// *************************************************************************** *
// *                                                                           *
// * Description:         CANDB File                                           *
// * Generated at:        2025-01-24 12:56                                     *
// * System:              SDB22436                                             *
// * Variant:             L946_ADCU9_ZCUDM                                     *
// * Network:             BodyExposedCAN                                       *
// *                                                                           *
// *************************************************************************** *
VERSION "BodyExposedCAN"

NS_ :

BS_ :

BU_ :  ETC HCML HCMR ZCUD

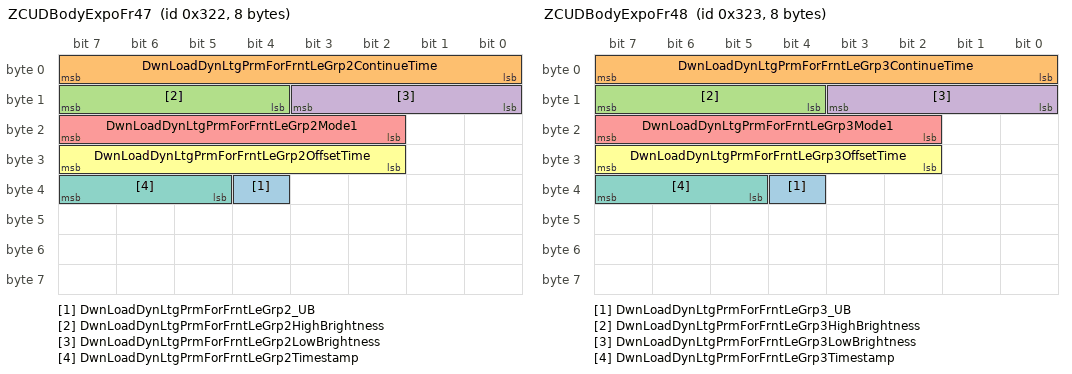
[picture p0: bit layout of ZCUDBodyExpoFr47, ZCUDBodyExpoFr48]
BO_ 802 ZCUDBodyExpoFr47 : 8 ZCUD
 SG_ DwnLoadDynLtgPrmForFrntLeGrp2_UB : 36|1@0+ (1,0) [0|1] "" HCML
 SG_ DwnLoadDynLtgPrmForFrntLeGrp2ContinueTime : 7|8@0+ (1.0,0.0) [0.0|255.0] "Unitless" HCML
 SG_ DwnLoadDynLtgPrmForFrntLeGrp2HighBrightness : 15|4@0+ (1.0,0.0) [0.0|10.0] "Unitless" HCML
 SG_ DwnLoadDynLtgPrmForFrntLeGrp2LowBrightness : 11|4@0+ (1.0,0.0) [0.0|10.0] "Unitless" HCML
 SG_ DwnLoadDynLtgPrmForFrntLeGrp2Mode1 : 23|6@0+ (1,0) [0|63] "" HCML
 SG_ DwnLoadDynLtgPrmForFrntLeGrp2OffsetTime : 31|6@0+ (1.0,0.0) [0.0|63.0] "Unitless" HCML
 SG_ DwnLoadDynLtgPrmForFrntLeGrp2Timestamp : 39|3@0+ (1.0,0.0) [0.0|7.0] "Unitless" HCML

BO_ 803 ZCUDBodyExpoFr48 : 8 ZCUD
 SG_ DwnLoadDynLtgPrmForFrntLeGrp3_UB : 36|1@0+ (1,0) [0|1] "" HCML
 SG_ DwnLoadDynLtgPrmForFrntLeGrp3ContinueTime : 7|8@0+ (1.0,0.0) [0.0|255.0] "Unitless" HCML
 SG_ DwnLoadDynLtgPrmForFrntLeGrp3HighBrightness : 15|4@0+ (1.0,0.0) [0.0|10.0] "Unitless" HCML
 SG_ DwnLoadDynLtgPrmForFrntLeGrp3LowBrightness : 11|4@0+ (1.0,0.0) [0.0|10.0] "Unitless" HCML
 SG_ DwnLoadDynLtgPrmForFrntLeGrp3Mode1 : 23|6@0+ (1,0) [0|63] "" HCML
 SG_ DwnLoadDynLtgPrmForFrntLeGrp3OffsetTime : 31|6@0+ (1.0,0.0) [0.0|63.0] "Unitless" HCML
 SG_ DwnLoadDynLtgPrmForFrntLeGrp3Timestamp : 39|3@0+ (1.0,0.0) [0.0|7.0] "Unitless" HCML

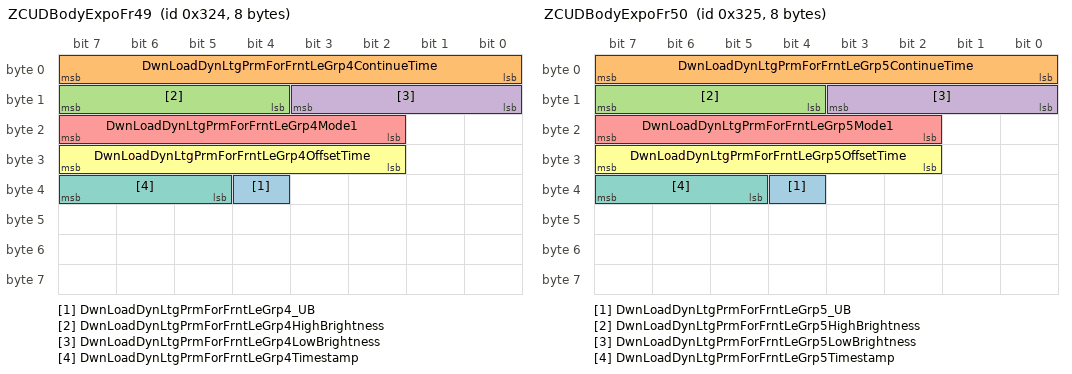
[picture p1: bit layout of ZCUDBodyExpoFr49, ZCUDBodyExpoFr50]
BO_ 804 ZCUDBodyExpoFr49 : 8 ZCUD
 SG_ DwnLoadDynLtgPrmForFrntLeGrp4_UB : 36|1@0+ (1,0) [0|1] "" HCML
 SG_ DwnLoadDynLtgPrmForFrntLeGrp4ContinueTime : 7|8@0+ (1.0,0.0) [0.0|255.0] "Unitless" HCML
 SG_ DwnLoadDynLtgPrmForFrntLeGrp4HighBrightness : 15|4@0+ (1.0,0.0) [0.0|10.0] "Unitless" HCML
 SG_ DwnLoadDynLtgPrmForFrntLeGrp4LowBrightness : 11|4@0+ (1.0,0.0) [0.0|10.0] "Unitless" HCML
 SG_ DwnLoadDynLtgPrmForFrntLeGrp4Mode1 : 23|6@0+ (1,0) [0|63] "" HCML
 SG_ DwnLoadDynLtgPrmForFrntLeGrp4OffsetTime : 31|6@0+ (1.0,0.0) [0.0|63.0] "Unitless" HCML
 SG_ DwnLoadDynLtgPrmForFrntLeGrp4Timestamp : 39|3@0+ (1.0,0.0) [0.0|7.0] "Unitless" HCML

BO_ 805 ZCUDBodyExpoFr50 : 8 ZCUD
 SG_ DwnLoadDynLtgPrmForFrntLeGrp5_UB : 36|1@0+ (1,0) [0|1] "" HCML
 SG_ DwnLoadDynLtgPrmForFrntLeGrp5ContinueTime : 7|8@0+ (1.0,0.0) [0.0|255.0] "Unitless" HCML
 SG_ DwnLoadDynLtgPrmForFrntLeGrp5HighBrightness : 15|4@0+ (1.0,0.0) [0.0|10.0] "Unitless" HCML
 SG_ DwnLoadDynLtgPrmForFrntLeGrp5LowBrightness : 11|4@0+ (1.0,0.0) [0.0|10.0] "Unitless" HCML
 SG_ DwnLoadDynLtgPrmForFrntLeGrp5Mode1 : 23|6@0+ (1,0) [0|63] "" HCML
 SG_ DwnLoadDynLtgPrmForFrntLeGrp5OffsetTime : 31|6@0+ (1.0,0.0) [0.0|63.0] "Unitless" HCML
 SG_ DwnLoadDynLtgPrmForFrntLeGrp5Timestamp : 39|3@0+ (1.0,0.0) [0.0|7.0] "Unitless" HCML

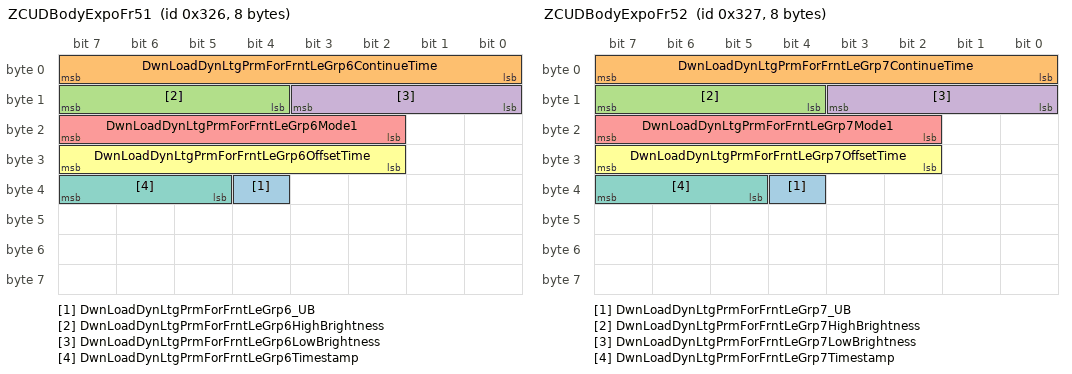
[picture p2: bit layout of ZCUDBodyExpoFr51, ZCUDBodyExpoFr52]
BO_ 806 ZCUDBodyExpoFr51 : 8 ZCUD
 SG_ DwnLoadDynLtgPrmForFrntLeGrp6_UB : 36|1@0+ (1,0) [0|1] "" HCML
 SG_ DwnLoadDynLtgPrmForFrntLeGrp6ContinueTime : 7|8@0+ (1.0,0.0) [0.0|255.0] "Unitless" HCML
 SG_ DwnLoadDynLtgPrmForFrntLeGrp6HighBrightness : 15|4@0+ (1.0,0.0) [0.0|10.0] "Unitless" HCML
 SG_ DwnLoadDynLtgPrmForFrntLeGrp6LowBrightness : 11|4@0+ (1.0,0.0) [0.0|10.0] "Unitless" HCML
 SG_ DwnLoadDynLtgPrmForFrntLeGrp6Mode1 : 23|6@0+ (1,0) [0|63] "" HCML
 SG_ DwnLoadDynLtgPrmForFrntLeGrp6OffsetTime : 31|6@0+ (1.0,0.0) [0.0|63.0] "Unitless" HCML
 SG_ DwnLoadDynLtgPrmForFrntLeGrp6Timestamp : 39|3@0+ (1.0,0.0) [0.0|7.0] "Unitless" HCML

BO_ 807 ZCUDBodyExpoFr52 : 8 ZCUD
 SG_ DwnLoadDynLtgPrmForFrntLeGrp7_UB : 36|1@0+ (1,0) [0|1] "" HCML
 SG_ DwnLoadDynLtgPrmForFrntLeGrp7ContinueTime : 7|8@0+ (1.0,0.0) [0.0|255.0] "Unitless" HCML
 SG_ DwnLoadDynLtgPrmForFrntLeGrp7HighBrightness : 15|4@0+ (1.0,0.0) [0.0|10.0] "Unitless" HCML
 SG_ DwnLoadDynLtgPrmForFrntLeGrp7LowBrightness : 11|4@0+ (1.0,0.0) [0.0|10.0] "Unitless" HCML
 SG_ DwnLoadDynLtgPrmForFrntLeGrp7Mode1 : 23|6@0+ (1,0) [0|63] "" HCML
 SG_ DwnLoadDynLtgPrmForFrntLeGrp7OffsetTime : 31|6@0+ (1.0,0.0) [0.0|63.0] "Unitless" HCML
 SG_ DwnLoadDynLtgPrmForFrntLeGrp7Timestamp : 39|3@0+ (1.0,0.0) [0.0|7.0] "Unitless" HCML

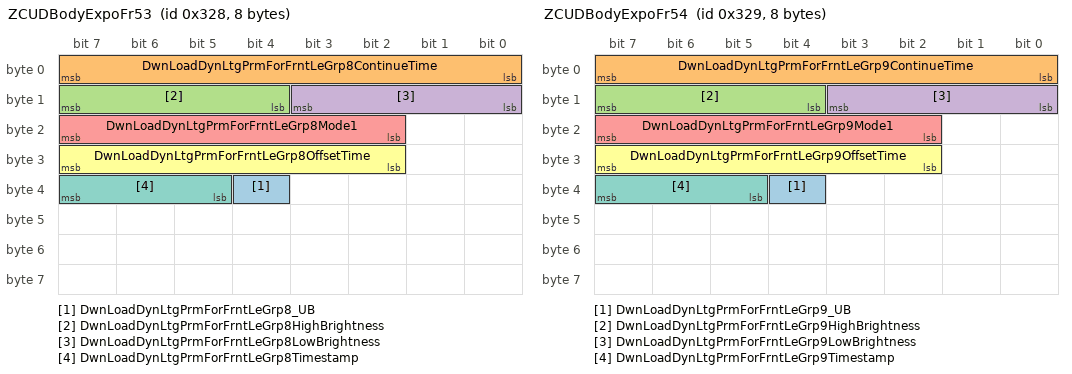
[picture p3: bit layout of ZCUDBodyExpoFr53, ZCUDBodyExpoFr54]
BO_ 808 ZCUDBodyExpoFr53 : 8 ZCUD
 SG_ DwnLoadDynLtgPrmForFrntLeGrp8_UB : 36|1@0+ (1,0) [0|1] "" HCML
 SG_ DwnLoadDynLtgPrmForFrntLeGrp8ContinueTime : 7|8@0+ (1.0,0.0) [0.0|255.0] "Unitless" HCML
 SG_ DwnLoadDynLtgPrmForFrntLeGrp8HighBrightness : 15|4@0+ (1.0,0.0) [0.0|10.0] "Unitless" HCML
 SG_ DwnLoadDynLtgPrmForFrntLeGrp8LowBrightness : 11|4@0+ (1.0,0.0) [0.0|10.0] "Unitless" HCML
 SG_ DwnLoadDynLtgPrmForFrntLeGrp8Mode1 : 23|6@0+ (1,0) [0|63] "" HCML
 SG_ DwnLoadDynLtgPrmForFrntLeGrp8OffsetTime : 31|6@0+ (1.0,0.0) [0.0|63.0] "Unitless" HCML
 SG_ DwnLoadDynLtgPrmForFrntLeGrp8Timestamp : 39|3@0+ (1.0,0.0) [0.0|7.0] "Unitless" HCML

BO_ 809 ZCUDBodyExpoFr54 : 8 ZCUD
 SG_ DwnLoadDynLtgPrmForFrntLeGrp9_UB : 36|1@0+ (1,0) [0|1] "" HCML
 SG_ DwnLoadDynLtgPrmForFrntLeGrp9ContinueTime : 7|8@0+ (1.0,0.0) [0.0|255.0] "Unitless" HCML
 SG_ DwnLoadDynLtgPrmForFrntLeGrp9HighBrightness : 15|4@0+ (1.0,0.0) [0.0|10.0] "Unitless" HCML
 SG_ DwnLoadDynLtgPrmForFrntLeGrp9LowBrightness : 11|4@0+ (1.0,0.0) [0.0|10.0] "Unitless" HCML
 SG_ DwnLoadDynLtgPrmForFrntLeGrp9Mode1 : 23|6@0+ (1,0) [0|63] "" HCML
 SG_ DwnLoadDynLtgPrmForFrntLeGrp9OffsetTime : 31|6@0+ (1.0,0.0) [0.0|63.0] "Unitless" HCML
 SG_ DwnLoadDynLtgPrmForFrntLeGrp9Timestamp : 39|3@0+ (1.0,0.0) [0.0|7.0] "Unitless" HCML

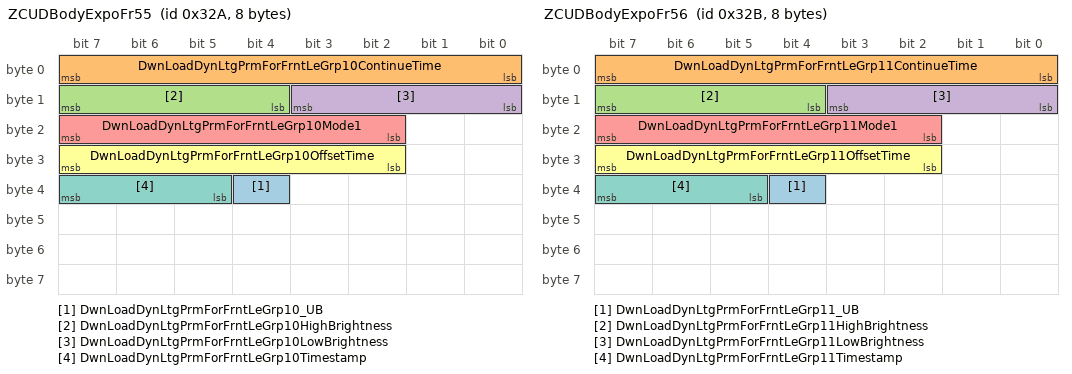
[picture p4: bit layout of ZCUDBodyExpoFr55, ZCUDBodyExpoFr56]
BO_ 810 ZCUDBodyExpoFr55 : 8 ZCUD
 SG_ DwnLoadDynLtgPrmForFrntLeGrp10_UB : 36|1@0+ (1,0) [0|1] "" HCML
 SG_ DwnLoadDynLtgPrmForFrntLeGrp10ContinueTime : 7|8@0+ (1.0,0.0) [0.0|255.0] "Unitless" HCML
 SG_ DwnLoadDynLtgPrmForFrntLeGrp10HighBrightness : 15|4@0+ (1.0,0.0) [0.0|10.0] "Unitless" HCML
 SG_ DwnLoadDynLtgPrmForFrntLeGrp10LowBrightness : 11|4@0+ (1.0,0.0) [0.0|10.0] "Unitless" HCML
 SG_ DwnLoadDynLtgPrmForFrntLeGrp10Mode1 : 23|6@0+ (1,0) [0|63] "" HCML
 SG_ DwnLoadDynLtgPrmForFrntLeGrp10OffsetTime : 31|6@0+ (1.0,0.0) [0.0|63.0] "Unitless" HCML
 SG_ DwnLoadDynLtgPrmForFrntLeGrp10Timestamp : 39|3@0+ (1.0,0.0) [0.0|7.0] "Unitless" HCML

BO_ 811 ZCUDBodyExpoFr56 : 8 ZCUD
 SG_ DwnLoadDynLtgPrmForFrntLeGrp11_UB : 36|1@0+ (1,0) [0|1] "" HCML
 SG_ DwnLoadDynLtgPrmForFrntLeGrp11ContinueTime : 7|8@0+ (1.0,0.0) [0.0|255.0] "Unitless" HCML
 SG_ DwnLoadDynLtgPrmForFrntLeGrp11HighBrightness : 15|4@0+ (1.0,0.0) [0.0|10.0] "Unitless" HCML
 SG_ DwnLoadDynLtgPrmForFrntLeGrp11LowBrightness : 11|4@0+ (1.0,0.0) [0.0|10.0] "Unitless" HCML
 SG_ DwnLoadDynLtgPrmForFrntLeGrp11Mode1 : 23|6@0+ (1,0) [0|63] "" HCML
 SG_ DwnLoadDynLtgPrmForFrntLeGrp11OffsetTime : 31|6@0+ (1.0,0.0) [0.0|63.0] "Unitless" HCML
 SG_ DwnLoadDynLtgPrmForFrntLeGrp11Timestamp : 39|3@0+ (1.0,0.0) [0.0|7.0] "Unitless" HCML

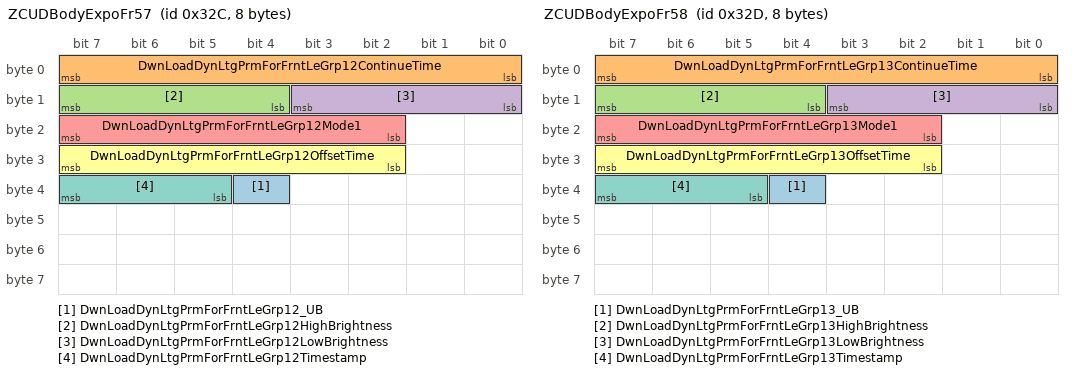
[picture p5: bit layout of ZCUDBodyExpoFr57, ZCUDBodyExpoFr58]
BO_ 812 ZCUDBodyExpoFr57 : 8 ZCUD
 SG_ DwnLoadDynLtgPrmForFrntLeGrp12_UB : 36|1@0+ (1,0) [0|1] "" HCML
 SG_ DwnLoadDynLtgPrmForFrntLeGrp12ContinueTime : 7|8@0+ (1.0,0.0) [0.0|255.0] "Unitless" HCML
 SG_ DwnLoadDynLtgPrmForFrntLeGrp12HighBrightness : 15|4@0+ (1.0,0.0) [0.0|10.0] "Unitless" HCML
 SG_ DwnLoadDynLtgPrmForFrntLeGrp12LowBrightness : 11|4@0+ (1.0,0.0) [0.0|10.0] "Unitless" HCML
 SG_ DwnLoadDynLtgPrmForFrntLeGrp12Mode1 : 23|6@0+ (1,0) [0|63] "" HCML
 SG_ DwnLoadDynLtgPrmForFrntLeGrp12OffsetTime : 31|6@0+ (1.0,0.0) [0.0|63.0] "Unitless" HCML
 SG_ DwnLoadDynLtgPrmForFrntLeGrp12Timestamp : 39|3@0+ (1.0,0.0) [0.0|7.0] "Unitless" HCML

BO_ 813 ZCUDBodyExpoFr58 : 8 ZCUD
 SG_ DwnLoadDynLtgPrmForFrntLeGrp13_UB : 36|1@0+ (1,0) [0|1] "" HCML
 SG_ DwnLoadDynLtgPrmForFrntLeGrp13ContinueTime : 7|8@0+ (1.0,0.0) [0.0|255.0] "Unitless" HCML
 SG_ DwnLoadDynLtgPrmForFrntLeGrp13HighBrightness : 15|4@0+ (1.0,0.0) [0.0|10.0] "Unitless" HCML
 SG_ DwnLoadDynLtgPrmForFrntLeGrp13LowBrightness : 11|4@0+ (1.0,0.0) [0.0|10.0] "Unitless" HCML
 SG_ DwnLoadDynLtgPrmForFrntLeGrp13Mode1 : 23|6@0+ (1,0) [0|63] "" HCML
 SG_ DwnLoadDynLtgPrmForFrntLeGrp13OffsetTime : 31|6@0+ (1.0,0.0) [0.0|63.0] "Unitless" HCML
 SG_ DwnLoadDynLtgPrmForFrntLeGrp13Timestamp : 39|3@0+ (1.0,0.0) [0.0|7.0] "Unitless" HCML

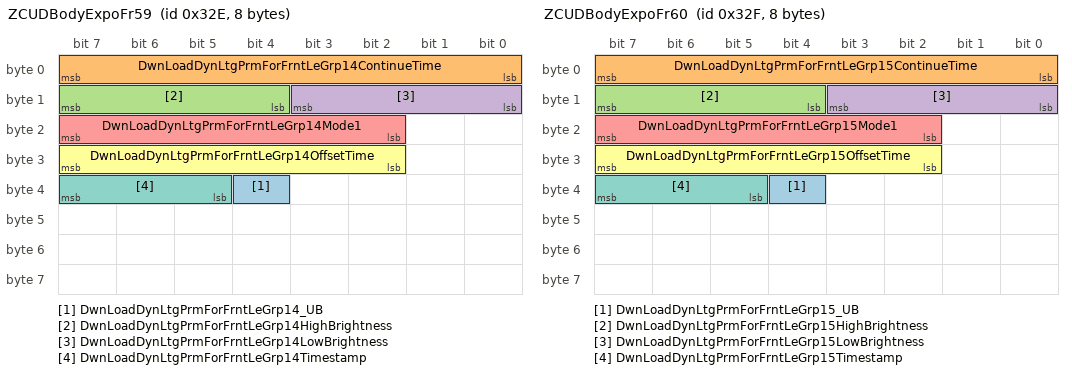
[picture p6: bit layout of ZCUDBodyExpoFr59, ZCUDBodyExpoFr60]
BO_ 814 ZCUDBodyExpoFr59 : 8 ZCUD
 SG_ DwnLoadDynLtgPrmForFrntLeGrp14_UB : 36|1@0+ (1,0) [0|1] "" HCML
 SG_ DwnLoadDynLtgPrmForFrntLeGrp14ContinueTime : 7|8@0+ (1.0,0.0) [0.0|255.0] "Unitless" HCML
 SG_ DwnLoadDynLtgPrmForFrntLeGrp14HighBrightness : 15|4@0+ (1.0,0.0) [0.0|10.0] "Unitless" HCML
 SG_ DwnLoadDynLtgPrmForFrntLeGrp14LowBrightness : 11|4@0+ (1.0,0.0) [0.0|10.0] "Unitless" HCML
 SG_ DwnLoadDynLtgPrmForFrntLeGrp14Mode1 : 23|6@0+ (1,0) [0|63] "" HCML
 SG_ DwnLoadDynLtgPrmForFrntLeGrp14OffsetTime : 31|6@0+ (1.0,0.0) [0.0|63.0] "Unitless" HCML
 SG_ DwnLoadDynLtgPrmForFrntLeGrp14Timestamp : 39|3@0+ (1.0,0.0) [0.0|7.0] "Unitless" HCML

BO_ 815 ZCUDBodyExpoFr60 : 8 ZCUD
 SG_ DwnLoadDynLtgPrmForFrntLeGrp15_UB : 36|1@0+ (1,0) [0|1] "" HCML
 SG_ DwnLoadDynLtgPrmForFrntLeGrp15ContinueTime : 7|8@0+ (1.0,0.0) [0.0|255.0] "Unitless" HCML
 SG_ DwnLoadDynLtgPrmForFrntLeGrp15HighBrightness : 15|4@0+ (1.0,0.0) [0.0|10.0] "Unitless" HCML
 SG_ DwnLoadDynLtgPrmForFrntLeGrp15LowBrightness : 11|4@0+ (1.0,0.0) [0.0|10.0] "Unitless" HCML
 SG_ DwnLoadDynLtgPrmForFrntLeGrp15Mode1 : 23|6@0+ (1,0) [0|63] "" HCML
 SG_ DwnLoadDynLtgPrmForFrntLeGrp15OffsetTime : 31|6@0+ (1.0,0.0) [0.0|63.0] "Unitless" HCML
 SG_ DwnLoadDynLtgPrmForFrntLeGrp15Timestamp : 39|3@0+ (1.0,0.0) [0.0|7.0] "Unitless" HCML

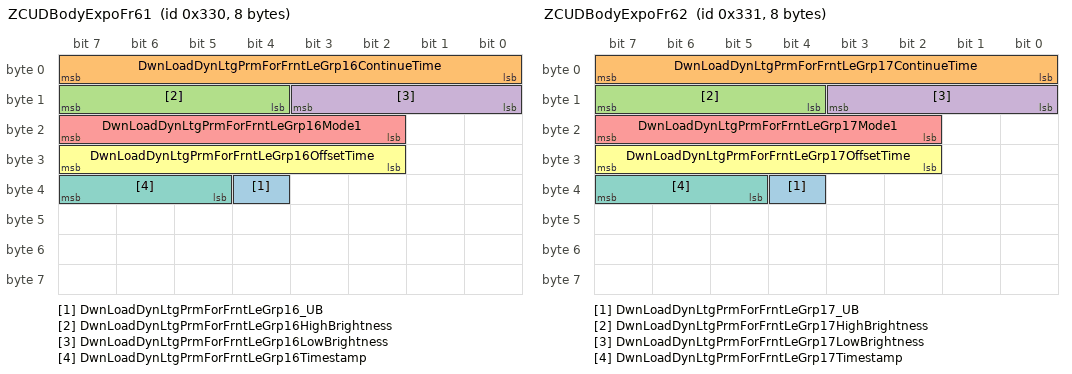
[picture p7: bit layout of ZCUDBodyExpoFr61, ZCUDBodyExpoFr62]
BO_ 816 ZCUDBodyExpoFr61 : 8 ZCUD
 SG_ DwnLoadDynLtgPrmForFrntLeGrp16_UB : 36|1@0+ (1,0) [0|1] "" HCML
 SG_ DwnLoadDynLtgPrmForFrntLeGrp16ContinueTime : 7|8@0+ (1.0,0.0) [0.0|255.0] "Unitless" HCML
 SG_ DwnLoadDynLtgPrmForFrntLeGrp16HighBrightness : 15|4@0+ (1.0,0.0) [0.0|10.0] "Unitless" HCML
 SG_ DwnLoadDynLtgPrmForFrntLeGrp16LowBrightness : 11|4@0+ (1.0,0.0) [0.0|10.0] "Unitless" HCML
 SG_ DwnLoadDynLtgPrmForFrntLeGrp16Mode1 : 23|6@0+ (1,0) [0|63] "" HCML
 SG_ DwnLoadDynLtgPrmForFrntLeGrp16OffsetTime : 31|6@0+ (1.0,0.0) [0.0|63.0] "Unitless" HCML
 SG_ DwnLoadDynLtgPrmForFrntLeGrp16Timestamp : 39|3@0+ (1.0,0.0) [0.0|7.0] "Unitless" HCML

BO_ 817 ZCUDBodyExpoFr62 : 8 ZCUD
 SG_ DwnLoadDynLtgPrmForFrntLeGrp17_UB : 36|1@0+ (1,0) [0|1] "" HCML
 SG_ DwnLoadDynLtgPrmForFrntLeGrp17ContinueTime : 7|8@0+ (1.0,0.0) [0.0|255.0] "Unitless" HCML
 SG_ DwnLoadDynLtgPrmForFrntLeGrp17HighBrightness : 15|4@0+ (1.0,0.0) [0.0|10.0] "Unitless" HCML
 SG_ DwnLoadDynLtgPrmForFrntLeGrp17LowBrightness : 11|4@0+ (1.0,0.0) [0.0|10.0] "Unitless" HCML
 SG_ DwnLoadDynLtgPrmForFrntLeGrp17Mode1 : 23|6@0+ (1,0) [0|63] "" HCML
 SG_ DwnLoadDynLtgPrmForFrntLeGrp17OffsetTime : 31|6@0+ (1.0,0.0) [0.0|63.0] "Unitless" HCML
 SG_ DwnLoadDynLtgPrmForFrntLeGrp17Timestamp : 39|3@0+ (1.0,0.0) [0.0|7.0] "Unitless" HCML

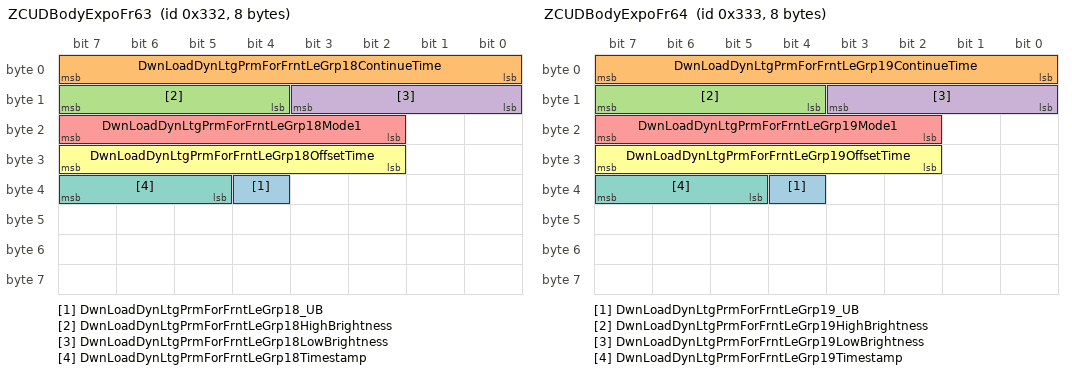
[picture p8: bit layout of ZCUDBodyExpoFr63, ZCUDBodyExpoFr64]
BO_ 818 ZCUDBodyExpoFr63 : 8 ZCUD
 SG_ DwnLoadDynLtgPrmForFrntLeGrp18_UB : 36|1@0+ (1,0) [0|1] "" HCML
 SG_ DwnLoadDynLtgPrmForFrntLeGrp18ContinueTime : 7|8@0+ (1.0,0.0) [0.0|255.0] "Unitless" HCML
 SG_ DwnLoadDynLtgPrmForFrntLeGrp18HighBrightness : 15|4@0+ (1.0,0.0) [0.0|10.0] "Unitless" HCML
 SG_ DwnLoadDynLtgPrmForFrntLeGrp18LowBrightness : 11|4@0+ (1.0,0.0) [0.0|10.0] "Unitless" HCML
 SG_ DwnLoadDynLtgPrmForFrntLeGrp18Mode1 : 23|6@0+ (1,0) [0|63] "" HCML
 SG_ DwnLoadDynLtgPrmForFrntLeGrp18OffsetTime : 31|6@0+ (1.0,0.0) [0.0|63.0] "Unitless" HCML
 SG_ DwnLoadDynLtgPrmForFrntLeGrp18Timestamp : 39|3@0+ (1.0,0.0) [0.0|7.0] "Unitless" HCML

BO_ 819 ZCUDBodyExpoFr64 : 8 ZCUD
 SG_ DwnLoadDynLtgPrmForFrntLeGrp19_UB : 36|1@0+ (1,0) [0|1] "" HCML
 SG_ DwnLoadDynLtgPrmForFrntLeGrp19ContinueTime : 7|8@0+ (1.0,0.0) [0.0|255.0] "Unitless" HCML
 SG_ DwnLoadDynLtgPrmForFrntLeGrp19HighBrightness : 15|4@0+ (1.0,0.0) [0.0|10.0] "Unitless" HCML
 SG_ DwnLoadDynLtgPrmForFrntLeGrp19LowBrightness : 11|4@0+ (1.0,0.0) [0.0|10.0] "Unitless" HCML
 SG_ DwnLoadDynLtgPrmForFrntLeGrp19Mode1 : 23|6@0+ (1,0) [0|63] "" HCML
 SG_ DwnLoadDynLtgPrmForFrntLeGrp19OffsetTime : 31|6@0+ (1.0,0.0) [0.0|63.0] "Unitless" HCML
 SG_ DwnLoadDynLtgPrmForFrntLeGrp19Timestamp : 39|3@0+ (1.0,0.0) [0.0|7.0] "Unitless" HCML

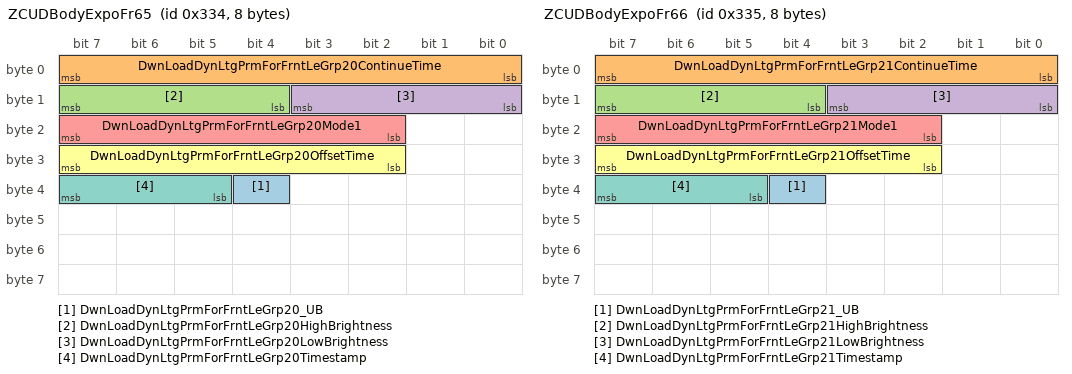
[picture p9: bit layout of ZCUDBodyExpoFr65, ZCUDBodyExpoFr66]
BO_ 820 ZCUDBodyExpoFr65 : 8 ZCUD
 SG_ DwnLoadDynLtgPrmForFrntLeGrp20_UB : 36|1@0+ (1,0) [0|1] "" HCML
 SG_ DwnLoadDynLtgPrmForFrntLeGrp20ContinueTime : 7|8@0+ (1.0,0.0) [0.0|255.0] "Unitless" HCML
 SG_ DwnLoadDynLtgPrmForFrntLeGrp20HighBrightness : 15|4@0+ (1.0,0.0) [0.0|10.0] "Unitless" HCML
 SG_ DwnLoadDynLtgPrmForFrntLeGrp20LowBrightness : 11|4@0+ (1.0,0.0) [0.0|10.0] "Unitless" HCML
 SG_ DwnLoadDynLtgPrmForFrntLeGrp20Mode1 : 23|6@0+ (1,0) [0|63] "" HCML
 SG_ DwnLoadDynLtgPrmForFrntLeGrp20OffsetTime : 31|6@0+ (1.0,0.0) [0.0|63.0] "Unitless" HCML
 SG_ DwnLoadDynLtgPrmForFrntLeGrp20Timestamp : 39|3@0+ (1.0,0.0) [0.0|7.0] "Unitless" HCML

BO_ 821 ZCUDBodyExpoFr66 : 8 ZCUD
 SG_ DwnLoadDynLtgPrmForFrntLeGrp21_UB : 36|1@0+ (1,0) [0|1] "" HCML
 SG_ DwnLoadDynLtgPrmForFrntLeGrp21ContinueTime : 7|8@0+ (1.0,0.0) [0.0|255.0] "Unitless" HCML
 SG_ DwnLoadDynLtgPrmForFrntLeGrp21HighBrightness : 15|4@0+ (1.0,0.0) [0.0|10.0] "Unitless" HCML
 SG_ DwnLoadDynLtgPrmForFrntLeGrp21LowBrightness : 11|4@0+ (1.0,0.0) [0.0|10.0] "Unitless" HCML
 SG_ DwnLoadDynLtgPrmForFrntLeGrp21Mode1 : 23|6@0+ (1,0) [0|63] "" HCML
 SG_ DwnLoadDynLtgPrmForFrntLeGrp21OffsetTime : 31|6@0+ (1.0,0.0) [0.0|63.0] "Unitless" HCML
 SG_ DwnLoadDynLtgPrmForFrntLeGrp21Timestamp : 39|3@0+ (1.0,0.0) [0.0|7.0] "Unitless" HCML

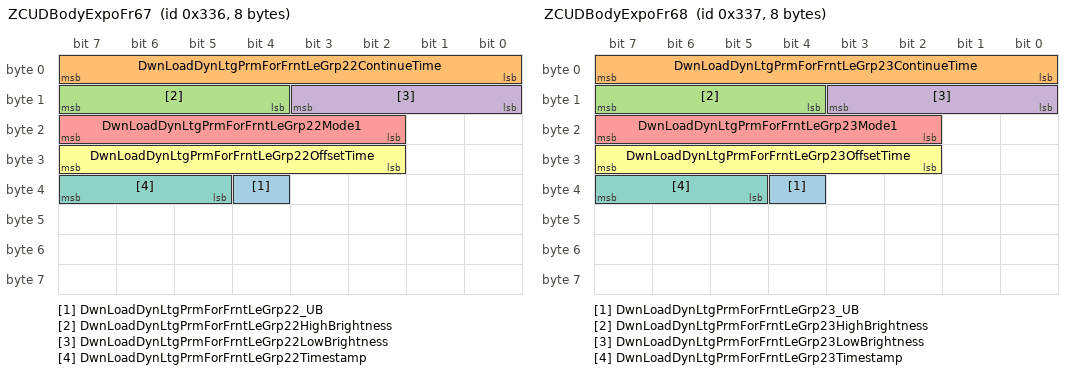
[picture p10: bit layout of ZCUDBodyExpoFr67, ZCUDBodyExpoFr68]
BO_ 822 ZCUDBodyExpoFr67 : 8 ZCUD
 SG_ DwnLoadDynLtgPrmForFrntLeGrp22_UB : 36|1@0+ (1,0) [0|1] "" HCML
 SG_ DwnLoadDynLtgPrmForFrntLeGrp22ContinueTime : 7|8@0+ (1.0,0.0) [0.0|255.0] "Unitless" HCML
 SG_ DwnLoadDynLtgPrmForFrntLeGrp22HighBrightness : 15|4@0+ (1.0,0.0) [0.0|10.0] "Unitless" HCML
 SG_ DwnLoadDynLtgPrmForFrntLeGrp22LowBrightness : 11|4@0+ (1.0,0.0) [0.0|10.0] "Unitless" HCML
 SG_ DwnLoadDynLtgPrmForFrntLeGrp22Mode1 : 23|6@0+ (1,0) [0|63] "" HCML
 SG_ DwnLoadDynLtgPrmForFrntLeGrp22OffsetTime : 31|6@0+ (1.0,0.0) [0.0|63.0] "Unitless" HCML
 SG_ DwnLoadDynLtgPrmForFrntLeGrp22Timestamp : 39|3@0+ (1.0,0.0) [0.0|7.0] "Unitless" HCML

BO_ 823 ZCUDBodyExpoFr68 : 8 ZCUD
 SG_ DwnLoadDynLtgPrmForFrntLeGrp23_UB : 36|1@0+ (1,0) [0|1] "" HCML
 SG_ DwnLoadDynLtgPrmForFrntLeGrp23ContinueTime : 7|8@0+ (1.0,0.0) [0.0|255.0] "Unitless" HCML
 SG_ DwnLoadDynLtgPrmForFrntLeGrp23HighBrightness : 15|4@0+ (1.0,0.0) [0.0|10.0] "Unitless" HCML
 SG_ DwnLoadDynLtgPrmForFrntLeGrp23LowBrightness : 11|4@0+ (1.0,0.0) [0.0|10.0] "Unitless" HCML
 SG_ DwnLoadDynLtgPrmForFrntLeGrp23Mode1 : 23|6@0+ (1,0) [0|63] "" HCML
 SG_ DwnLoadDynLtgPrmForFrntLeGrp23OffsetTime : 31|6@0+ (1.0,0.0) [0.0|63.0] "Unitless" HCML
 SG_ DwnLoadDynLtgPrmForFrntLeGrp23Timestamp : 39|3@0+ (1.0,0.0) [0.0|7.0] "Unitless" HCML

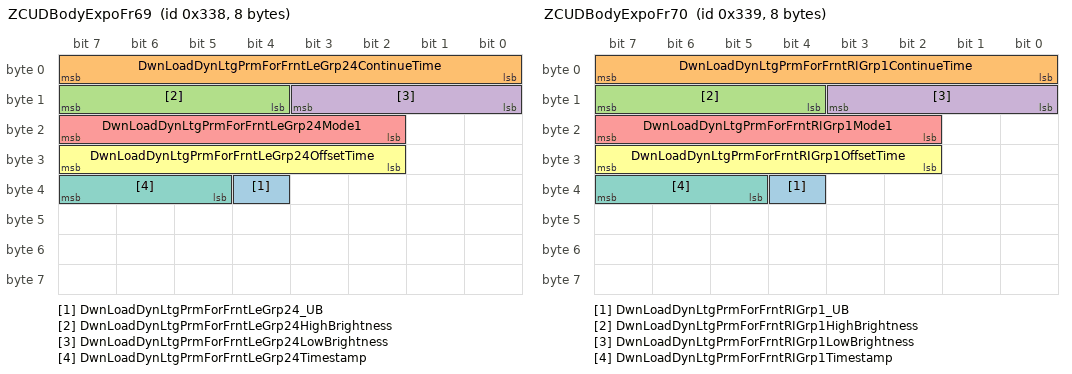
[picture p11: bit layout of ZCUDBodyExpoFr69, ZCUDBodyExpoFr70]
BO_ 824 ZCUDBodyExpoFr69 : 8 ZCUD
 SG_ DwnLoadDynLtgPrmForFrntLeGrp24_UB : 36|1@0+ (1,0) [0|1] "" HCML
 SG_ DwnLoadDynLtgPrmForFrntLeGrp24ContinueTime : 7|8@0+ (1.0,0.0) [0.0|255.0] "Unitless" HCML
 SG_ DwnLoadDynLtgPrmForFrntLeGrp24HighBrightness : 15|4@0+ (1.0,0.0) [0.0|10.0] "Unitless" HCML
 SG_ DwnLoadDynLtgPrmForFrntLeGrp24LowBrightness : 11|4@0+ (1.0,0.0) [0.0|10.0] "Unitless" HCML
 SG_ DwnLoadDynLtgPrmForFrntLeGrp24Mode1 : 23|6@0+ (1,0) [0|63] "" HCML
 SG_ DwnLoadDynLtgPrmForFrntLeGrp24OffsetTime : 31|6@0+ (1.0,0.0) [0.0|63.0] "Unitless" HCML
 SG_ DwnLoadDynLtgPrmForFrntLeGrp24Timestamp : 39|3@0+ (1.0,0.0) [0.0|7.0] "Unitless" HCML

BO_ 825 ZCUDBodyExpoFr70 : 8 ZCUD
 SG_ DwnLoadDynLtgPrmForFrntRIGrp1_UB : 36|1@0+ (1,0) [0|1] "" HCMR
 SG_ DwnLoadDynLtgPrmForFrntRIGrp1ContinueTime : 7|8@0+ (1.0,0.0) [0.0|255.0] "Unitless" HCMR
 SG_ DwnLoadDynLtgPrmForFrntRIGrp1HighBrightness : 15|4@0+ (1.0,0.0) [0.0|10.0] "Unitless" HCMR
 SG_ DwnLoadDynLtgPrmForFrntRIGrp1LowBrightness : 11|4@0+ (1.0,0.0) [0.0|10.0] "Unitless" HCMR
 SG_ DwnLoadDynLtgPrmForFrntRIGrp1Mode1 : 23|6@0+ (1,0) [0|63] "" HCMR
 SG_ DwnLoadDynLtgPrmForFrntRIGrp1OffsetTime : 31|6@0+ (1.0,0.0) [0.0|63.0] "Unitless" HCMR
 SG_ DwnLoadDynLtgPrmForFrntRIGrp1Timestamp : 39|3@0+ (1.0,0.0) [0.0|7.0] "Unitless" HCMR

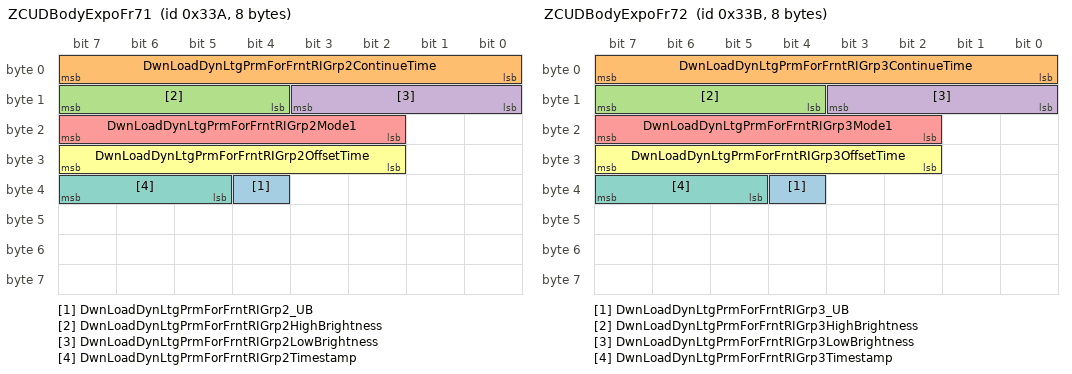
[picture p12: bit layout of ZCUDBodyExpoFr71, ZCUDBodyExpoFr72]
BO_ 826 ZCUDBodyExpoFr71 : 8 ZCUD
 SG_ DwnLoadDynLtgPrmForFrntRIGrp2_UB : 36|1@0+ (1,0) [0|1] "" HCMR
 SG_ DwnLoadDynLtgPrmForFrntRIGrp2ContinueTime : 7|8@0+ (1.0,0.0) [0.0|255.0] "Unitless" HCMR
 SG_ DwnLoadDynLtgPrmForFrntRIGrp2HighBrightness : 15|4@0+ (1.0,0.0) [0.0|10.0] "Unitless" HCMR
 SG_ DwnLoadDynLtgPrmForFrntRIGrp2LowBrightness : 11|4@0+ (1.0,0.0) [0.0|10.0] "Unitless" HCMR
 SG_ DwnLoadDynLtgPrmForFrntRIGrp2Mode1 : 23|6@0+ (1,0) [0|63] "" HCMR
 SG_ DwnLoadDynLtgPrmForFrntRIGrp2OffsetTime : 31|6@0+ (1.0,0.0) [0.0|63.0] "Unitless" HCMR
 SG_ DwnLoadDynLtgPrmForFrntRIGrp2Timestamp : 39|3@0+ (1.0,0.0) [0.0|7.0] "Unitless" HCMR

BO_ 827 ZCUDBodyExpoFr72 : 8 ZCUD
 SG_ DwnLoadDynLtgPrmForFrntRIGrp3_UB : 36|1@0+ (1,0) [0|1] "" HCMR
 SG_ DwnLoadDynLtgPrmForFrntRIGrp3ContinueTime : 7|8@0+ (1.0,0.0) [0.0|255.0] "Unitless" HCMR
 SG_ DwnLoadDynLtgPrmForFrntRIGrp3HighBrightness : 15|4@0+ (1.0,0.0) [0.0|10.0] "Unitless" HCMR
 SG_ DwnLoadDynLtgPrmForFrntRIGrp3LowBrightness : 11|4@0+ (1.0,0.0) [0.0|10.0] "Unitless" HCMR
 SG_ DwnLoadDynLtgPrmForFrntRIGrp3Mode1 : 23|6@0+ (1,0) [0|63] "" HCMR
 SG_ DwnLoadDynLtgPrmForFrntRIGrp3OffsetTime : 31|6@0+ (1.0,0.0) [0.0|63.0] "Unitless" HCMR
 SG_ DwnLoadDynLtgPrmForFrntRIGrp3Timestamp : 39|3@0+ (1.0,0.0) [0.0|7.0] "Unitless" HCMR

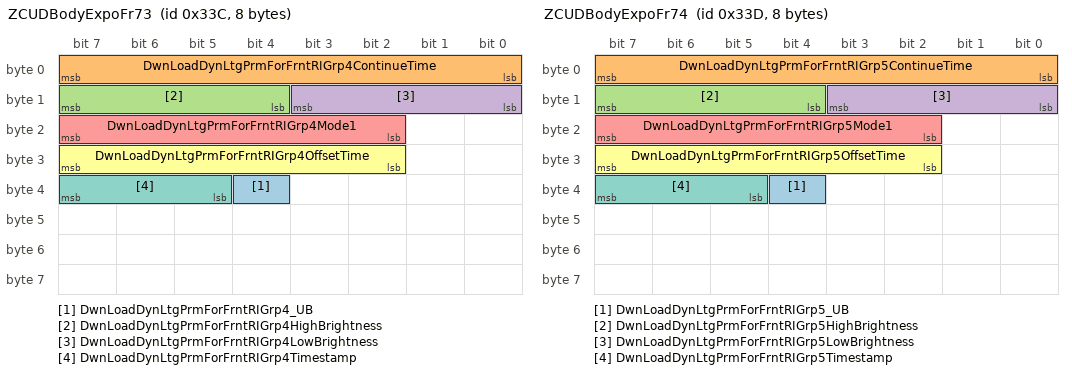
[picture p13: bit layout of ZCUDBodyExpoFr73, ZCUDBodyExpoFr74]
BO_ 828 ZCUDBodyExpoFr73 : 8 ZCUD
 SG_ DwnLoadDynLtgPrmForFrntRIGrp4_UB : 36|1@0+ (1,0) [0|1] "" HCMR
 SG_ DwnLoadDynLtgPrmForFrntRIGrp4ContinueTime : 7|8@0+ (1.0,0.0) [0.0|255.0] "Unitless" HCMR
 SG_ DwnLoadDynLtgPrmForFrntRIGrp4HighBrightness : 15|4@0+ (1.0,0.0) [0.0|10.0] "Unitless" HCMR
 SG_ DwnLoadDynLtgPrmForFrntRIGrp4LowBrightness : 11|4@0+ (1.0,0.0) [0.0|10.0] "Unitless" HCMR
 SG_ DwnLoadDynLtgPrmForFrntRIGrp4Mode1 : 23|6@0+ (1,0) [0|63] "" HCMR
 SG_ DwnLoadDynLtgPrmForFrntRIGrp4OffsetTime : 31|6@0+ (1.0,0.0) [0.0|63.0] "Unitless" HCMR
 SG_ DwnLoadDynLtgPrmForFrntRIGrp4Timestamp : 39|3@0+ (1.0,0.0) [0.0|7.0] "Unitless" HCMR

BO_ 829 ZCUDBodyExpoFr74 : 8 ZCUD
 SG_ DwnLoadDynLtgPrmForFrntRIGrp5_UB : 36|1@0+ (1,0) [0|1] "" HCMR
 SG_ DwnLoadDynLtgPrmForFrntRIGrp5ContinueTime : 7|8@0+ (1.0,0.0) [0.0|255.0] "Unitless" HCMR
 SG_ DwnLoadDynLtgPrmForFrntRIGrp5HighBrightness : 15|4@0+ (1.0,0.0) [0.0|10.0] "Unitless" HCMR
 SG_ DwnLoadDynLtgPrmForFrntRIGrp5LowBrightness : 11|4@0+ (1.0,0.0) [0.0|10.0] "Unitless" HCMR
 SG_ DwnLoadDynLtgPrmForFrntRIGrp5Mode1 : 23|6@0+ (1,0) [0|63] "" HCMR
 SG_ DwnLoadDynLtgPrmForFrntRIGrp5OffsetTime : 31|6@0+ (1.0,0.0) [0.0|63.0] "Unitless" HCMR
 SG_ DwnLoadDynLtgPrmForFrntRIGrp5Timestamp : 39|3@0+ (1.0,0.0) [0.0|7.0] "Unitless" HCMR

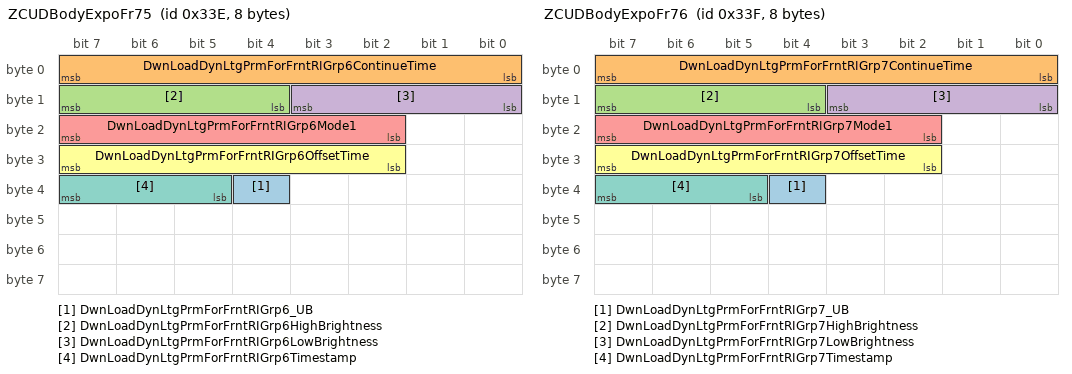
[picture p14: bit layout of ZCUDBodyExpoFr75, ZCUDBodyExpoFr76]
BO_ 830 ZCUDBodyExpoFr75 : 8 ZCUD
 SG_ DwnLoadDynLtgPrmForFrntRIGrp6_UB : 36|1@0+ (1,0) [0|1] "" HCMR
 SG_ DwnLoadDynLtgPrmForFrntRIGrp6ContinueTime : 7|8@0+ (1.0,0.0) [0.0|255.0] "Unitless" HCMR
 SG_ DwnLoadDynLtgPrmForFrntRIGrp6HighBrightness : 15|4@0+ (1.0,0.0) [0.0|10.0] "Unitless" HCMR
 SG_ DwnLoadDynLtgPrmForFrntRIGrp6LowBrightness : 11|4@0+ (1.0,0.0) [0.0|10.0] "Unitless" HCMR
 SG_ DwnLoadDynLtgPrmForFrntRIGrp6Mode1 : 23|6@0+ (1,0) [0|63] "" HCMR
 SG_ DwnLoadDynLtgPrmForFrntRIGrp6OffsetTime : 31|6@0+ (1.0,0.0) [0.0|63.0] "Unitless" HCMR
 SG_ DwnLoadDynLtgPrmForFrntRIGrp6Timestamp : 39|3@0+ (1.0,0.0) [0.0|7.0] "Unitless" HCMR

BO_ 831 ZCUDBodyExpoFr76 : 8 ZCUD
 SG_ DwnLoadDynLtgPrmForFrntRIGrp7_UB : 36|1@0+ (1,0) [0|1] "" HCMR
 SG_ DwnLoadDynLtgPrmForFrntRIGrp7ContinueTime : 7|8@0+ (1.0,0.0) [0.0|255.0] "Unitless" HCMR
 SG_ DwnLoadDynLtgPrmForFrntRIGrp7HighBrightness : 15|4@0+ (1.0,0.0) [0.0|10.0] "Unitless" HCMR
 SG_ DwnLoadDynLtgPrmForFrntRIGrp7LowBrightness : 11|4@0+ (1.0,0.0) [0.0|10.0] "Unitless" HCMR
 SG_ DwnLoadDynLtgPrmForFrntRIGrp7Mode1 : 23|6@0+ (1,0) [0|63] "" HCMR
 SG_ DwnLoadDynLtgPrmForFrntRIGrp7OffsetTime : 31|6@0+ (1.0,0.0) [0.0|63.0] "Unitless" HCMR
 SG_ DwnLoadDynLtgPrmForFrntRIGrp7Timestamp : 39|3@0+ (1.0,0.0) [0.0|7.0] "Unitless" HCMR

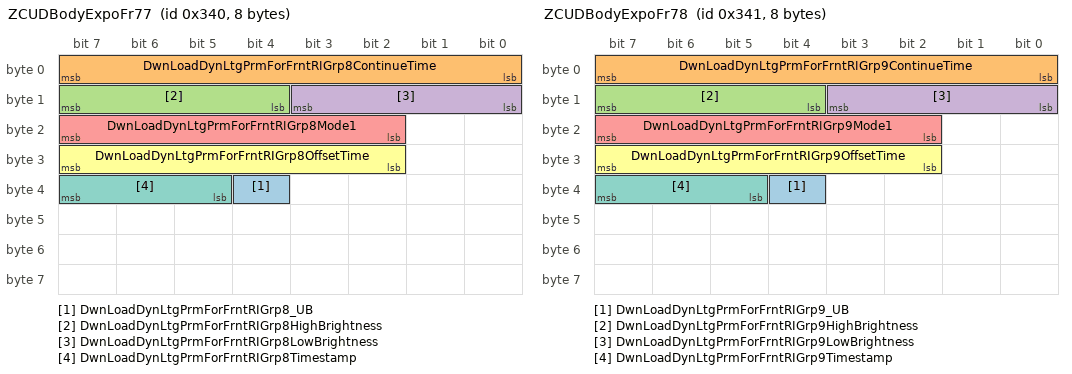
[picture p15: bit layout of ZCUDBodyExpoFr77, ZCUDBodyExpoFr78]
BO_ 832 ZCUDBodyExpoFr77 : 8 ZCUD
 SG_ DwnLoadDynLtgPrmForFrntRIGrp8_UB : 36|1@0+ (1,0) [0|1] "" HCMR
 SG_ DwnLoadDynLtgPrmForFrntRIGrp8ContinueTime : 7|8@0+ (1.0,0.0) [0.0|255.0] "Unitless" HCMR
 SG_ DwnLoadDynLtgPrmForFrntRIGrp8HighBrightness : 15|4@0+ (1.0,0.0) [0.0|10.0] "Unitless" HCMR
 SG_ DwnLoadDynLtgPrmForFrntRIGrp8LowBrightness : 11|4@0+ (1.0,0.0) [0.0|10.0] "Unitless" HCMR
 SG_ DwnLoadDynLtgPrmForFrntRIGrp8Mode1 : 23|6@0+ (1,0) [0|63] "" HCMR
 SG_ DwnLoadDynLtgPrmForFrntRIGrp8OffsetTime : 31|6@0+ (1.0,0.0) [0.0|63.0] "Unitless" HCMR
 SG_ DwnLoadDynLtgPrmForFrntRIGrp8Timestamp : 39|3@0+ (1.0,0.0) [0.0|7.0] "Unitless" HCMR

BO_ 833 ZCUDBodyExpoFr78 : 8 ZCUD
 SG_ DwnLoadDynLtgPrmForFrntRIGrp9_UB : 36|1@0+ (1,0) [0|1] "" HCMR
 SG_ DwnLoadDynLtgPrmForFrntRIGrp9ContinueTime : 7|8@0+ (1.0,0.0) [0.0|255.0] "Unitless" HCMR
 SG_ DwnLoadDynLtgPrmForFrntRIGrp9HighBrightness : 15|4@0+ (1.0,0.0) [0.0|10.0] "Unitless" HCMR
 SG_ DwnLoadDynLtgPrmForFrntRIGrp9LowBrightness : 11|4@0+ (1.0,0.0) [0.0|10.0] "Unitless" HCMR
 SG_ DwnLoadDynLtgPrmForFrntRIGrp9Mode1 : 23|6@0+ (1,0) [0|63] "" HCMR
 SG_ DwnLoadDynLtgPrmForFrntRIGrp9OffsetTime : 31|6@0+ (1.0,0.0) [0.0|63.0] "Unitless" HCMR
 SG_ DwnLoadDynLtgPrmForFrntRIGrp9Timestamp : 39|3@0+ (1.0,0.0) [0.0|7.0] "Unitless" HCMR

BO_ 272 ZCUDBodyExpoFr79 : 8 ZCUD
 SG_ SphDvExtnLg : 50|3@0+ (1,0) [0|7] "" HCML,HCMR
 SG_ SphDvExtnLg_UB : 51|1@0+ (1,0) [0|1] "" HCML,HCMR

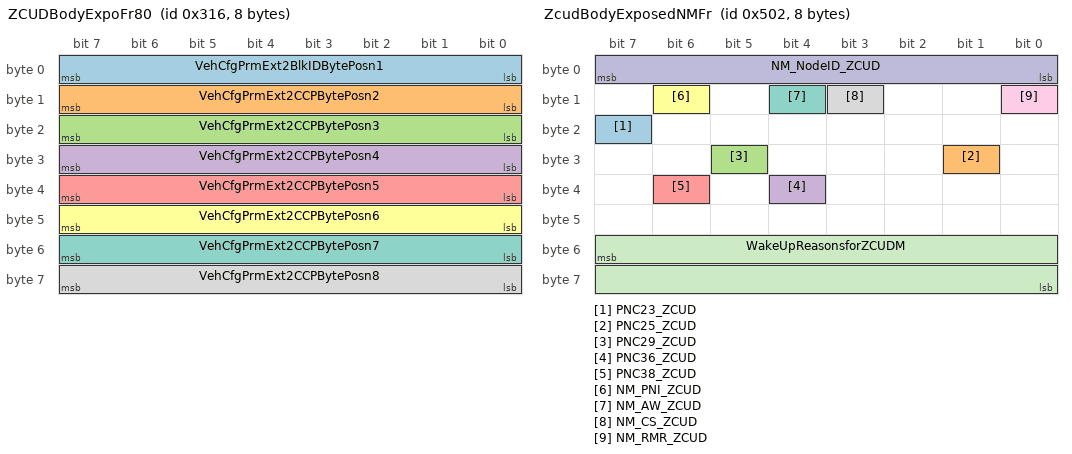
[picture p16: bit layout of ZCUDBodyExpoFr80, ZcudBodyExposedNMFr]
BO_ 790 ZCUDBodyExpoFr80 : 8 ZCUD
 SG_ VehCfgPrmExt2BlkIDBytePosn1 : 7|8@0+ (1.0,0.0) [0.0|255.0] "Unitless" HCML,HCMR
 SG_ VehCfgPrmExt2CCPBytePosn2 : 15|8@0+ (1.0,0.0) [0.0|255.0] "Unitless" HCML,HCMR
 SG_ VehCfgPrmExt2CCPBytePosn3 : 23|8@0+ (1.0,0.0) [0.0|255.0] "Unitless" HCML,HCMR
 SG_ VehCfgPrmExt2CCPBytePosn4 : 31|8@0+ (1.0,0.0) [0.0|255.0] "Unitless" HCML,HCMR
 SG_ VehCfgPrmExt2CCPBytePosn5 : 39|8@0+ (1.0,0.0) [0.0|255.0] "Unitless" HCML,HCMR
 SG_ VehCfgPrmExt2CCPBytePosn6 : 47|8@0+ (1.0,0.0) [0.0|255.0] "Unitless" HCML,HCMR
 SG_ VehCfgPrmExt2CCPBytePosn7 : 55|8@0+ (1.0,0.0) [0.0|255.0] "Unitless" HCML,HCMR
 SG_ VehCfgPrmExt2CCPBytePosn8 : 63|8@0+ (1.0,0.0) [0.0|255.0] "Unitless" HCML,HCMR

BO_ 1282 ZcudBodyExposedNMFr : 8 ZCUD
 SG_ PNC23_ZCUD : 23|1@0+ (1,0) [0|0] "" Vector__XXX
 SG_ PNC25_ZCUD : 25|1@0+ (1,0) [0|0] "" Vector__XXX
 SG_ PNC29_ZCUD : 29|1@0+ (1,0) [0|0] "" Vector__XXX
 SG_ PNC36_ZCUD : 36|1@0+ (1,0) [0|0] "" Vector__XXX
 SG_ PNC38_ZCUD : 38|1@0+ (1,0) [0|0] "" Vector__XXX
 SG_ NM_PNI_ZCUD : 14|1@0+ (1,0) [0|0] "" Vector__XXX
 SG_ NM_AW_ZCUD : 12|1@0+ (1,0) [0|0] "" Vector__XXX
 SG_ NM_CS_ZCUD : 11|1@0+ (1,0) [0|0] "" Vector__XXX
 SG_ NM_RMR_ZCUD : 8|1@0+ (1,0) [0|0] "" Vector__XXX
 SG_ NM_NodeID_ZCUD : 7|8@0+ (1,0) [0|0] "" Vector__XXX

 SG_ WakeUpReasonsforZCUDM : 55|16@0+ (1,0) [0|65535] "" Vector__XXX

BO_ 2047 ZcudToAllFuncBodyCanExposedDiagReqFrame : 8 ZCUD

BO_ 1971 ZcudToHcmlBodyCanExposedDiagReqFrame : 8 ZCUD

BO_ 1972 ZcudToHcmrBodyCanExposedDiagReqFrame : 8 ZCUD

BO_ 1970 ZcudToRcmBodyCanExposedDiagReqFrame : 8 ZCUD

CM_ SG_ 802 DwnLoadDynLtgPrmForFrntLeGrp2ContinueTime "Light Show Continue Time Parameter 2";
CM_ SG_ 802 DwnLoadDynLtgPrmForFrntLeGrp2HighBrightness "Light Show Upper Brightness Parameter 2";
CM_ SG_ 802 DwnLoadDynLtgPrmForFrntLeGrp2LowBrightness "Light Show Lower Brightness Parameter 2";
CM_ SG_ 802 DwnLoadDynLtgPrmForFrntLeGrp2Mode1 "Light Show Mode Parameter 2";
CM_ SG_ 802 DwnLoadDynLtgPrmForFrntLeGrp2OffsetTime "Light Show Offset Time Parameter 2";
CM_ SG_ 802 DwnLoadDynLtgPrmForFrntLeGrp2Timestamp "Light Show time stamp 2";
CM_ SG_ 803 DwnLoadDynLtgPrmForFrntLeGrp3ContinueTime "Light Show Continue Time Parameter 2";
CM_ SG_ 803 DwnLoadDynLtgPrmForFrntLeGrp3HighBrightness "Light Show Upper Brightness Parameter 2";
CM_ SG_ 803 DwnLoadDynLtgPrmForFrntLeGrp3LowBrightness "Light Show Lower Brightness Parameter 2";
CM_ SG_ 803 DwnLoadDynLtgPrmForFrntLeGrp3Mode1 "Light Show Mode Parameter 2";
CM_ SG_ 803 DwnLoadDynLtgPrmForFrntLeGrp3OffsetTime "Light Show Offset Time Parameter 2";
CM_ SG_ 803 DwnLoadDynLtgPrmForFrntLeGrp3Timestamp "Light Show time stamp 2";
CM_ SG_ 804 DwnLoadDynLtgPrmForFrntLeGrp4ContinueTime "Light Show Continue Time Parameter 2";
CM_ SG_ 804 DwnLoadDynLtgPrmForFrntLeGrp4HighBrightness "Light Show Upper Brightness Parameter 2";
CM_ SG_ 804 DwnLoadDynLtgPrmForFrntLeGrp4LowBrightness "Light Show Lower Brightness Parameter 2";
CM_ SG_ 804 DwnLoadDynLtgPrmForFrntLeGrp4Mode1 "Light Show Mode Parameter 2";
CM_ SG_ 804 DwnLoadDynLtgPrmForFrntLeGrp4OffsetTime "Light Show Offset Time Parameter 2";
CM_ SG_ 804 DwnLoadDynLtgPrmForFrntLeGrp4Timestamp "Light Show time stamp 2";
CM_ SG_ 805 DwnLoadDynLtgPrmForFrntLeGrp5ContinueTime "Light Show Continue Time Parameter 2";
CM_ SG_ 805 DwnLoadDynLtgPrmForFrntLeGrp5HighBrightness "Light Show Upper Brightness Parameter 2";
CM_ SG_ 805 DwnLoadDynLtgPrmForFrntLeGrp5LowBrightness "Light Show Lower Brightness Parameter 2";
CM_ SG_ 805 DwnLoadDynLtgPrmForFrntLeGrp5Mode1 "Light Show Mode Parameter 2";
CM_ SG_ 805 DwnLoadDynLtgPrmForFrntLeGrp5OffsetTime "Light Show Offset Time Parameter 2";
CM_ SG_ 805 DwnLoadDynLtgPrmForFrntLeGrp5Timestamp "Light Show time stamp 2";
CM_ SG_ 806 DwnLoadDynLtgPrmForFrntLeGrp6ContinueTime "Light Show Continue Time Parameter 2";
CM_ SG_ 806 DwnLoadDynLtgPrmForFrntLeGrp6HighBrightness "Light Show Upper Brightness Parameter 2";
CM_ SG_ 806 DwnLoadDynLtgPrmForFrntLeGrp6LowBrightness "Light Show Lower Brightness Parameter 2";
CM_ SG_ 806 DwnLoadDynLtgPrmForFrntLeGrp6Mode1 "Light Show Mode Parameter 2";
CM_ SG_ 806 DwnLoadDynLtgPrmForFrntLeGrp6OffsetTime "Light Show Offset Time Parameter 2";
CM_ SG_ 806 DwnLoadDynLtgPrmForFrntLeGrp6Timestamp "Light Show time stamp 2";
CM_ SG_ 807 DwnLoadDynLtgPrmForFrntLeGrp7ContinueTime "Light Show Continue Time Parameter 2";
CM_ SG_ 807 DwnLoadDynLtgPrmForFrntLeGrp7HighBrightness "Light Show Upper Brightness Parameter 2";
CM_ SG_ 807 DwnLoadDynLtgPrmForFrntLeGrp7LowBrightness "Light Show Lower Brightness Parameter 2";
CM_ SG_ 807 DwnLoadDynLtgPrmForFrntLeGrp7Mode1 "Light Show Mode Parameter 2";
CM_ SG_ 807 DwnLoadDynLtgPrmForFrntLeGrp7OffsetTime "Light Show Offset Time Parameter 2";
CM_ SG_ 807 DwnLoadDynLtgPrmForFrntLeGrp7Timestamp "Light Show time stamp 2";
CM_ SG_ 808 DwnLoadDynLtgPrmForFrntLeGrp8ContinueTime "Light Show Continue Time Parameter 2";
CM_ SG_ 808 DwnLoadDynLtgPrmForFrntLeGrp8HighBrightness "Light Show Upper Brightness Parameter 2";
CM_ SG_ 808 DwnLoadDynLtgPrmForFrntLeGrp8LowBrightness "Light Show Lower Brightness Parameter 2";
CM_ SG_ 808 DwnLoadDynLtgPrmForFrntLeGrp8Mode1 "Light Show Mode Parameter 2";
CM_ SG_ 808 DwnLoadDynLtgPrmForFrntLeGrp8OffsetTime "Light Show Offset Time Parameter 2";
CM_ SG_ 808 DwnLoadDynLtgPrmForFrntLeGrp8Timestamp "Light Show time stamp 2";
CM_ SG_ 809 DwnLoadDynLtgPrmForFrntLeGrp9ContinueTime "Light Show Continue Time Parameter 2";
CM_ SG_ 809 DwnLoadDynLtgPrmForFrntLeGrp9HighBrightness "Light Show Upper Brightness Parameter 2";
CM_ SG_ 809 DwnLoadDynLtgPrmForFrntLeGrp9LowBrightness "Light Show Lower Brightness Parameter 2";
CM_ SG_ 809 DwnLoadDynLtgPrmForFrntLeGrp9Mode1 "Light Show Mode Parameter 2";
CM_ SG_ 809 DwnLoadDynLtgPrmForFrntLeGrp9OffsetTime "Light Show Offset Time Parameter 2";
CM_ SG_ 809 DwnLoadDynLtgPrmForFrntLeGrp9Timestamp "Light Show time stamp 2";
CM_ SG_ 810 DwnLoadDynLtgPrmForFrntLeGrp10ContinueTime "Light Show Continue Time Parameter 2";
CM_ SG_ 810 DwnLoadDynLtgPrmForFrntLeGrp10HighBrightness "Light Show Upper Brightness Parameter 2";
CM_ SG_ 810 DwnLoadDynLtgPrmForFrntLeGrp10LowBrightness "Light Show Lower Brightness Parameter 2";
CM_ SG_ 810 DwnLoadDynLtgPrmForFrntLeGrp10Mode1 "Light Show Mode Parameter 2";
CM_ SG_ 810 DwnLoadDynLtgPrmForFrntLeGrp10OffsetTime "Light Show Offset Time Parameter 2";
CM_ SG_ 810 DwnLoadDynLtgPrmForFrntLeGrp10Timestamp "Light Show time stamp 2";
CM_ SG_ 811 DwnLoadDynLtgPrmForFrntLeGrp11ContinueTime "Light Show Continue Time Parameter 2";
CM_ SG_ 811 DwnLoadDynLtgPrmForFrntLeGrp11HighBrightness "Light Show Upper Brightness Parameter 2";
CM_ SG_ 811 DwnLoadDynLtgPrmForFrntLeGrp11LowBrightness "Light Show Lower Brightness Parameter 2";
CM_ SG_ 811 DwnLoadDynLtgPrmForFrntLeGrp11Mode1 "Light Show Mode Parameter 2";
CM_ SG_ 811 DwnLoadDynLtgPrmForFrntLeGrp11OffsetTime "Light Show Offset Time Parameter 2";
CM_ SG_ 811 DwnLoadDynLtgPrmForFrntLeGrp11Timestamp "Light Show time stamp 2";
CM_ SG_ 812 DwnLoadDynLtgPrmForFrntLeGrp12ContinueTime "Light Show Continue Time Parameter 2";
CM_ SG_ 812 DwnLoadDynLtgPrmForFrntLeGrp12HighBrightness "Light Show Upper Brightness Parameter 2";
CM_ SG_ 812 DwnLoadDynLtgPrmForFrntLeGrp12LowBrightness "Light Show Lower Brightness Parameter 2";
CM_ SG_ 812 DwnLoadDynLtgPrmForFrntLeGrp12Mode1 "Light Show Mode Parameter 2";
CM_ SG_ 812 DwnLoadDynLtgPrmForFrntLeGrp12OffsetTime "Light Show Offset Time Parameter 2";
CM_ SG_ 812 DwnLoadDynLtgPrmForFrntLeGrp12Timestamp "Light Show time stamp 2";
CM_ SG_ 813 DwnLoadDynLtgPrmForFrntLeGrp13ContinueTime "Light Show Continue Time Parameter 2";
CM_ SG_ 813 DwnLoadDynLtgPrmForFrntLeGrp13HighBrightness "Light Show Upper Brightness Parameter 2";
CM_ SG_ 813 DwnLoadDynLtgPrmForFrntLeGrp13LowBrightness "Light Show Lower Brightness Parameter 2";
CM_ SG_ 813 DwnLoadDynLtgPrmForFrntLeGrp13Mode1 "Light Show Mode Parameter 2";
CM_ SG_ 813 DwnLoadDynLtgPrmForFrntLeGrp13OffsetTime "Light Show Offset Time Parameter 2";
CM_ SG_ 813 DwnLoadDynLtgPrmForFrntLeGrp13Timestamp "Light Show time stamp 2";
CM_ SG_ 814 DwnLoadDynLtgPrmForFrntLeGrp14ContinueTime "Light Show Continue Time Parameter 2";
CM_ SG_ 814 DwnLoadDynLtgPrmForFrntLeGrp14HighBrightness "Light Show Upper Brightness Parameter 2";
CM_ SG_ 814 DwnLoadDynLtgPrmForFrntLeGrp14LowBrightness "Light Show Lower Brightness Parameter 2";
CM_ SG_ 814 DwnLoadDynLtgPrmForFrntLeGrp14Mode1 "Light Show Mode Parameter 2";
CM_ SG_ 814 DwnLoadDynLtgPrmForFrntLeGrp14OffsetTime "Light Show Offset Time Parameter 2";
CM_ SG_ 814 DwnLoadDynLtgPrmForFrntLeGrp14Timestamp "Light Show time stamp 2";
CM_ SG_ 815 DwnLoadDynLtgPrmForFrntLeGrp15ContinueTime "Light Show Continue Time Parameter 2";
CM_ SG_ 815 DwnLoadDynLtgPrmForFrntLeGrp15HighBrightness "Light Show Upper Brightness Parameter 2";
CM_ SG_ 815 DwnLoadDynLtgPrmForFrntLeGrp15LowBrightness "Light Show Lower Brightness Parameter 2";
CM_ SG_ 815 DwnLoadDynLtgPrmForFrntLeGrp15Mode1 "Light Show Mode Parameter 2";
CM_ SG_ 815 DwnLoadDynLtgPrmForFrntLeGrp15OffsetTime "Light Show Offset Time Parameter 2";
CM_ SG_ 815 DwnLoadDynLtgPrmForFrntLeGrp15Timestamp "Light Show time stamp 2";
CM_ SG_ 816 DwnLoadDynLtgPrmForFrntLeGrp16ContinueTime "Light Show Continue Time Parameter 2";
CM_ SG_ 816 DwnLoadDynLtgPrmForFrntLeGrp16HighBrightness "Light Show Upper Brightness Parameter 2";
CM_ SG_ 816 DwnLoadDynLtgPrmForFrntLeGrp16LowBrightness "Light Show Lower Brightness Parameter 2";
CM_ SG_ 816 DwnLoadDynLtgPrmForFrntLeGrp16Mode1 "Light Show Mode Parameter 2";
CM_ SG_ 816 DwnLoadDynLtgPrmForFrntLeGrp16OffsetTime "Light Show Offset Time Parameter 2";
CM_ SG_ 816 DwnLoadDynLtgPrmForFrntLeGrp16Timestamp "Light Show time stamp 2";
CM_ SG_ 817 DwnLoadDynLtgPrmForFrntLeGrp17ContinueTime "Light Show Continue Time Parameter 2";
CM_ SG_ 817 DwnLoadDynLtgPrmForFrntLeGrp17HighBrightness "Light Show Upper Brightness Parameter 2";
CM_ SG_ 817 DwnLoadDynLtgPrmForFrntLeGrp17LowBrightness "Light Show Lower Brightness Parameter 2";
CM_ SG_ 817 DwnLoadDynLtgPrmForFrntLeGrp17Mode1 "Light Show Mode Parameter 2";
CM_ SG_ 817 DwnLoadDynLtgPrmForFrntLeGrp17OffsetTime "Light Show Offset Time Parameter 2";
CM_ SG_ 817 DwnLoadDynLtgPrmForFrntLeGrp17Timestamp "Light Show time stamp 2";
CM_ SG_ 818 DwnLoadDynLtgPrmForFrntLeGrp18ContinueTime "Light Show Continue Time Parameter 2";
CM_ SG_ 818 DwnLoadDynLtgPrmForFrntLeGrp18HighBrightness "Light Show Upper Brightness Parameter 2";
CM_ SG_ 818 DwnLoadDynLtgPrmForFrntLeGrp18LowBrightness "Light Show Lower Brightness Parameter 2";
CM_ SG_ 818 DwnLoadDynLtgPrmForFrntLeGrp18Mode1 "Light Show Mode Parameter 2";
CM_ SG_ 818 DwnLoadDynLtgPrmForFrntLeGrp18OffsetTime "Light Show Offset Time Parameter 2";
CM_ SG_ 818 DwnLoadDynLtgPrmForFrntLeGrp18Timestamp "Light Show time stamp 2";
CM_ SG_ 819 DwnLoadDynLtgPrmForFrntLeGrp19ContinueTime "Light Show Continue Time Parameter 2";
CM_ SG_ 819 DwnLoadDynLtgPrmForFrntLeGrp19HighBrightness "Light Show Upper Brightness Parameter 2";
CM_ SG_ 819 DwnLoadDynLtgPrmForFrntLeGrp19LowBrightness "Light Show Lower Brightness Parameter 2";
CM_ SG_ 819 DwnLoadDynLtgPrmForFrntLeGrp19Mode1 "Light Show Mode Parameter 2";
CM_ SG_ 819 DwnLoadDynLtgPrmForFrntLeGrp19OffsetTime "Light Show Offset Time Parameter 2";
CM_ SG_ 819 DwnLoadDynLtgPrmForFrntLeGrp19Timestamp "Light Show time stamp 2";
CM_ SG_ 820 DwnLoadDynLtgPrmForFrntLeGrp20ContinueTime "Light Show Continue Time Parameter 2";
CM_ SG_ 820 DwnLoadDynLtgPrmForFrntLeGrp20HighBrightness "Light Show Upper Brightness Parameter 2";
CM_ SG_ 820 DwnLoadDynLtgPrmForFrntLeGrp20LowBrightness "Light Show Lower Brightness Parameter 2";
CM_ SG_ 820 DwnLoadDynLtgPrmForFrntLeGrp20Mode1 "Light Show Mode Parameter 2";
CM_ SG_ 820 DwnLoadDynLtgPrmForFrntLeGrp20OffsetTime "Light Show Offset Time Parameter 2";
CM_ SG_ 820 DwnLoadDynLtgPrmForFrntLeGrp20Timestamp "Light Show time stamp 2";
CM_ SG_ 821 DwnLoadDynLtgPrmForFrntLeGrp21ContinueTime "Light Show Continue Time Parameter 2";
CM_ SG_ 821 DwnLoadDynLtgPrmForFrntLeGrp21HighBrightness "Light Show Upper Brightness Parameter 2";
CM_ SG_ 821 DwnLoadDynLtgPrmForFrntLeGrp21LowBrightness "Light Show Lower Brightness Parameter 2";
CM_ SG_ 821 DwnLoadDynLtgPrmForFrntLeGrp21Mode1 "Light Show Mode Parameter 2";
CM_ SG_ 821 DwnLoadDynLtgPrmForFrntLeGrp21OffsetTime "Light Show Offset Time Parameter 2";
CM_ SG_ 821 DwnLoadDynLtgPrmForFrntLeGrp21Timestamp "Light Show time stamp 2";
CM_ SG_ 822 DwnLoadDynLtgPrmForFrntLeGrp22ContinueTime "Light Show Continue Time Parameter 2";
CM_ SG_ 822 DwnLoadDynLtgPrmForFrntLeGrp22HighBrightness "Light Show Upper Brightness Parameter 2";
CM_ SG_ 822 DwnLoadDynLtgPrmForFrntLeGrp22LowBrightness "Light Show Lower Brightness Parameter 2";
CM_ SG_ 822 DwnLoadDynLtgPrmForFrntLeGrp22Mode1 "Light Show Mode Parameter 2";
CM_ SG_ 822 DwnLoadDynLtgPrmForFrntLeGrp22OffsetTime "Light Show Offset Time Parameter 2";
CM_ SG_ 822 DwnLoadDynLtgPrmForFrntLeGrp22Timestamp "Light Show time stamp 2";
CM_ SG_ 823 DwnLoadDynLtgPrmForFrntLeGrp23ContinueTime "Light Show Continue Time Parameter 2";
CM_ SG_ 823 DwnLoadDynLtgPrmForFrntLeGrp23HighBrightness "Light Show Upper Brightness Parameter 2";
CM_ SG_ 823 DwnLoadDynLtgPrmForFrntLeGrp23LowBrightness "Light Show Lower Brightness Parameter 2";
CM_ SG_ 823 DwnLoadDynLtgPrmForFrntLeGrp23Mode1 "Light Show Mode Parameter 2";
CM_ SG_ 823 DwnLoadDynLtgPrmForFrntLeGrp23OffsetTime "Light Show Offset Time Parameter 2";
CM_ SG_ 823 DwnLoadDynLtgPrmForFrntLeGrp23Timestamp "Light Show time stamp 2";
CM_ SG_ 824 DwnLoadDynLtgPrmForFrntLeGrp24ContinueTime "Light Show Continue Time Parameter 2";
CM_ SG_ 824 DwnLoadDynLtgPrmForFrntLeGrp24HighBrightness "Light Show Upper Brightness Parameter 2";
CM_ SG_ 824 DwnLoadDynLtgPrmForFrntLeGrp24LowBrightness "Light Show Lower Brightness Parameter 2";
CM_ SG_ 824 DwnLoadDynLtgPrmForFrntLeGrp24Mode1 "Light Show Mode Parameter 2";
CM_ SG_ 824 DwnLoadDynLtgPrmForFrntLeGrp24OffsetTime "Light Show Offset Time Parameter 2";
CM_ SG_ 824 DwnLoadDynLtgPrmForFrntLeGrp24Timestamp "Light Show time stamp 2";
CM_ SG_ 825 DwnLoadDynLtgPrmForFrntRIGrp1ContinueTime "Light Show Continue Time Parameter 2";
CM_ SG_ 825 DwnLoadDynLtgPrmForFrntRIGrp1HighBrightness "Light Show Upper Brightness Parameter 2";
CM_ SG_ 825 DwnLoadDynLtgPrmForFrntRIGrp1LowBrightness "Light Show Lower Brightness Parameter 2";
CM_ SG_ 825 DwnLoadDynLtgPrmForFrntRIGrp1Mode1 "Light Show Mode Parameter 2";
CM_ SG_ 825 DwnLoadDynLtgPrmForFrntRIGrp1OffsetTime "Light Show Offset Time Parameter 2";
CM_ SG_ 825 DwnLoadDynLtgPrmForFrntRIGrp1Timestamp "Light Show time stamp 2";
CM_ SG_ 826 DwnLoadDynLtgPrmForFrntRIGrp2ContinueTime "Light Show Continue Time Parameter 2";
CM_ SG_ 826 DwnLoadDynLtgPrmForFrntRIGrp2HighBrightness "Light Show Upper Brightness Parameter 2";
CM_ SG_ 826 DwnLoadDynLtgPrmForFrntRIGrp2LowBrightness "Light Show Lower Brightness Parameter 2";
CM_ SG_ 826 DwnLoadDynLtgPrmForFrntRIGrp2Mode1 "Light Show Mode Parameter 2";
CM_ SG_ 826 DwnLoadDynLtgPrmForFrntRIGrp2OffsetTime "Light Show Offset Time Parameter 2";
CM_ SG_ 826 DwnLoadDynLtgPrmForFrntRIGrp2Timestamp "Light Show time stamp 2";
CM_ SG_ 827 DwnLoadDynLtgPrmForFrntRIGrp3ContinueTime "Light Show Continue Time Parameter 2";
CM_ SG_ 827 DwnLoadDynLtgPrmForFrntRIGrp3HighBrightness "Light Show Upper Brightness Parameter 2";
CM_ SG_ 827 DwnLoadDynLtgPrmForFrntRIGrp3LowBrightness "Light Show Lower Brightness Parameter 2";
CM_ SG_ 827 DwnLoadDynLtgPrmForFrntRIGrp3Mode1 "Light Show Mode Parameter 2";
CM_ SG_ 827 DwnLoadDynLtgPrmForFrntRIGrp3OffsetTime "Light Show Offset Time Parameter 2";
CM_ SG_ 827 DwnLoadDynLtgPrmForFrntRIGrp3Timestamp "Light Show time stamp 2";
CM_ SG_ 828 DwnLoadDynLtgPrmForFrntRIGrp4ContinueTime "Light Show Continue Time Parameter 2";
CM_ SG_ 828 DwnLoadDynLtgPrmForFrntRIGrp4HighBrightness "Light Show Upper Brightness Parameter 2";
CM_ SG_ 828 DwnLoadDynLtgPrmForFrntRIGrp4LowBrightness "Light Show Lower Brightness Parameter 2";
CM_ SG_ 828 DwnLoadDynLtgPrmForFrntRIGrp4Mode1 "Light Show Mode Parameter 2";
CM_ SG_ 828 DwnLoadDynLtgPrmForFrntRIGrp4OffsetTime "Light Show Offset Time Parameter 2";
CM_ SG_ 828 DwnLoadDynLtgPrmForFrntRIGrp4Timestamp "Light Show time stamp 2";
CM_ SG_ 829 DwnLoadDynLtgPrmForFrntRIGrp5ContinueTime "Light Show Continue Time Parameter 2";
CM_ SG_ 829 DwnLoadDynLtgPrmForFrntRIGrp5HighBrightness "Light Show Upper Brightness Parameter 2";
CM_ SG_ 829 DwnLoadDynLtgPrmForFrntRIGrp5LowBrightness "Light Show Lower Brightness Parameter 2";
CM_ SG_ 829 DwnLoadDynLtgPrmForFrntRIGrp5Mode1 "Light Show Mode Parameter 2";
CM_ SG_ 829 DwnLoadDynLtgPrmForFrntRIGrp5OffsetTime "Light Show Offset Time Parameter 2";
CM_ SG_ 829 DwnLoadDynLtgPrmForFrntRIGrp5Timestamp "Light Show time stamp 2";
CM_ SG_ 830 DwnLoadDynLtgPrmForFrntRIGrp6ContinueTime "Light Show Continue Time Parameter 2";
CM_ SG_ 830 DwnLoadDynLtgPrmForFrntRIGrp6HighBrightness "Light Show Upper Brightness Parameter 2";
CM_ SG_ 830 DwnLoadDynLtgPrmForFrntRIGrp6LowBrightness "Light Show Lower Brightness Parameter 2";
CM_ SG_ 830 DwnLoadDynLtgPrmForFrntRIGrp6Mode1 "Light Show Mode Parameter 2";
CM_ SG_ 830 DwnLoadDynLtgPrmForFrntRIGrp6OffsetTime "Light Show Offset Time Parameter 2";
CM_ SG_ 830 DwnLoadDynLtgPrmForFrntRIGrp6Timestamp "Light Show time stamp 2";
CM_ SG_ 831 DwnLoadDynLtgPrmForFrntRIGrp7ContinueTime "Light Show Continue Time Parameter 2";
CM_ SG_ 831 DwnLoadDynLtgPrmForFrntRIGrp7HighBrightness "Light Show Upper Brightness Parameter 2";
CM_ SG_ 831 DwnLoadDynLtgPrmForFrntRIGrp7LowBrightness "Light Show Lower Brightness Parameter 2";
CM_ SG_ 831 DwnLoadDynLtgPrmForFrntRIGrp7Mode1 "Light Show Mode Parameter 2";
CM_ SG_ 831 DwnLoadDynLtgPrmForFrntRIGrp7OffsetTime "Light Show Offset Time Parameter 2";
CM_ SG_ 831 DwnLoadDynLtgPrmForFrntRIGrp7Timestamp "Light Show time stamp 2";
CM_ SG_ 832 DwnLoadDynLtgPrmForFrntRIGrp8ContinueTime "Light Show Continue Time Parameter 2";
CM_ SG_ 832 DwnLoadDynLtgPrmForFrntRIGrp8HighBrightness "Light Show Upper Brightness Parameter 2";
CM_ SG_ 832 DwnLoadDynLtgPrmForFrntRIGrp8LowBrightness "Light Show Lower Brightness Parameter 2";
CM_ SG_ 832 DwnLoadDynLtgPrmForFrntRIGrp8Mode1 "Light Show Mode Parameter 2";
CM_ SG_ 832 DwnLoadDynLtgPrmForFrntRIGrp8OffsetTime "Light Show Offset Time Parameter 2";
CM_ SG_ 832 DwnLoadDynLtgPrmForFrntRIGrp8Timestamp "Light Show time stamp 2";
CM_ SG_ 833 DwnLoadDynLtgPrmForFrntRIGrp9ContinueTime "Light Show Continue Time Parameter 2";
CM_ SG_ 833 DwnLoadDynLtgPrmForFrntRIGrp9HighBrightness "Light Show Upper Brightness Parameter 2";
CM_ SG_ 833 DwnLoadDynLtgPrmForFrntRIGrp9LowBrightness "Light Show Lower Brightness Parameter 2";
CM_ SG_ 833 DwnLoadDynLtgPrmForFrntRIGrp9Mode1 "Light Show Mode Parameter 2";
CM_ SG_ 833 DwnLoadDynLtgPrmForFrntRIGrp9OffsetTime "Light Show Offset Time Parameter 2";
CM_ SG_ 833 DwnLoadDynLtgPrmForFrntRIGrp9Timestamp "Light Show time stamp 2";
CM_ SG_ 272 SphDvExtnLg "Voice status linked to exterior lights";
CM_ SG_ 790 VehCfgPrmExt2BlkIDBytePosn1 "CarConfigExtended2 BlockID";
CM_ SG_ 790 VehCfgPrmExt2CCPBytePosn2 "CarConfigExtended2 BytePos2";
CM_ SG_ 790 VehCfgPrmExt2CCPBytePosn3 "CarConfigExtended2 BytePos3";
CM_ SG_ 790 VehCfgPrmExt2CCPBytePosn4 "CarConfigExtended2 BytePos4";
CM_ SG_ 790 VehCfgPrmExt2CCPBytePosn5 "CarConfigExtended2 BytePos5";
CM_ SG_ 790 VehCfgPrmExt2CCPBytePosn6 "CarConfigExtended2 BytePos6";
CM_ SG_ 790 VehCfgPrmExt2CCPBytePosn7 "CarConfigExtended2 BytePos7";
CM_ SG_ 790 VehCfgPrmExt2CCPBytePosn8 "CarConfigExtended2 BytePos8";
CM_ SG_ 1282 WakeUpReasonsforZCUDM "WakeUpReasons";
BA_DEF_ BO_ "GenMsgCycleTime" INT 0 65536; // [ms]
BA_DEF_ BO_ "GenMsgDelayTime" INT 0 65536; // [ms]
BA_DEF_ BO_ "GenMsgSendType" ENUM "cyclic", "spontaneous", "not-used", "not-used", "not-used", "cyclicAndSpontaneous", "not-used", "cyclicIfActive", "NoMsgSendType"; // [us]
BA_DEF_ BO_ "GenMsgStartDelayTime" INT 0 65536; // [ms]
BA_DEF_ SG_ "GenSigSendType" ENUM "Cyclic","OnWrite","OnWriteWithRepetition","OnChange","OnChangeWithRepetition","IfActive","IfActiveWithRepetition","NoSigSendType";
BA_DEF_ SG_ "GenSigStartValue" HEX 0 80000000;
BA_DEF_ BO_ "GenMsgILSupport" ENUM "No","Yes";
BA_DEF_ BO_ "NmAsrMessage" ENUM "No","Yes";
BA_DEF_ SG_ "GenSigFuncType" ENUM "NoFunction","n/a","n/a","n/a","n/a","n/a","n/a","n/a","n/a","n/a","n/a","n/a","n/a","n/a","n/a","CHK","CNTR","n/a","n/a","n/a","CNTR_AR_01","CRC_AR_01_BOTH","CRC_AR_01_ALT","CRC_AR_01_LOW","CRC_AR_01_NIBBLE","CNTR_AR_04","CRC_AR_04A","CNTR_AR_05","CRC_AR_05";
BA_DEF_ SG_ "GenSigDataID" STRING;
BA_DEF_DEF_ "GenSigStartValue" 0;
BA_DEF_DEF_ "GenSigSendType" "NoSigSendType";
BA_DEF_DEF_ "GenMsgCycleTime" 0;
BA_DEF_DEF_ "GenMsgDelayTime" 0;
BA_DEF_DEF_ "GenMsgStartDelayTime" 0;
BA_DEF_DEF_ "GenMsgSendType" "NoMsgSendType";
BA_DEF_DEF_ "GenMsgILSupport" "Yes";
BA_DEF_DEF_ "NmAsrMessage" "No";
BA_DEF_DEF_ "GenSigFuncType" "NoFunction";
BA_DEF_DEF_ "GenSigDataID" "";
// Frame: ZCUDBodyExpoFr47
BA_ "GenMsgDelayTime" BO_ 802 35.000;
BA_ "GenMsgSendType" BO_ 802 1;
// Frame: ZCUDBodyExpoFr48
BA_ "GenMsgDelayTime" BO_ 803 35.000;
BA_ "GenMsgSendType" BO_ 803 1;
// Frame: ZCUDBodyExpoFr49
BA_ "GenMsgDelayTime" BO_ 804 35.000;
BA_ "GenMsgSendType" BO_ 804 1;
// Frame: ZCUDBodyExpoFr50
BA_ "GenMsgDelayTime" BO_ 805 35.000;
BA_ "GenMsgSendType" BO_ 805 1;
// Frame: ZCUDBodyExpoFr51
BA_ "GenMsgDelayTime" BO_ 806 35.000;
BA_ "GenMsgSendType" BO_ 806 1;
// Frame: ZCUDBodyExpoFr52
BA_ "GenMsgDelayTime" BO_ 807 35.000;
BA_ "GenMsgSendType" BO_ 807 1;
// Frame: ZCUDBodyExpoFr53
BA_ "GenMsgDelayTime" BO_ 808 35.000;
BA_ "GenMsgSendType" BO_ 808 1;
// Frame: ZCUDBodyExpoFr54
BA_ "GenMsgDelayTime" BO_ 809 35.000;
BA_ "GenMsgSendType" BO_ 809 1;
// Frame: ZCUDBodyExpoFr55
BA_ "GenMsgDelayTime" BO_ 810 35.000;
BA_ "GenMsgSendType" BO_ 810 1;
// Frame: ZCUDBodyExpoFr56
BA_ "GenMsgDelayTime" BO_ 811 35.000;
BA_ "GenMsgSendType" BO_ 811 1;
// Frame: ZCUDBodyExpoFr57
BA_ "GenMsgDelayTime" BO_ 812 35.000;
BA_ "GenMsgSendType" BO_ 812 1;
// Frame: ZCUDBodyExpoFr58
BA_ "GenMsgDelayTime" BO_ 813 35.000;
BA_ "GenMsgSendType" BO_ 813 1;
// Frame: ZCUDBodyExpoFr59
BA_ "GenMsgDelayTime" BO_ 814 35.000;
BA_ "GenMsgSendType" BO_ 814 1;
// Frame: ZCUDBodyExpoFr60
BA_ "GenMsgDelayTime" BO_ 815 35.000;
BA_ "GenMsgSendType" BO_ 815 1;
// Frame: ZCUDBodyExpoFr61
BA_ "GenMsgDelayTime" BO_ 816 35.000;
BA_ "GenMsgSendType" BO_ 816 1;
// Frame: ZCUDBodyExpoFr62
BA_ "GenMsgDelayTime" BO_ 817 35.000;
BA_ "GenMsgSendType" BO_ 817 1;
// Frame: ZCUDBodyExpoFr63
BA_ "GenMsgDelayTime" BO_ 818 35.000;
BA_ "GenMsgSendType" BO_ 818 1;
// Frame: ZCUDBodyExpoFr64
BA_ "GenMsgDelayTime" BO_ 819 35.000;
BA_ "GenMsgSendType" BO_ 819 1;
// Frame: ZCUDBodyExpoFr65
BA_ "GenMsgDelayTime" BO_ 820 35.000;
BA_ "GenMsgSendType" BO_ 820 1;
// Frame: ZCUDBodyExpoFr66
BA_ "GenMsgDelayTime" BO_ 821 35.000;
BA_ "GenMsgSendType" BO_ 821 1;
// Frame: ZCUDBodyExpoFr67
BA_ "GenMsgDelayTime" BO_ 822 35.000;
BA_ "GenMsgSendType" BO_ 822 1;
// Frame: ZCUDBodyExpoFr68
BA_ "GenMsgDelayTime" BO_ 823 35.000;
BA_ "GenMsgSendType" BO_ 823 1;
// Frame: ZCUDBodyExpoFr69
BA_ "GenMsgDelayTime" BO_ 824 35.000;
BA_ "GenMsgSendType" BO_ 824 1;
// Frame: ZCUDBodyExpoFr70
BA_ "GenMsgDelayTime" BO_ 825 35.000;
BA_ "GenMsgSendType" BO_ 825 1;
// Frame: ZCUDBodyExpoFr71
BA_ "GenMsgDelayTime" BO_ 826 35.000;
BA_ "GenMsgSendType" BO_ 826 1;
// Frame: ZCUDBodyExpoFr72
BA_ "GenMsgDelayTime" BO_ 827 35.000;
BA_ "GenMsgSendType" BO_ 827 1;
// Frame: ZCUDBodyExpoFr73
BA_ "GenMsgDelayTime" BO_ 828 35.000;
BA_ "GenMsgSendType" BO_ 828 1;
// Frame: ZCUDBodyExpoFr74
BA_ "GenMsgDelayTime" BO_ 829 35.000;
BA_ "GenMsgSendType" BO_ 829 1;
// Frame: ZCUDBodyExpoFr75
BA_ "GenMsgDelayTime" BO_ 830 35.000;
BA_ "GenMsgSendType" BO_ 830 1;
// Frame: ZCUDBodyExpoFr76
BA_ "GenMsgDelayTime" BO_ 831 35.000;
BA_ "GenMsgSendType" BO_ 831 1;
// Frame: ZCUDBodyExpoFr77
BA_ "GenMsgDelayTime" BO_ 832 35.000;
BA_ "GenMsgSendType" BO_ 832 1;
// Frame: ZCUDBodyExpoFr78
BA_ "GenMsgDelayTime" BO_ 833 35.000;
BA_ "GenMsgSendType" BO_ 833 1;
// Frame: ZCUDBodyExpoFr79
BA_ "GenMsgCycleTime" BO_ 272 20.000;
BA_ "GenMsgSendType" BO_ 272 0;
// Frame: ZCUDBodyExpoFr80
BA_ "GenMsgDelayTime" BO_ 790 200.000;
BA_ "GenMsgSendType" BO_ 790 1;
// Frame: ZcudBodyExposedNMFr
BA_ "GenMsgDelayTime" BO_ 1282 20.000;
BA_ "GenMsgSendType" BO_ 1282 1;
// Frame: ZcudToAllFuncBodyCanExposedDiagReqFrame
BA_ "GenMsgDelayTime" BO_ 2047 5.000;
BA_ "GenMsgSendType" BO_ 2047 1;
// Frame: ZcudToHcmlBodyCanExposedDiagReqFrame
BA_ "GenMsgDelayTime" BO_ 1971 5.000;
BA_ "GenMsgSendType" BO_ 1971 1;
// Frame: ZcudToHcmrBodyCanExposedDiagReqFrame
BA_ "GenMsgDelayTime" BO_ 1972 5.000;
BA_ "GenMsgSendType" BO_ 1972 1;
// Frame: ZcudToRcmBodyCanExposedDiagReqFrame
BA_ "GenMsgDelayTime" BO_ 1970 5.000;
BA_ "GenMsgSendType" BO_ 1970 1;
BA_ "GenMsgILSupport" BO_ 1282 0;
BA_ "NmAsrMessage" BO_ 1282 1;
BA_ "GenSigSendType" SG_ 810 DwnLoadDynLtgPrmForFrntLeGrp10ContinueTime 1;
BA_ "GenSigSendType" SG_ 810 DwnLoadDynLtgPrmForFrntLeGrp10HighBrightness 1;
BA_ "GenSigSendType" SG_ 810 DwnLoadDynLtgPrmForFrntLeGrp10LowBrightness 1;
BA_ "GenSigSendType" SG_ 810 DwnLoadDynLtgPrmForFrntLeGrp10Mode1 1;
BA_ "GenSigSendType" SG_ 810 DwnLoadDynLtgPrmForFrntLeGrp10OffsetTime 1;
BA_ "GenSigSendType" SG_ 810 DwnLoadDynLtgPrmForFrntLeGrp10Timestamp 1;
BA_ "GenSigSendType" SG_ 811 DwnLoadDynLtgPrmForFrntLeGrp11ContinueTime 1;
BA_ "GenSigSendType" SG_ 811 DwnLoadDynLtgPrmForFrntLeGrp11HighBrightness 1;
BA_ "GenSigSendType" SG_ 811 DwnLoadDynLtgPrmForFrntLeGrp11LowBrightness 1;
BA_ "GenSigSendType" SG_ 811 DwnLoadDynLtgPrmForFrntLeGrp11Mode1 1;
BA_ "GenSigSendType" SG_ 811 DwnLoadDynLtgPrmForFrntLeGrp11OffsetTime 1;
BA_ "GenSigSendType" SG_ 811 DwnLoadDynLtgPrmForFrntLeGrp11Timestamp 1;
BA_ "GenSigSendType" SG_ 812 DwnLoadDynLtgPrmForFrntLeGrp12ContinueTime 1;
BA_ "GenSigSendType" SG_ 812 DwnLoadDynLtgPrmForFrntLeGrp12HighBrightness 1;
BA_ "GenSigSendType" SG_ 812 DwnLoadDynLtgPrmForFrntLeGrp12LowBrightness 1;
BA_ "GenSigSendType" SG_ 812 DwnLoadDynLtgPrmForFrntLeGrp12Mode1 1;
BA_ "GenSigSendType" SG_ 812 DwnLoadDynLtgPrmForFrntLeGrp12OffsetTime 1;
BA_ "GenSigSendType" SG_ 812 DwnLoadDynLtgPrmForFrntLeGrp12Timestamp 1;
BA_ "GenSigSendType" SG_ 813 DwnLoadDynLtgPrmForFrntLeGrp13ContinueTime 1;
BA_ "GenSigSendType" SG_ 813 DwnLoadDynLtgPrmForFrntLeGrp13HighBrightness 1;
BA_ "GenSigSendType" SG_ 813 DwnLoadDynLtgPrmForFrntLeGrp13LowBrightness 1;
BA_ "GenSigSendType" SG_ 813 DwnLoadDynLtgPrmForFrntLeGrp13Mode1 1;
BA_ "GenSigSendType" SG_ 813 DwnLoadDynLtgPrmForFrntLeGrp13OffsetTime 1;
BA_ "GenSigSendType" SG_ 813 DwnLoadDynLtgPrmForFrntLeGrp13Timestamp 1;
BA_ "GenSigSendType" SG_ 814 DwnLoadDynLtgPrmForFrntLeGrp14ContinueTime 1;
BA_ "GenSigSendType" SG_ 814 DwnLoadDynLtgPrmForFrntLeGrp14HighBrightness 1;
BA_ "GenSigSendType" SG_ 814 DwnLoadDynLtgPrmForFrntLeGrp14LowBrightness 1;
BA_ "GenSigSendType" SG_ 814 DwnLoadDynLtgPrmForFrntLeGrp14Mode1 1;
BA_ "GenSigSendType" SG_ 814 DwnLoadDynLtgPrmForFrntLeGrp14OffsetTime 1;
BA_ "GenSigSendType" SG_ 814 DwnLoadDynLtgPrmForFrntLeGrp14Timestamp 1;
BA_ "GenSigSendType" SG_ 815 DwnLoadDynLtgPrmForFrntLeGrp15ContinueTime 1;
BA_ "GenSigSendType" SG_ 815 DwnLoadDynLtgPrmForFrntLeGrp15HighBrightness 1;
BA_ "GenSigSendType" SG_ 815 DwnLoadDynLtgPrmForFrntLeGrp15LowBrightness 1;
BA_ "GenSigSendType" SG_ 815 DwnLoadDynLtgPrmForFrntLeGrp15Mode1 1;
BA_ "GenSigSendType" SG_ 815 DwnLoadDynLtgPrmForFrntLeGrp15OffsetTime 1;
BA_ "GenSigSendType" SG_ 815 DwnLoadDynLtgPrmForFrntLeGrp15Timestamp 1;
BA_ "GenSigSendType" SG_ 816 DwnLoadDynLtgPrmForFrntLeGrp16ContinueTime 1;
BA_ "GenSigSendType" SG_ 816 DwnLoadDynLtgPrmForFrntLeGrp16HighBrightness 1;
BA_ "GenSigSendType" SG_ 816 DwnLoadDynLtgPrmForFrntLeGrp16LowBrightness 1;
BA_ "GenSigSendType" SG_ 816 DwnLoadDynLtgPrmForFrntLeGrp16Mode1 1;
BA_ "GenSigSendType" SG_ 816 DwnLoadDynLtgPrmForFrntLeGrp16OffsetTime 1;
BA_ "GenSigSendType" SG_ 816 DwnLoadDynLtgPrmForFrntLeGrp16Timestamp 1;
BA_ "GenSigSendType" SG_ 817 DwnLoadDynLtgPrmForFrntLeGrp17ContinueTime 1;
BA_ "GenSigSendType" SG_ 817 DwnLoadDynLtgPrmForFrntLeGrp17HighBrightness 1;
BA_ "GenSigSendType" SG_ 817 DwnLoadDynLtgPrmForFrntLeGrp17LowBrightness 1;
BA_ "GenSigSendType" SG_ 817 DwnLoadDynLtgPrmForFrntLeGrp17Mode1 1;
BA_ "GenSigSendType" SG_ 817 DwnLoadDynLtgPrmForFrntLeGrp17OffsetTime 1;
BA_ "GenSigSendType" SG_ 817 DwnLoadDynLtgPrmForFrntLeGrp17Timestamp 1;
BA_ "GenSigSendType" SG_ 818 DwnLoadDynLtgPrmForFrntLeGrp18ContinueTime 1;
BA_ "GenSigSendType" SG_ 818 DwnLoadDynLtgPrmForFrntLeGrp18HighBrightness 1;
BA_ "GenSigSendType" SG_ 818 DwnLoadDynLtgPrmForFrntLeGrp18LowBrightness 1;
BA_ "GenSigSendType" SG_ 818 DwnLoadDynLtgPrmForFrntLeGrp18Mode1 1;
BA_ "GenSigSendType" SG_ 818 DwnLoadDynLtgPrmForFrntLeGrp18OffsetTime 1;
BA_ "GenSigSendType" SG_ 818 DwnLoadDynLtgPrmForFrntLeGrp18Timestamp 1;
BA_ "GenSigSendType" SG_ 819 DwnLoadDynLtgPrmForFrntLeGrp19ContinueTime 1;
BA_ "GenSigSendType" SG_ 819 DwnLoadDynLtgPrmForFrntLeGrp19HighBrightness 1;
BA_ "GenSigSendType" SG_ 819 DwnLoadDynLtgPrmForFrntLeGrp19LowBrightness 1;
BA_ "GenSigSendType" SG_ 819 DwnLoadDynLtgPrmForFrntLeGrp19Mode1 1;
BA_ "GenSigSendType" SG_ 819 DwnLoadDynLtgPrmForFrntLeGrp19OffsetTime 1;
BA_ "GenSigSendType" SG_ 819 DwnLoadDynLtgPrmForFrntLeGrp19Timestamp 1;
BA_ "GenSigSendType" SG_ 820 DwnLoadDynLtgPrmForFrntLeGrp20ContinueTime 1;
BA_ "GenSigSendType" SG_ 820 DwnLoadDynLtgPrmForFrntLeGrp20HighBrightness 1;
BA_ "GenSigSendType" SG_ 820 DwnLoadDynLtgPrmForFrntLeGrp20LowBrightness 1;
BA_ "GenSigSendType" SG_ 820 DwnLoadDynLtgPrmForFrntLeGrp20Mode1 1;
BA_ "GenSigSendType" SG_ 820 DwnLoadDynLtgPrmForFrntLeGrp20OffsetTime 1;
BA_ "GenSigSendType" SG_ 820 DwnLoadDynLtgPrmForFrntLeGrp20Timestamp 1;
BA_ "GenSigSendType" SG_ 821 DwnLoadDynLtgPrmForFrntLeGrp21ContinueTime 1;
BA_ "GenSigSendType" SG_ 821 DwnLoadDynLtgPrmForFrntLeGrp21HighBrightness 1;
BA_ "GenSigSendType" SG_ 821 DwnLoadDynLtgPrmForFrntLeGrp21LowBrightness 1;
BA_ "GenSigSendType" SG_ 821 DwnLoadDynLtgPrmForFrntLeGrp21Mode1 1;
BA_ "GenSigSendType" SG_ 821 DwnLoadDynLtgPrmForFrntLeGrp21OffsetTime 1;
BA_ "GenSigSendType" SG_ 821 DwnLoadDynLtgPrmForFrntLeGrp21Timestamp 1;
BA_ "GenSigSendType" SG_ 822 DwnLoadDynLtgPrmForFrntLeGrp22ContinueTime 1;
BA_ "GenSigSendType" SG_ 822 DwnLoadDynLtgPrmForFrntLeGrp22HighBrightness 1;
BA_ "GenSigSendType" SG_ 822 DwnLoadDynLtgPrmForFrntLeGrp22LowBrightness 1;
BA_ "GenSigSendType" SG_ 822 DwnLoadDynLtgPrmForFrntLeGrp22Mode1 1;
BA_ "GenSigSendType" SG_ 822 DwnLoadDynLtgPrmForFrntLeGrp22OffsetTime 1;
BA_ "GenSigSendType" SG_ 822 DwnLoadDynLtgPrmForFrntLeGrp22Timestamp 1;
BA_ "GenSigSendType" SG_ 823 DwnLoadDynLtgPrmForFrntLeGrp23ContinueTime 1;
BA_ "GenSigSendType" SG_ 823 DwnLoadDynLtgPrmForFrntLeGrp23HighBrightness 1;
BA_ "GenSigSendType" SG_ 823 DwnLoadDynLtgPrmForFrntLeGrp23LowBrightness 1;
BA_ "GenSigSendType" SG_ 823 DwnLoadDynLtgPrmForFrntLeGrp23Mode1 1;
BA_ "GenSigSendType" SG_ 823 DwnLoadDynLtgPrmForFrntLeGrp23OffsetTime 1;
BA_ "GenSigSendType" SG_ 823 DwnLoadDynLtgPrmForFrntLeGrp23Timestamp 1;
BA_ "GenSigSendType" SG_ 824 DwnLoadDynLtgPrmForFrntLeGrp24ContinueTime 1;
BA_ "GenSigSendType" SG_ 824 DwnLoadDynLtgPrmForFrntLeGrp24HighBrightness 1;
BA_ "GenSigSendType" SG_ 824 DwnLoadDynLtgPrmForFrntLeGrp24LowBrightness 1;
BA_ "GenSigSendType" SG_ 824 DwnLoadDynLtgPrmForFrntLeGrp24Mode1 1;
BA_ "GenSigSendType" SG_ 824 DwnLoadDynLtgPrmForFrntLeGrp24OffsetTime 1;
BA_ "GenSigSendType" SG_ 824 DwnLoadDynLtgPrmForFrntLeGrp24Timestamp 1;
BA_ "GenSigSendType" SG_ 802 DwnLoadDynLtgPrmForFrntLeGrp2ContinueTime 1;
BA_ "GenSigSendType" SG_ 802 DwnLoadDynLtgPrmForFrntLeGrp2HighBrightness 1;
BA_ "GenSigSendType" SG_ 802 DwnLoadDynLtgPrmForFrntLeGrp2LowBrightness 1;
BA_ "GenSigSendType" SG_ 802 DwnLoadDynLtgPrmForFrntLeGrp2Mode1 1;
BA_ "GenSigSendType" SG_ 802 DwnLoadDynLtgPrmForFrntLeGrp2OffsetTime 1;
BA_ "GenSigSendType" SG_ 802 DwnLoadDynLtgPrmForFrntLeGrp2Timestamp 1;
BA_ "GenSigSendType" SG_ 803 DwnLoadDynLtgPrmForFrntLeGrp3ContinueTime 1;
BA_ "GenSigSendType" SG_ 803 DwnLoadDynLtgPrmForFrntLeGrp3HighBrightness 1;
BA_ "GenSigSendType" SG_ 803 DwnLoadDynLtgPrmForFrntLeGrp3LowBrightness 1;
BA_ "GenSigSendType" SG_ 803 DwnLoadDynLtgPrmForFrntLeGrp3Mode1 1;
BA_ "GenSigSendType" SG_ 803 DwnLoadDynLtgPrmForFrntLeGrp3OffsetTime 1;
BA_ "GenSigSendType" SG_ 803 DwnLoadDynLtgPrmForFrntLeGrp3Timestamp 1;
BA_ "GenSigSendType" SG_ 804 DwnLoadDynLtgPrmForFrntLeGrp4ContinueTime 1;
BA_ "GenSigSendType" SG_ 804 DwnLoadDynLtgPrmForFrntLeGrp4HighBrightness 1;
BA_ "GenSigSendType" SG_ 804 DwnLoadDynLtgPrmForFrntLeGrp4LowBrightness 1;
BA_ "GenSigSendType" SG_ 804 DwnLoadDynLtgPrmForFrntLeGrp4Mode1 1;
BA_ "GenSigSendType" SG_ 804 DwnLoadDynLtgPrmForFrntLeGrp4OffsetTime 1;
BA_ "GenSigSendType" SG_ 804 DwnLoadDynLtgPrmForFrntLeGrp4Timestamp 1;
BA_ "GenSigSendType" SG_ 805 DwnLoadDynLtgPrmForFrntLeGrp5ContinueTime 1;
BA_ "GenSigSendType" SG_ 805 DwnLoadDynLtgPrmForFrntLeGrp5HighBrightness 1;
BA_ "GenSigSendType" SG_ 805 DwnLoadDynLtgPrmForFrntLeGrp5LowBrightness 1;
BA_ "GenSigSendType" SG_ 805 DwnLoadDynLtgPrmForFrntLeGrp5Mode1 1;
BA_ "GenSigSendType" SG_ 805 DwnLoadDynLtgPrmForFrntLeGrp5OffsetTime 1;
BA_ "GenSigSendType" SG_ 805 DwnLoadDynLtgPrmForFrntLeGrp5Timestamp 1;
BA_ "GenSigSendType" SG_ 806 DwnLoadDynLtgPrmForFrntLeGrp6ContinueTime 1;
BA_ "GenSigSendType" SG_ 806 DwnLoadDynLtgPrmForFrntLeGrp6HighBrightness 1;
BA_ "GenSigSendType" SG_ 806 DwnLoadDynLtgPrmForFrntLeGrp6LowBrightness 1;
BA_ "GenSigSendType" SG_ 806 DwnLoadDynLtgPrmForFrntLeGrp6Mode1 1;
BA_ "GenSigSendType" SG_ 806 DwnLoadDynLtgPrmForFrntLeGrp6OffsetTime 1;
BA_ "GenSigSendType" SG_ 806 DwnLoadDynLtgPrmForFrntLeGrp6Timestamp 1;
BA_ "GenSigSendType" SG_ 807 DwnLoadDynLtgPrmForFrntLeGrp7ContinueTime 1;
BA_ "GenSigSendType" SG_ 807 DwnLoadDynLtgPrmForFrntLeGrp7HighBrightness 1;
BA_ "GenSigSendType" SG_ 807 DwnLoadDynLtgPrmForFrntLeGrp7LowBrightness 1;
BA_ "GenSigSendType" SG_ 807 DwnLoadDynLtgPrmForFrntLeGrp7Mode1 1;
BA_ "GenSigSendType" SG_ 807 DwnLoadDynLtgPrmForFrntLeGrp7OffsetTime 1;
BA_ "GenSigSendType" SG_ 807 DwnLoadDynLtgPrmForFrntLeGrp7Timestamp 1;
BA_ "GenSigSendType" SG_ 808 DwnLoadDynLtgPrmForFrntLeGrp8ContinueTime 1;
BA_ "GenSigSendType" SG_ 808 DwnLoadDynLtgPrmForFrntLeGrp8HighBrightness 1;
BA_ "GenSigSendType" SG_ 808 DwnLoadDynLtgPrmForFrntLeGrp8LowBrightness 1;
BA_ "GenSigSendType" SG_ 808 DwnLoadDynLtgPrmForFrntLeGrp8Mode1 1;
BA_ "GenSigSendType" SG_ 808 DwnLoadDynLtgPrmForFrntLeGrp8OffsetTime 1;
BA_ "GenSigSendType" SG_ 808 DwnLoadDynLtgPrmForFrntLeGrp8Timestamp 1;
BA_ "GenSigSendType" SG_ 809 DwnLoadDynLtgPrmForFrntLeGrp9ContinueTime 1;
BA_ "GenSigSendType" SG_ 809 DwnLoadDynLtgPrmForFrntLeGrp9HighBrightness 1;
BA_ "GenSigSendType" SG_ 809 DwnLoadDynLtgPrmForFrntLeGrp9LowBrightness 1;
BA_ "GenSigSendType" SG_ 809 DwnLoadDynLtgPrmForFrntLeGrp9Mode1 1;
BA_ "GenSigSendType" SG_ 809 DwnLoadDynLtgPrmForFrntLeGrp9OffsetTime 1;
BA_ "GenSigSendType" SG_ 809 DwnLoadDynLtgPrmForFrntLeGrp9Timestamp 1;
BA_ "GenSigSendType" SG_ 825 DwnLoadDynLtgPrmForFrntRIGrp1ContinueTime 1;
BA_ "GenSigSendType" SG_ 825 DwnLoadDynLtgPrmForFrntRIGrp1HighBrightness 1;
BA_ "GenSigSendType" SG_ 825 DwnLoadDynLtgPrmForFrntRIGrp1LowBrightness 1;
BA_ "GenSigSendType" SG_ 825 DwnLoadDynLtgPrmForFrntRIGrp1Mode1 1;
BA_ "GenSigSendType" SG_ 825 DwnLoadDynLtgPrmForFrntRIGrp1OffsetTime 1;
BA_ "GenSigSendType" SG_ 825 DwnLoadDynLtgPrmForFrntRIGrp1Timestamp 1;
BA_ "GenSigSendType" SG_ 826 DwnLoadDynLtgPrmForFrntRIGrp2ContinueTime 1;
BA_ "GenSigSendType" SG_ 826 DwnLoadDynLtgPrmForFrntRIGrp2HighBrightness 1;
BA_ "GenSigSendType" SG_ 826 DwnLoadDynLtgPrmForFrntRIGrp2LowBrightness 1;
BA_ "GenSigSendType" SG_ 826 DwnLoadDynLtgPrmForFrntRIGrp2Mode1 1;
BA_ "GenSigSendType" SG_ 826 DwnLoadDynLtgPrmForFrntRIGrp2OffsetTime 1;
BA_ "GenSigSendType" SG_ 826 DwnLoadDynLtgPrmForFrntRIGrp2Timestamp 1;
BA_ "GenSigSendType" SG_ 827 DwnLoadDynLtgPrmForFrntRIGrp3ContinueTime 1;
BA_ "GenSigSendType" SG_ 827 DwnLoadDynLtgPrmForFrntRIGrp3HighBrightness 1;
BA_ "GenSigSendType" SG_ 827 DwnLoadDynLtgPrmForFrntRIGrp3LowBrightness 1;
BA_ "GenSigSendType" SG_ 827 DwnLoadDynLtgPrmForFrntRIGrp3Mode1 1;
BA_ "GenSigSendType" SG_ 827 DwnLoadDynLtgPrmForFrntRIGrp3OffsetTime 1;
BA_ "GenSigSendType" SG_ 827 DwnLoadDynLtgPrmForFrntRIGrp3Timestamp 1;
BA_ "GenSigSendType" SG_ 828 DwnLoadDynLtgPrmForFrntRIGrp4ContinueTime 1;
BA_ "GenSigSendType" SG_ 828 DwnLoadDynLtgPrmForFrntRIGrp4HighBrightness 1;
BA_ "GenSigSendType" SG_ 828 DwnLoadDynLtgPrmForFrntRIGrp4LowBrightness 1;
BA_ "GenSigSendType" SG_ 828 DwnLoadDynLtgPrmForFrntRIGrp4Mode1 1;
BA_ "GenSigSendType" SG_ 828 DwnLoadDynLtgPrmForFrntRIGrp4OffsetTime 1;
BA_ "GenSigSendType" SG_ 828 DwnLoadDynLtgPrmForFrntRIGrp4Timestamp 1;
BA_ "GenSigSendType" SG_ 829 DwnLoadDynLtgPrmForFrntRIGrp5ContinueTime 1;
BA_ "GenSigSendType" SG_ 829 DwnLoadDynLtgPrmForFrntRIGrp5HighBrightness 1;
BA_ "GenSigSendType" SG_ 829 DwnLoadDynLtgPrmForFrntRIGrp5LowBrightness 1;
BA_ "GenSigSendType" SG_ 829 DwnLoadDynLtgPrmForFrntRIGrp5Mode1 1;
BA_ "GenSigSendType" SG_ 829 DwnLoadDynLtgPrmForFrntRIGrp5OffsetTime 1;
BA_ "GenSigSendType" SG_ 829 DwnLoadDynLtgPrmForFrntRIGrp5Timestamp 1;
BA_ "GenSigSendType" SG_ 830 DwnLoadDynLtgPrmForFrntRIGrp6ContinueTime 1;
BA_ "GenSigSendType" SG_ 830 DwnLoadDynLtgPrmForFrntRIGrp6HighBrightness 1;
BA_ "GenSigSendType" SG_ 830 DwnLoadDynLtgPrmForFrntRIGrp6LowBrightness 1;
BA_ "GenSigSendType" SG_ 830 DwnLoadDynLtgPrmForFrntRIGrp6Mode1 1;
BA_ "GenSigSendType" SG_ 830 DwnLoadDynLtgPrmForFrntRIGrp6OffsetTime 1;
BA_ "GenSigSendType" SG_ 830 DwnLoadDynLtgPrmForFrntRIGrp6Timestamp 1;
BA_ "GenSigSendType" SG_ 831 DwnLoadDynLtgPrmForFrntRIGrp7ContinueTime 1;
BA_ "GenSigSendType" SG_ 831 DwnLoadDynLtgPrmForFrntRIGrp7HighBrightness 1;
BA_ "GenSigSendType" SG_ 831 DwnLoadDynLtgPrmForFrntRIGrp7LowBrightness 1;
BA_ "GenSigSendType" SG_ 831 DwnLoadDynLtgPrmForFrntRIGrp7Mode1 1;
BA_ "GenSigSendType" SG_ 831 DwnLoadDynLtgPrmForFrntRIGrp7OffsetTime 1;
BA_ "GenSigSendType" SG_ 831 DwnLoadDynLtgPrmForFrntRIGrp7Timestamp 1;
BA_ "GenSigSendType" SG_ 832 DwnLoadDynLtgPrmForFrntRIGrp8ContinueTime 1;
BA_ "GenSigSendType" SG_ 832 DwnLoadDynLtgPrmForFrntRIGrp8HighBrightness 1;
BA_ "GenSigSendType" SG_ 832 DwnLoadDynLtgPrmForFrntRIGrp8LowBrightness 1;
BA_ "GenSigSendType" SG_ 832 DwnLoadDynLtgPrmForFrntRIGrp8Mode1 1;
BA_ "GenSigSendType" SG_ 832 DwnLoadDynLtgPrmForFrntRIGrp8OffsetTime 1;
BA_ "GenSigSendType" SG_ 832 DwnLoadDynLtgPrmForFrntRIGrp8Timestamp 1;
BA_ "GenSigSendType" SG_ 833 DwnLoadDynLtgPrmForFrntRIGrp9ContinueTime 1;
BA_ "GenSigSendType" SG_ 833 DwnLoadDynLtgPrmForFrntRIGrp9HighBrightness 1;
BA_ "GenSigSendType" SG_ 833 DwnLoadDynLtgPrmForFrntRIGrp9LowBrightness 1;
BA_ "GenSigSendType" SG_ 833 DwnLoadDynLtgPrmForFrntRIGrp9Mode1 1;
BA_ "GenSigSendType" SG_ 833 DwnLoadDynLtgPrmForFrntRIGrp9OffsetTime 1;
BA_ "GenSigSendType" SG_ 833 DwnLoadDynLtgPrmForFrntRIGrp9Timestamp 1;
BA_ "GenSigSendType" SG_ 272 SphDvExtnLg 0;
BA_ "GenSigSendType" SG_ 790 VehCfgPrmExt2BlkIDBytePosn1 1;
BA_ "GenSigSendType" SG_ 790 VehCfgPrmExt2CCPBytePosn2 1;
BA_ "GenSigSendType" SG_ 790 VehCfgPrmExt2CCPBytePosn3 1;
BA_ "GenSigSendType" SG_ 790 VehCfgPrmExt2CCPBytePosn4 1;
BA_ "GenSigSendType" SG_ 790 VehCfgPrmExt2CCPBytePosn5 1;
BA_ "GenSigSendType" SG_ 790 VehCfgPrmExt2CCPBytePosn6 1;
BA_ "GenSigSendType" SG_ 790 VehCfgPrmExt2CCPBytePosn7 1;
BA_ "GenSigSendType" SG_ 790 VehCfgPrmExt2CCPBytePosn8 1;
BA_ "GenSigSendType" SG_ 1282 WakeUpReasonsforZCUDM 0;
VAL_ 802 DwnLoadDynLtgPrmForFrntLeGrp2Mode1 0 "Mode4_Off" 1 "Mode4_On" 2 "Mode4_GradualOn" 3 "Mode4_GradualOff" 4 "Mode4_ForwardWipingOn" 5 "Mode4_BackwardWipingOn" 6 "Mode4_OutwardWipingOn" 7 "Mode4_InwardWipingOn" 8 "Mode4_ForwardWipingOff" 9 "Mode4_BackwardWipingOff" 10 "Mode4_OutwardWipingOff" 11 "Mode4_InwardWipingOff" 12 "Mode4_ForwardScanning" 13 "Mode4_BackwardScanning" 14 "Mode4_BreathOn" 15 "Mode4_BreathOff" 16 "Mode4_1stHalfONand2ndHalfOFF" 17 "Mode4_HalfOFFHalfON" 18 "Mode4_HalfDimmingONHalfOFF" 19 "Mode4_HalfDimmingONHalfON" 20 "Mode4_HalfOFFHalfDimmingON" 21 "Mode4_HalfONHalfDimmingON" 22 "Mode4_HalfDimmingOFFHalfOFF" 23 "Mode4_HalfDimmingOFFHalfON" 24 "Mode4_HalfOFFHalfDimmingOFF" 25 "Mode4_HalfONHalfDimmingOFF" 26 "Mode4_SingleOn1" 27 "Mode4_SingleOn2" 28 "Mode4_SingleOn3" 29 "Mode4_SingleOn4" 30 "Mode4_SingleOn5" 31 "Mode4_SingleOn6" 32 "Mode4_SingleOn7" 33 "Mode4_SingleOn8" 34 "Mode4_SingleOn9" 35 "Mode4_SingleOn10" 36 "Mode4_SingleOn11" 37 "Mode4_SingleOn12" 38 "Mode4_SingleOff1" 39 "Mode4_SingleOff2" 40 "Mode4_SingleOff3" 41 "Mode4_SingleOff4" 42 "Mode4_SingleOff5" 43 "Mode4_SingleOff6" 44 "Mode4_SingleOff7" 45 "Mode4_SingleOff8" 46 "Mode4_SingleOff9" 47 "Mode4_SingleOff10" 48 "Mode4_SingleOff11" 49 "Mode4_SingleOff12";
VAL_ 803 DwnLoadDynLtgPrmForFrntLeGrp3Mode1 0 "Mode4_Off" 1 "Mode4_On" 2 "Mode4_GradualOn" 3 "Mode4_GradualOff" 4 "Mode4_ForwardWipingOn" 5 "Mode4_BackwardWipingOn" 6 "Mode4_OutwardWipingOn" 7 "Mode4_InwardWipingOn" 8 "Mode4_ForwardWipingOff" 9 "Mode4_BackwardWipingOff" 10 "Mode4_OutwardWipingOff" 11 "Mode4_InwardWipingOff" 12 "Mode4_ForwardScanning" 13 "Mode4_BackwardScanning" 14 "Mode4_BreathOn" 15 "Mode4_BreathOff" 16 "Mode4_1stHalfONand2ndHalfOFF" 17 "Mode4_HalfOFFHalfON" 18 "Mode4_HalfDimmingONHalfOFF" 19 "Mode4_HalfDimmingONHalfON" 20 "Mode4_HalfOFFHalfDimmingON" 21 "Mode4_HalfONHalfDimmingON" 22 "Mode4_HalfDimmingOFFHalfOFF" 23 "Mode4_HalfDimmingOFFHalfON" 24 "Mode4_HalfOFFHalfDimmingOFF" 25 "Mode4_HalfONHalfDimmingOFF" 26 "Mode4_SingleOn1" 27 "Mode4_SingleOn2" 28 "Mode4_SingleOn3" 29 "Mode4_SingleOn4" 30 "Mode4_SingleOn5" 31 "Mode4_SingleOn6" 32 "Mode4_SingleOn7" 33 "Mode4_SingleOn8" 34 "Mode4_SingleOn9" 35 "Mode4_SingleOn10" 36 "Mode4_SingleOn11" 37 "Mode4_SingleOn12" 38 "Mode4_SingleOff1" 39 "Mode4_SingleOff2" 40 "Mode4_SingleOff3" 41 "Mode4_SingleOff4" 42 "Mode4_SingleOff5" 43 "Mode4_SingleOff6" 44 "Mode4_SingleOff7" 45 "Mode4_SingleOff8" 46 "Mode4_SingleOff9" 47 "Mode4_SingleOff10" 48 "Mode4_SingleOff11" 49 "Mode4_SingleOff12";
VAL_ 804 DwnLoadDynLtgPrmForFrntLeGrp4Mode1 0 "Mode4_Off" 1 "Mode4_On" 2 "Mode4_GradualOn" 3 "Mode4_GradualOff" 4 "Mode4_ForwardWipingOn" 5 "Mode4_BackwardWipingOn" 6 "Mode4_OutwardWipingOn" 7 "Mode4_InwardWipingOn" 8 "Mode4_ForwardWipingOff" 9 "Mode4_BackwardWipingOff" 10 "Mode4_OutwardWipingOff" 11 "Mode4_InwardWipingOff" 12 "Mode4_ForwardScanning" 13 "Mode4_BackwardScanning" 14 "Mode4_BreathOn" 15 "Mode4_BreathOff" 16 "Mode4_1stHalfONand2ndHalfOFF" 17 "Mode4_HalfOFFHalfON" 18 "Mode4_HalfDimmingONHalfOFF" 19 "Mode4_HalfDimmingONHalfON" 20 "Mode4_HalfOFFHalfDimmingON" 21 "Mode4_HalfONHalfDimmingON" 22 "Mode4_HalfDimmingOFFHalfOFF" 23 "Mode4_HalfDimmingOFFHalfON" 24 "Mode4_HalfOFFHalfDimmingOFF" 25 "Mode4_HalfONHalfDimmingOFF" 26 "Mode4_SingleOn1" 27 "Mode4_SingleOn2" 28 "Mode4_SingleOn3" 29 "Mode4_SingleOn4" 30 "Mode4_SingleOn5" 31 "Mode4_SingleOn6" 32 "Mode4_SingleOn7" 33 "Mode4_SingleOn8" 34 "Mode4_SingleOn9" 35 "Mode4_SingleOn10" 36 "Mode4_SingleOn11" 37 "Mode4_SingleOn12" 38 "Mode4_SingleOff1" 39 "Mode4_SingleOff2" 40 "Mode4_SingleOff3" 41 "Mode4_SingleOff4" 42 "Mode4_SingleOff5" 43 "Mode4_SingleOff6" 44 "Mode4_SingleOff7" 45 "Mode4_SingleOff8" 46 "Mode4_SingleOff9" 47 "Mode4_SingleOff10" 48 "Mode4_SingleOff11" 49 "Mode4_SingleOff12";
VAL_ 805 DwnLoadDynLtgPrmForFrntLeGrp5Mode1 0 "Mode4_Off" 1 "Mode4_On" 2 "Mode4_GradualOn" 3 "Mode4_GradualOff" 4 "Mode4_ForwardWipingOn" 5 "Mode4_BackwardWipingOn" 6 "Mode4_OutwardWipingOn" 7 "Mode4_InwardWipingOn" 8 "Mode4_ForwardWipingOff" 9 "Mode4_BackwardWipingOff" 10 "Mode4_OutwardWipingOff" 11 "Mode4_InwardWipingOff" 12 "Mode4_ForwardScanning" 13 "Mode4_BackwardScanning" 14 "Mode4_BreathOn" 15 "Mode4_BreathOff" 16 "Mode4_1stHalfONand2ndHalfOFF" 17 "Mode4_HalfOFFHalfON" 18 "Mode4_HalfDimmingONHalfOFF" 19 "Mode4_HalfDimmingONHalfON" 20 "Mode4_HalfOFFHalfDimmingON" 21 "Mode4_HalfONHalfDimmingON" 22 "Mode4_HalfDimmingOFFHalfOFF" 23 "Mode4_HalfDimmingOFFHalfON" 24 "Mode4_HalfOFFHalfDimmingOFF" 25 "Mode4_HalfONHalfDimmingOFF" 26 "Mode4_SingleOn1" 27 "Mode4_SingleOn2" 28 "Mode4_SingleOn3" 29 "Mode4_SingleOn4" 30 "Mode4_SingleOn5" 31 "Mode4_SingleOn6" 32 "Mode4_SingleOn7" 33 "Mode4_SingleOn8" 34 "Mode4_SingleOn9" 35 "Mode4_SingleOn10" 36 "Mode4_SingleOn11" 37 "Mode4_SingleOn12" 38 "Mode4_SingleOff1" 39 "Mode4_SingleOff2" 40 "Mode4_SingleOff3" 41 "Mode4_SingleOff4" 42 "Mode4_SingleOff5" 43 "Mode4_SingleOff6" 44 "Mode4_SingleOff7" 45 "Mode4_SingleOff8" 46 "Mode4_SingleOff9" 47 "Mode4_SingleOff10" 48 "Mode4_SingleOff11" 49 "Mode4_SingleOff12";
VAL_ 806 DwnLoadDynLtgPrmForFrntLeGrp6Mode1 0 "Mode4_Off" 1 "Mode4_On" 2 "Mode4_GradualOn" 3 "Mode4_GradualOff" 4 "Mode4_ForwardWipingOn" 5 "Mode4_BackwardWipingOn" 6 "Mode4_OutwardWipingOn" 7 "Mode4_InwardWipingOn" 8 "Mode4_ForwardWipingOff" 9 "Mode4_BackwardWipingOff" 10 "Mode4_OutwardWipingOff" 11 "Mode4_InwardWipingOff" 12 "Mode4_ForwardScanning" 13 "Mode4_BackwardScanning" 14 "Mode4_BreathOn" 15 "Mode4_BreathOff" 16 "Mode4_1stHalfONand2ndHalfOFF" 17 "Mode4_HalfOFFHalfON" 18 "Mode4_HalfDimmingONHalfOFF" 19 "Mode4_HalfDimmingONHalfON" 20 "Mode4_HalfOFFHalfDimmingON" 21 "Mode4_HalfONHalfDimmingON" 22 "Mode4_HalfDimmingOFFHalfOFF" 23 "Mode4_HalfDimmingOFFHalfON" 24 "Mode4_HalfOFFHalfDimmingOFF" 25 "Mode4_HalfONHalfDimmingOFF" 26 "Mode4_SingleOn1" 27 "Mode4_SingleOn2" 28 "Mode4_SingleOn3" 29 "Mode4_SingleOn4" 30 "Mode4_SingleOn5" 31 "Mode4_SingleOn6" 32 "Mode4_SingleOn7" 33 "Mode4_SingleOn8" 34 "Mode4_SingleOn9" 35 "Mode4_SingleOn10" 36 "Mode4_SingleOn11" 37 "Mode4_SingleOn12" 38 "Mode4_SingleOff1" 39 "Mode4_SingleOff2" 40 "Mode4_SingleOff3" 41 "Mode4_SingleOff4" 42 "Mode4_SingleOff5" 43 "Mode4_SingleOff6" 44 "Mode4_SingleOff7" 45 "Mode4_SingleOff8" 46 "Mode4_SingleOff9" 47 "Mode4_SingleOff10" 48 "Mode4_SingleOff11" 49 "Mode4_SingleOff12";
VAL_ 807 DwnLoadDynLtgPrmForFrntLeGrp7Mode1 0 "Mode4_Off" 1 "Mode4_On" 2 "Mode4_GradualOn" 3 "Mode4_GradualOff" 4 "Mode4_ForwardWipingOn" 5 "Mode4_BackwardWipingOn" 6 "Mode4_OutwardWipingOn" 7 "Mode4_InwardWipingOn" 8 "Mode4_ForwardWipingOff" 9 "Mode4_BackwardWipingOff" 10 "Mode4_OutwardWipingOff" 11 "Mode4_InwardWipingOff" 12 "Mode4_ForwardScanning" 13 "Mode4_BackwardScanning" 14 "Mode4_BreathOn" 15 "Mode4_BreathOff" 16 "Mode4_1stHalfONand2ndHalfOFF" 17 "Mode4_HalfOFFHalfON" 18 "Mode4_HalfDimmingONHalfOFF" 19 "Mode4_HalfDimmingONHalfON" 20 "Mode4_HalfOFFHalfDimmingON" 21 "Mode4_HalfONHalfDimmingON" 22 "Mode4_HalfDimmingOFFHalfOFF" 23 "Mode4_HalfDimmingOFFHalfON" 24 "Mode4_HalfOFFHalfDimmingOFF" 25 "Mode4_HalfONHalfDimmingOFF" 26 "Mode4_SingleOn1" 27 "Mode4_SingleOn2" 28 "Mode4_SingleOn3" 29 "Mode4_SingleOn4" 30 "Mode4_SingleOn5" 31 "Mode4_SingleOn6" 32 "Mode4_SingleOn7" 33 "Mode4_SingleOn8" 34 "Mode4_SingleOn9" 35 "Mode4_SingleOn10" 36 "Mode4_SingleOn11" 37 "Mode4_SingleOn12" 38 "Mode4_SingleOff1" 39 "Mode4_SingleOff2" 40 "Mode4_SingleOff3" 41 "Mode4_SingleOff4" 42 "Mode4_SingleOff5" 43 "Mode4_SingleOff6" 44 "Mode4_SingleOff7" 45 "Mode4_SingleOff8" 46 "Mode4_SingleOff9" 47 "Mode4_SingleOff10" 48 "Mode4_SingleOff11" 49 "Mode4_SingleOff12";
VAL_ 808 DwnLoadDynLtgPrmForFrntLeGrp8Mode1 0 "Mode4_Off" 1 "Mode4_On" 2 "Mode4_GradualOn" 3 "Mode4_GradualOff" 4 "Mode4_ForwardWipingOn" 5 "Mode4_BackwardWipingOn" 6 "Mode4_OutwardWipingOn" 7 "Mode4_InwardWipingOn" 8 "Mode4_ForwardWipingOff" 9 "Mode4_BackwardWipingOff" 10 "Mode4_OutwardWipingOff" 11 "Mode4_InwardWipingOff" 12 "Mode4_ForwardScanning" 13 "Mode4_BackwardScanning" 14 "Mode4_BreathOn" 15 "Mode4_BreathOff" 16 "Mode4_1stHalfONand2ndHalfOFF" 17 "Mode4_HalfOFFHalfON" 18 "Mode4_HalfDimmingONHalfOFF" 19 "Mode4_HalfDimmingONHalfON" 20 "Mode4_HalfOFFHalfDimmingON" 21 "Mode4_HalfONHalfDimmingON" 22 "Mode4_HalfDimmingOFFHalfOFF" 23 "Mode4_HalfDimmingOFFHalfON" 24 "Mode4_HalfOFFHalfDimmingOFF" 25 "Mode4_HalfONHalfDimmingOFF" 26 "Mode4_SingleOn1" 27 "Mode4_SingleOn2" 28 "Mode4_SingleOn3" 29 "Mode4_SingleOn4" 30 "Mode4_SingleOn5" 31 "Mode4_SingleOn6" 32 "Mode4_SingleOn7" 33 "Mode4_SingleOn8" 34 "Mode4_SingleOn9" 35 "Mode4_SingleOn10" 36 "Mode4_SingleOn11" 37 "Mode4_SingleOn12" 38 "Mode4_SingleOff1" 39 "Mode4_SingleOff2" 40 "Mode4_SingleOff3" 41 "Mode4_SingleOff4" 42 "Mode4_SingleOff5" 43 "Mode4_SingleOff6" 44 "Mode4_SingleOff7" 45 "Mode4_SingleOff8" 46 "Mode4_SingleOff9" 47 "Mode4_SingleOff10" 48 "Mode4_SingleOff11" 49 "Mode4_SingleOff12";
VAL_ 809 DwnLoadDynLtgPrmForFrntLeGrp9Mode1 0 "Mode4_Off" 1 "Mode4_On" 2 "Mode4_GradualOn" 3 "Mode4_GradualOff" 4 "Mode4_ForwardWipingOn" 5 "Mode4_BackwardWipingOn" 6 "Mode4_OutwardWipingOn" 7 "Mode4_InwardWipingOn" 8 "Mode4_ForwardWipingOff" 9 "Mode4_BackwardWipingOff" 10 "Mode4_OutwardWipingOff" 11 "Mode4_InwardWipingOff" 12 "Mode4_ForwardScanning" 13 "Mode4_BackwardScanning" 14 "Mode4_BreathOn" 15 "Mode4_BreathOff" 16 "Mode4_1stHalfONand2ndHalfOFF" 17 "Mode4_HalfOFFHalfON" 18 "Mode4_HalfDimmingONHalfOFF" 19 "Mode4_HalfDimmingONHalfON" 20 "Mode4_HalfOFFHalfDimmingON" 21 "Mode4_HalfONHalfDimmingON" 22 "Mode4_HalfDimmingOFFHalfOFF" 23 "Mode4_HalfDimmingOFFHalfON" 24 "Mode4_HalfOFFHalfDimmingOFF" 25 "Mode4_HalfONHalfDimmingOFF" 26 "Mode4_SingleOn1" 27 "Mode4_SingleOn2" 28 "Mode4_SingleOn3" 29 "Mode4_SingleOn4" 30 "Mode4_SingleOn5" 31 "Mode4_SingleOn6" 32 "Mode4_SingleOn7" 33 "Mode4_SingleOn8" 34 "Mode4_SingleOn9" 35 "Mode4_SingleOn10" 36 "Mode4_SingleOn11" 37 "Mode4_SingleOn12" 38 "Mode4_SingleOff1" 39 "Mode4_SingleOff2" 40 "Mode4_SingleOff3" 41 "Mode4_SingleOff4" 42 "Mode4_SingleOff5" 43 "Mode4_SingleOff6" 44 "Mode4_SingleOff7" 45 "Mode4_SingleOff8" 46 "Mode4_SingleOff9" 47 "Mode4_SingleOff10" 48 "Mode4_SingleOff11" 49 "Mode4_SingleOff12";
VAL_ 810 DwnLoadDynLtgPrmForFrntLeGrp10Mode1 0 "Mode4_Off" 1 "Mode4_On" 2 "Mode4_GradualOn" 3 "Mode4_GradualOff" 4 "Mode4_ForwardWipingOn" 5 "Mode4_BackwardWipingOn" 6 "Mode4_OutwardWipingOn" 7 "Mode4_InwardWipingOn" 8 "Mode4_ForwardWipingOff" 9 "Mode4_BackwardWipingOff" 10 "Mode4_OutwardWipingOff" 11 "Mode4_InwardWipingOff" 12 "Mode4_ForwardScanning" 13 "Mode4_BackwardScanning" 14 "Mode4_BreathOn" 15 "Mode4_BreathOff" 16 "Mode4_1stHalfONand2ndHalfOFF" 17 "Mode4_HalfOFFHalfON" 18 "Mode4_HalfDimmingONHalfOFF" 19 "Mode4_HalfDimmingONHalfON" 20 "Mode4_HalfOFFHalfDimmingON" 21 "Mode4_HalfONHalfDimmingON" 22 "Mode4_HalfDimmingOFFHalfOFF" 23 "Mode4_HalfDimmingOFFHalfON" 24 "Mode4_HalfOFFHalfDimmingOFF" 25 "Mode4_HalfONHalfDimmingOFF" 26 "Mode4_SingleOn1" 27 "Mode4_SingleOn2" 28 "Mode4_SingleOn3" 29 "Mode4_SingleOn4" 30 "Mode4_SingleOn5" 31 "Mode4_SingleOn6" 32 "Mode4_SingleOn7" 33 "Mode4_SingleOn8" 34 "Mode4_SingleOn9" 35 "Mode4_SingleOn10" 36 "Mode4_SingleOn11" 37 "Mode4_SingleOn12" 38 "Mode4_SingleOff1" 39 "Mode4_SingleOff2" 40 "Mode4_SingleOff3" 41 "Mode4_SingleOff4" 42 "Mode4_SingleOff5" 43 "Mode4_SingleOff6" 44 "Mode4_SingleOff7" 45 "Mode4_SingleOff8" 46 "Mode4_SingleOff9" 47 "Mode4_SingleOff10" 48 "Mode4_SingleOff11" 49 "Mode4_SingleOff12";
VAL_ 811 DwnLoadDynLtgPrmForFrntLeGrp11Mode1 0 "Mode4_Off" 1 "Mode4_On" 2 "Mode4_GradualOn" 3 "Mode4_GradualOff" 4 "Mode4_ForwardWipingOn" 5 "Mode4_BackwardWipingOn" 6 "Mode4_OutwardWipingOn" 7 "Mode4_InwardWipingOn" 8 "Mode4_ForwardWipingOff" 9 "Mode4_BackwardWipingOff" 10 "Mode4_OutwardWipingOff" 11 "Mode4_InwardWipingOff" 12 "Mode4_ForwardScanning" 13 "Mode4_BackwardScanning" 14 "Mode4_BreathOn" 15 "Mode4_BreathOff" 16 "Mode4_1stHalfONand2ndHalfOFF" 17 "Mode4_HalfOFFHalfON" 18 "Mode4_HalfDimmingONHalfOFF" 19 "Mode4_HalfDimmingONHalfON" 20 "Mode4_HalfOFFHalfDimmingON" 21 "Mode4_HalfONHalfDimmingON" 22 "Mode4_HalfDimmingOFFHalfOFF" 23 "Mode4_HalfDimmingOFFHalfON" 24 "Mode4_HalfOFFHalfDimmingOFF" 25 "Mode4_HalfONHalfDimmingOFF" 26 "Mode4_SingleOn1" 27 "Mode4_SingleOn2" 28 "Mode4_SingleOn3" 29 "Mode4_SingleOn4" 30 "Mode4_SingleOn5" 31 "Mode4_SingleOn6" 32 "Mode4_SingleOn7" 33 "Mode4_SingleOn8" 34 "Mode4_SingleOn9" 35 "Mode4_SingleOn10" 36 "Mode4_SingleOn11" 37 "Mode4_SingleOn12" 38 "Mode4_SingleOff1" 39 "Mode4_SingleOff2" 40 "Mode4_SingleOff3" 41 "Mode4_SingleOff4" 42 "Mode4_SingleOff5" 43 "Mode4_SingleOff6" 44 "Mode4_SingleOff7" 45 "Mode4_SingleOff8" 46 "Mode4_SingleOff9" 47 "Mode4_SingleOff10" 48 "Mode4_SingleOff11" 49 "Mode4_SingleOff12";
VAL_ 812 DwnLoadDynLtgPrmForFrntLeGrp12Mode1 0 "Mode4_Off" 1 "Mode4_On" 2 "Mode4_GradualOn" 3 "Mode4_GradualOff" 4 "Mode4_ForwardWipingOn" 5 "Mode4_BackwardWipingOn" 6 "Mode4_OutwardWipingOn" 7 "Mode4_InwardWipingOn" 8 "Mode4_ForwardWipingOff" 9 "Mode4_BackwardWipingOff" 10 "Mode4_OutwardWipingOff" 11 "Mode4_InwardWipingOff" 12 "Mode4_ForwardScanning" 13 "Mode4_BackwardScanning" 14 "Mode4_BreathOn" 15 "Mode4_BreathOff" 16 "Mode4_1stHalfONand2ndHalfOFF" 17 "Mode4_HalfOFFHalfON" 18 "Mode4_HalfDimmingONHalfOFF" 19 "Mode4_HalfDimmingONHalfON" 20 "Mode4_HalfOFFHalfDimmingON" 21 "Mode4_HalfONHalfDimmingON" 22 "Mode4_HalfDimmingOFFHalfOFF" 23 "Mode4_HalfDimmingOFFHalfON" 24 "Mode4_HalfOFFHalfDimmingOFF" 25 "Mode4_HalfONHalfDimmingOFF" 26 "Mode4_SingleOn1" 27 "Mode4_SingleOn2" 28 "Mode4_SingleOn3" 29 "Mode4_SingleOn4" 30 "Mode4_SingleOn5" 31 "Mode4_SingleOn6" 32 "Mode4_SingleOn7" 33 "Mode4_SingleOn8" 34 "Mode4_SingleOn9" 35 "Mode4_SingleOn10" 36 "Mode4_SingleOn11" 37 "Mode4_SingleOn12" 38 "Mode4_SingleOff1" 39 "Mode4_SingleOff2" 40 "Mode4_SingleOff3" 41 "Mode4_SingleOff4" 42 "Mode4_SingleOff5" 43 "Mode4_SingleOff6" 44 "Mode4_SingleOff7" 45 "Mode4_SingleOff8" 46 "Mode4_SingleOff9" 47 "Mode4_SingleOff10" 48 "Mode4_SingleOff11" 49 "Mode4_SingleOff12";
VAL_ 813 DwnLoadDynLtgPrmForFrntLeGrp13Mode1 0 "Mode4_Off" 1 "Mode4_On" 2 "Mode4_GradualOn" 3 "Mode4_GradualOff" 4 "Mode4_ForwardWipingOn" 5 "Mode4_BackwardWipingOn" 6 "Mode4_OutwardWipingOn" 7 "Mode4_InwardWipingOn" 8 "Mode4_ForwardWipingOff" 9 "Mode4_BackwardWipingOff" 10 "Mode4_OutwardWipingOff" 11 "Mode4_InwardWipingOff" 12 "Mode4_ForwardScanning" 13 "Mode4_BackwardScanning" 14 "Mode4_BreathOn" 15 "Mode4_BreathOff" 16 "Mode4_1stHalfONand2ndHalfOFF" 17 "Mode4_HalfOFFHalfON" 18 "Mode4_HalfDimmingONHalfOFF" 19 "Mode4_HalfDimmingONHalfON" 20 "Mode4_HalfOFFHalfDimmingON" 21 "Mode4_HalfONHalfDimmingON" 22 "Mode4_HalfDimmingOFFHalfOFF" 23 "Mode4_HalfDimmingOFFHalfON" 24 "Mode4_HalfOFFHalfDimmingOFF" 25 "Mode4_HalfONHalfDimmingOFF" 26 "Mode4_SingleOn1" 27 "Mode4_SingleOn2" 28 "Mode4_SingleOn3" 29 "Mode4_SingleOn4" 30 "Mode4_SingleOn5" 31 "Mode4_SingleOn6" 32 "Mode4_SingleOn7" 33 "Mode4_SingleOn8" 34 "Mode4_SingleOn9" 35 "Mode4_SingleOn10" 36 "Mode4_SingleOn11" 37 "Mode4_SingleOn12" 38 "Mode4_SingleOff1" 39 "Mode4_SingleOff2" 40 "Mode4_SingleOff3" 41 "Mode4_SingleOff4" 42 "Mode4_SingleOff5" 43 "Mode4_SingleOff6" 44 "Mode4_SingleOff7" 45 "Mode4_SingleOff8" 46 "Mode4_SingleOff9" 47 "Mode4_SingleOff10" 48 "Mode4_SingleOff11" 49 "Mode4_SingleOff12";
VAL_ 814 DwnLoadDynLtgPrmForFrntLeGrp14Mode1 0 "Mode4_Off" 1 "Mode4_On" 2 "Mode4_GradualOn" 3 "Mode4_GradualOff" 4 "Mode4_ForwardWipingOn" 5 "Mode4_BackwardWipingOn" 6 "Mode4_OutwardWipingOn" 7 "Mode4_InwardWipingOn" 8 "Mode4_ForwardWipingOff" 9 "Mode4_BackwardWipingOff" 10 "Mode4_OutwardWipingOff" 11 "Mode4_InwardWipingOff" 12 "Mode4_ForwardScanning" 13 "Mode4_BackwardScanning" 14 "Mode4_BreathOn" 15 "Mode4_BreathOff" 16 "Mode4_1stHalfONand2ndHalfOFF" 17 "Mode4_HalfOFFHalfON" 18 "Mode4_HalfDimmingONHalfOFF" 19 "Mode4_HalfDimmingONHalfON" 20 "Mode4_HalfOFFHalfDimmingON" 21 "Mode4_HalfONHalfDimmingON" 22 "Mode4_HalfDimmingOFFHalfOFF" 23 "Mode4_HalfDimmingOFFHalfON" 24 "Mode4_HalfOFFHalfDimmingOFF" 25 "Mode4_HalfONHalfDimmingOFF" 26 "Mode4_SingleOn1" 27 "Mode4_SingleOn2" 28 "Mode4_SingleOn3" 29 "Mode4_SingleOn4" 30 "Mode4_SingleOn5" 31 "Mode4_SingleOn6" 32 "Mode4_SingleOn7" 33 "Mode4_SingleOn8" 34 "Mode4_SingleOn9" 35 "Mode4_SingleOn10" 36 "Mode4_SingleOn11" 37 "Mode4_SingleOn12" 38 "Mode4_SingleOff1" 39 "Mode4_SingleOff2" 40 "Mode4_SingleOff3" 41 "Mode4_SingleOff4" 42 "Mode4_SingleOff5" 43 "Mode4_SingleOff6" 44 "Mode4_SingleOff7" 45 "Mode4_SingleOff8" 46 "Mode4_SingleOff9" 47 "Mode4_SingleOff10" 48 "Mode4_SingleOff11" 49 "Mode4_SingleOff12";
VAL_ 815 DwnLoadDynLtgPrmForFrntLeGrp15Mode1 0 "Mode4_Off" 1 "Mode4_On" 2 "Mode4_GradualOn" 3 "Mode4_GradualOff" 4 "Mode4_ForwardWipingOn" 5 "Mode4_BackwardWipingOn" 6 "Mode4_OutwardWipingOn" 7 "Mode4_InwardWipingOn" 8 "Mode4_ForwardWipingOff" 9 "Mode4_BackwardWipingOff" 10 "Mode4_OutwardWipingOff" 11 "Mode4_InwardWipingOff" 12 "Mode4_ForwardScanning" 13 "Mode4_BackwardScanning" 14 "Mode4_BreathOn" 15 "Mode4_BreathOff" 16 "Mode4_1stHalfONand2ndHalfOFF" 17 "Mode4_HalfOFFHalfON" 18 "Mode4_HalfDimmingONHalfOFF" 19 "Mode4_HalfDimmingONHalfON" 20 "Mode4_HalfOFFHalfDimmingON" 21 "Mode4_HalfONHalfDimmingON" 22 "Mode4_HalfDimmingOFFHalfOFF" 23 "Mode4_HalfDimmingOFFHalfON" 24 "Mode4_HalfOFFHalfDimmingOFF" 25 "Mode4_HalfONHalfDimmingOFF" 26 "Mode4_SingleOn1" 27 "Mode4_SingleOn2" 28 "Mode4_SingleOn3" 29 "Mode4_SingleOn4" 30 "Mode4_SingleOn5" 31 "Mode4_SingleOn6" 32 "Mode4_SingleOn7" 33 "Mode4_SingleOn8" 34 "Mode4_SingleOn9" 35 "Mode4_SingleOn10" 36 "Mode4_SingleOn11" 37 "Mode4_SingleOn12" 38 "Mode4_SingleOff1" 39 "Mode4_SingleOff2" 40 "Mode4_SingleOff3" 41 "Mode4_SingleOff4" 42 "Mode4_SingleOff5" 43 "Mode4_SingleOff6" 44 "Mode4_SingleOff7" 45 "Mode4_SingleOff8" 46 "Mode4_SingleOff9" 47 "Mode4_SingleOff10" 48 "Mode4_SingleOff11" 49 "Mode4_SingleOff12";
VAL_ 816 DwnLoadDynLtgPrmForFrntLeGrp16Mode1 0 "Mode4_Off" 1 "Mode4_On" 2 "Mode4_GradualOn" 3 "Mode4_GradualOff" 4 "Mode4_ForwardWipingOn" 5 "Mode4_BackwardWipingOn" 6 "Mode4_OutwardWipingOn" 7 "Mode4_InwardWipingOn" 8 "Mode4_ForwardWipingOff" 9 "Mode4_BackwardWipingOff" 10 "Mode4_OutwardWipingOff" 11 "Mode4_InwardWipingOff" 12 "Mode4_ForwardScanning" 13 "Mode4_BackwardScanning" 14 "Mode4_BreathOn" 15 "Mode4_BreathOff" 16 "Mode4_1stHalfONand2ndHalfOFF" 17 "Mode4_HalfOFFHalfON" 18 "Mode4_HalfDimmingONHalfOFF" 19 "Mode4_HalfDimmingONHalfON" 20 "Mode4_HalfOFFHalfDimmingON" 21 "Mode4_HalfONHalfDimmingON" 22 "Mode4_HalfDimmingOFFHalfOFF" 23 "Mode4_HalfDimmingOFFHalfON" 24 "Mode4_HalfOFFHalfDimmingOFF" 25 "Mode4_HalfONHalfDimmingOFF" 26 "Mode4_SingleOn1" 27 "Mode4_SingleOn2" 28 "Mode4_SingleOn3" 29 "Mode4_SingleOn4" 30 "Mode4_SingleOn5" 31 "Mode4_SingleOn6" 32 "Mode4_SingleOn7" 33 "Mode4_SingleOn8" 34 "Mode4_SingleOn9" 35 "Mode4_SingleOn10" 36 "Mode4_SingleOn11" 37 "Mode4_SingleOn12" 38 "Mode4_SingleOff1" 39 "Mode4_SingleOff2" 40 "Mode4_SingleOff3" 41 "Mode4_SingleOff4" 42 "Mode4_SingleOff5" 43 "Mode4_SingleOff6" 44 "Mode4_SingleOff7" 45 "Mode4_SingleOff8" 46 "Mode4_SingleOff9" 47 "Mode4_SingleOff10" 48 "Mode4_SingleOff11" 49 "Mode4_SingleOff12";
VAL_ 817 DwnLoadDynLtgPrmForFrntLeGrp17Mode1 0 "Mode4_Off" 1 "Mode4_On" 2 "Mode4_GradualOn" 3 "Mode4_GradualOff" 4 "Mode4_ForwardWipingOn" 5 "Mode4_BackwardWipingOn" 6 "Mode4_OutwardWipingOn" 7 "Mode4_InwardWipingOn" 8 "Mode4_ForwardWipingOff" 9 "Mode4_BackwardWipingOff" 10 "Mode4_OutwardWipingOff" 11 "Mode4_InwardWipingOff" 12 "Mode4_ForwardScanning" 13 "Mode4_BackwardScanning" 14 "Mode4_BreathOn" 15 "Mode4_BreathOff" 16 "Mode4_1stHalfONand2ndHalfOFF" 17 "Mode4_HalfOFFHalfON" 18 "Mode4_HalfDimmingONHalfOFF" 19 "Mode4_HalfDimmingONHalfON" 20 "Mode4_HalfOFFHalfDimmingON" 21 "Mode4_HalfONHalfDimmingON" 22 "Mode4_HalfDimmingOFFHalfOFF" 23 "Mode4_HalfDimmingOFFHalfON" 24 "Mode4_HalfOFFHalfDimmingOFF" 25 "Mode4_HalfONHalfDimmingOFF" 26 "Mode4_SingleOn1" 27 "Mode4_SingleOn2" 28 "Mode4_SingleOn3" 29 "Mode4_SingleOn4" 30 "Mode4_SingleOn5" 31 "Mode4_SingleOn6" 32 "Mode4_SingleOn7" 33 "Mode4_SingleOn8" 34 "Mode4_SingleOn9" 35 "Mode4_SingleOn10" 36 "Mode4_SingleOn11" 37 "Mode4_SingleOn12" 38 "Mode4_SingleOff1" 39 "Mode4_SingleOff2" 40 "Mode4_SingleOff3" 41 "Mode4_SingleOff4" 42 "Mode4_SingleOff5" 43 "Mode4_SingleOff6" 44 "Mode4_SingleOff7" 45 "Mode4_SingleOff8" 46 "Mode4_SingleOff9" 47 "Mode4_SingleOff10" 48 "Mode4_SingleOff11" 49 "Mode4_SingleOff12";
VAL_ 818 DwnLoadDynLtgPrmForFrntLeGrp18Mode1 0 "Mode4_Off" 1 "Mode4_On" 2 "Mode4_GradualOn" 3 "Mode4_GradualOff" 4 "Mode4_ForwardWipingOn" 5 "Mode4_BackwardWipingOn" 6 "Mode4_OutwardWipingOn" 7 "Mode4_InwardWipingOn" 8 "Mode4_ForwardWipingOff" 9 "Mode4_BackwardWipingOff" 10 "Mode4_OutwardWipingOff" 11 "Mode4_InwardWipingOff" 12 "Mode4_ForwardScanning" 13 "Mode4_BackwardScanning" 14 "Mode4_BreathOn" 15 "Mode4_BreathOff" 16 "Mode4_1stHalfONand2ndHalfOFF" 17 "Mode4_HalfOFFHalfON" 18 "Mode4_HalfDimmingONHalfOFF" 19 "Mode4_HalfDimmingONHalfON" 20 "Mode4_HalfOFFHalfDimmingON" 21 "Mode4_HalfONHalfDimmingON" 22 "Mode4_HalfDimmingOFFHalfOFF" 23 "Mode4_HalfDimmingOFFHalfON" 24 "Mode4_HalfOFFHalfDimmingOFF" 25 "Mode4_HalfONHalfDimmingOFF" 26 "Mode4_SingleOn1" 27 "Mode4_SingleOn2" 28 "Mode4_SingleOn3" 29 "Mode4_SingleOn4" 30 "Mode4_SingleOn5" 31 "Mode4_SingleOn6" 32 "Mode4_SingleOn7" 33 "Mode4_SingleOn8" 34 "Mode4_SingleOn9" 35 "Mode4_SingleOn10" 36 "Mode4_SingleOn11" 37 "Mode4_SingleOn12" 38 "Mode4_SingleOff1" 39 "Mode4_SingleOff2" 40 "Mode4_SingleOff3" 41 "Mode4_SingleOff4" 42 "Mode4_SingleOff5" 43 "Mode4_SingleOff6" 44 "Mode4_SingleOff7" 45 "Mode4_SingleOff8" 46 "Mode4_SingleOff9" 47 "Mode4_SingleOff10" 48 "Mode4_SingleOff11" 49 "Mode4_SingleOff12";
VAL_ 819 DwnLoadDynLtgPrmForFrntLeGrp19Mode1 0 "Mode4_Off" 1 "Mode4_On" 2 "Mode4_GradualOn" 3 "Mode4_GradualOff" 4 "Mode4_ForwardWipingOn" 5 "Mode4_BackwardWipingOn" 6 "Mode4_OutwardWipingOn" 7 "Mode4_InwardWipingOn" 8 "Mode4_ForwardWipingOff" 9 "Mode4_BackwardWipingOff" 10 "Mode4_OutwardWipingOff" 11 "Mode4_InwardWipingOff" 12 "Mode4_ForwardScanning" 13 "Mode4_BackwardScanning" 14 "Mode4_BreathOn" 15 "Mode4_BreathOff" 16 "Mode4_1stHalfONand2ndHalfOFF" 17 "Mode4_HalfOFFHalfON" 18 "Mode4_HalfDimmingONHalfOFF" 19 "Mode4_HalfDimmingONHalfON" 20 "Mode4_HalfOFFHalfDimmingON" 21 "Mode4_HalfONHalfDimmingON" 22 "Mode4_HalfDimmingOFFHalfOFF" 23 "Mode4_HalfDimmingOFFHalfON" 24 "Mode4_HalfOFFHalfDimmingOFF" 25 "Mode4_HalfONHalfDimmingOFF" 26 "Mode4_SingleOn1" 27 "Mode4_SingleOn2" 28 "Mode4_SingleOn3" 29 "Mode4_SingleOn4" 30 "Mode4_SingleOn5" 31 "Mode4_SingleOn6" 32 "Mode4_SingleOn7" 33 "Mode4_SingleOn8" 34 "Mode4_SingleOn9" 35 "Mode4_SingleOn10" 36 "Mode4_SingleOn11" 37 "Mode4_SingleOn12" 38 "Mode4_SingleOff1" 39 "Mode4_SingleOff2" 40 "Mode4_SingleOff3" 41 "Mode4_SingleOff4" 42 "Mode4_SingleOff5" 43 "Mode4_SingleOff6" 44 "Mode4_SingleOff7" 45 "Mode4_SingleOff8" 46 "Mode4_SingleOff9" 47 "Mode4_SingleOff10" 48 "Mode4_SingleOff11" 49 "Mode4_SingleOff12";
VAL_ 820 DwnLoadDynLtgPrmForFrntLeGrp20Mode1 0 "Mode4_Off" 1 "Mode4_On" 2 "Mode4_GradualOn" 3 "Mode4_GradualOff" 4 "Mode4_ForwardWipingOn" 5 "Mode4_BackwardWipingOn" 6 "Mode4_OutwardWipingOn" 7 "Mode4_InwardWipingOn" 8 "Mode4_ForwardWipingOff" 9 "Mode4_BackwardWipingOff" 10 "Mode4_OutwardWipingOff" 11 "Mode4_InwardWipingOff" 12 "Mode4_ForwardScanning" 13 "Mode4_BackwardScanning" 14 "Mode4_BreathOn" 15 "Mode4_BreathOff" 16 "Mode4_1stHalfONand2ndHalfOFF" 17 "Mode4_HalfOFFHalfON" 18 "Mode4_HalfDimmingONHalfOFF" 19 "Mode4_HalfDimmingONHalfON" 20 "Mode4_HalfOFFHalfDimmingON" 21 "Mode4_HalfONHalfDimmingON" 22 "Mode4_HalfDimmingOFFHalfOFF" 23 "Mode4_HalfDimmingOFFHalfON" 24 "Mode4_HalfOFFHalfDimmingOFF" 25 "Mode4_HalfONHalfDimmingOFF" 26 "Mode4_SingleOn1" 27 "Mode4_SingleOn2" 28 "Mode4_SingleOn3" 29 "Mode4_SingleOn4" 30 "Mode4_SingleOn5" 31 "Mode4_SingleOn6" 32 "Mode4_SingleOn7" 33 "Mode4_SingleOn8" 34 "Mode4_SingleOn9" 35 "Mode4_SingleOn10" 36 "Mode4_SingleOn11" 37 "Mode4_SingleOn12" 38 "Mode4_SingleOff1" 39 "Mode4_SingleOff2" 40 "Mode4_SingleOff3" 41 "Mode4_SingleOff4" 42 "Mode4_SingleOff5" 43 "Mode4_SingleOff6" 44 "Mode4_SingleOff7" 45 "Mode4_SingleOff8" 46 "Mode4_SingleOff9" 47 "Mode4_SingleOff10" 48 "Mode4_SingleOff11" 49 "Mode4_SingleOff12";
VAL_ 821 DwnLoadDynLtgPrmForFrntLeGrp21Mode1 0 "Mode4_Off" 1 "Mode4_On" 2 "Mode4_GradualOn" 3 "Mode4_GradualOff" 4 "Mode4_ForwardWipingOn" 5 "Mode4_BackwardWipingOn" 6 "Mode4_OutwardWipingOn" 7 "Mode4_InwardWipingOn" 8 "Mode4_ForwardWipingOff" 9 "Mode4_BackwardWipingOff" 10 "Mode4_OutwardWipingOff" 11 "Mode4_InwardWipingOff" 12 "Mode4_ForwardScanning" 13 "Mode4_BackwardScanning" 14 "Mode4_BreathOn" 15 "Mode4_BreathOff" 16 "Mode4_1stHalfONand2ndHalfOFF" 17 "Mode4_HalfOFFHalfON" 18 "Mode4_HalfDimmingONHalfOFF" 19 "Mode4_HalfDimmingONHalfON" 20 "Mode4_HalfOFFHalfDimmingON" 21 "Mode4_HalfONHalfDimmingON" 22 "Mode4_HalfDimmingOFFHalfOFF" 23 "Mode4_HalfDimmingOFFHalfON" 24 "Mode4_HalfOFFHalfDimmingOFF" 25 "Mode4_HalfONHalfDimmingOFF" 26 "Mode4_SingleOn1" 27 "Mode4_SingleOn2" 28 "Mode4_SingleOn3" 29 "Mode4_SingleOn4" 30 "Mode4_SingleOn5" 31 "Mode4_SingleOn6" 32 "Mode4_SingleOn7" 33 "Mode4_SingleOn8" 34 "Mode4_SingleOn9" 35 "Mode4_SingleOn10" 36 "Mode4_SingleOn11" 37 "Mode4_SingleOn12" 38 "Mode4_SingleOff1" 39 "Mode4_SingleOff2" 40 "Mode4_SingleOff3" 41 "Mode4_SingleOff4" 42 "Mode4_SingleOff5" 43 "Mode4_SingleOff6" 44 "Mode4_SingleOff7" 45 "Mode4_SingleOff8" 46 "Mode4_SingleOff9" 47 "Mode4_SingleOff10" 48 "Mode4_SingleOff11" 49 "Mode4_SingleOff12";
VAL_ 822 DwnLoadDynLtgPrmForFrntLeGrp22Mode1 0 "Mode4_Off" 1 "Mode4_On" 2 "Mode4_GradualOn" 3 "Mode4_GradualOff" 4 "Mode4_ForwardWipingOn" 5 "Mode4_BackwardWipingOn" 6 "Mode4_OutwardWipingOn" 7 "Mode4_InwardWipingOn" 8 "Mode4_ForwardWipingOff" 9 "Mode4_BackwardWipingOff" 10 "Mode4_OutwardWipingOff" 11 "Mode4_InwardWipingOff" 12 "Mode4_ForwardScanning" 13 "Mode4_BackwardScanning" 14 "Mode4_BreathOn" 15 "Mode4_BreathOff" 16 "Mode4_1stHalfONand2ndHalfOFF" 17 "Mode4_HalfOFFHalfON" 18 "Mode4_HalfDimmingONHalfOFF" 19 "Mode4_HalfDimmingONHalfON" 20 "Mode4_HalfOFFHalfDimmingON" 21 "Mode4_HalfONHalfDimmingON" 22 "Mode4_HalfDimmingOFFHalfOFF" 23 "Mode4_HalfDimmingOFFHalfON" 24 "Mode4_HalfOFFHalfDimmingOFF" 25 "Mode4_HalfONHalfDimmingOFF" 26 "Mode4_SingleOn1" 27 "Mode4_SingleOn2" 28 "Mode4_SingleOn3" 29 "Mode4_SingleOn4" 30 "Mode4_SingleOn5" 31 "Mode4_SingleOn6" 32 "Mode4_SingleOn7" 33 "Mode4_SingleOn8" 34 "Mode4_SingleOn9" 35 "Mode4_SingleOn10" 36 "Mode4_SingleOn11" 37 "Mode4_SingleOn12" 38 "Mode4_SingleOff1" 39 "Mode4_SingleOff2" 40 "Mode4_SingleOff3" 41 "Mode4_SingleOff4" 42 "Mode4_SingleOff5" 43 "Mode4_SingleOff6" 44 "Mode4_SingleOff7" 45 "Mode4_SingleOff8" 46 "Mode4_SingleOff9" 47 "Mode4_SingleOff10" 48 "Mode4_SingleOff11" 49 "Mode4_SingleOff12";
VAL_ 823 DwnLoadDynLtgPrmForFrntLeGrp23Mode1 0 "Mode4_Off" 1 "Mode4_On" 2 "Mode4_GradualOn" 3 "Mode4_GradualOff" 4 "Mode4_ForwardWipingOn" 5 "Mode4_BackwardWipingOn" 6 "Mode4_OutwardWipingOn" 7 "Mode4_InwardWipingOn" 8 "Mode4_ForwardWipingOff" 9 "Mode4_BackwardWipingOff" 10 "Mode4_OutwardWipingOff" 11 "Mode4_InwardWipingOff" 12 "Mode4_ForwardScanning" 13 "Mode4_BackwardScanning" 14 "Mode4_BreathOn" 15 "Mode4_BreathOff" 16 "Mode4_1stHalfONand2ndHalfOFF" 17 "Mode4_HalfOFFHalfON" 18 "Mode4_HalfDimmingONHalfOFF" 19 "Mode4_HalfDimmingONHalfON" 20 "Mode4_HalfOFFHalfDimmingON" 21 "Mode4_HalfONHalfDimmingON" 22 "Mode4_HalfDimmingOFFHalfOFF" 23 "Mode4_HalfDimmingOFFHalfON" 24 "Mode4_HalfOFFHalfDimmingOFF" 25 "Mode4_HalfONHalfDimmingOFF" 26 "Mode4_SingleOn1" 27 "Mode4_SingleOn2" 28 "Mode4_SingleOn3" 29 "Mode4_SingleOn4" 30 "Mode4_SingleOn5" 31 "Mode4_SingleOn6" 32 "Mode4_SingleOn7" 33 "Mode4_SingleOn8" 34 "Mode4_SingleOn9" 35 "Mode4_SingleOn10" 36 "Mode4_SingleOn11" 37 "Mode4_SingleOn12" 38 "Mode4_SingleOff1" 39 "Mode4_SingleOff2" 40 "Mode4_SingleOff3" 41 "Mode4_SingleOff4" 42 "Mode4_SingleOff5" 43 "Mode4_SingleOff6" 44 "Mode4_SingleOff7" 45 "Mode4_SingleOff8" 46 "Mode4_SingleOff9" 47 "Mode4_SingleOff10" 48 "Mode4_SingleOff11" 49 "Mode4_SingleOff12";
VAL_ 824 DwnLoadDynLtgPrmForFrntLeGrp24Mode1 0 "Mode4_Off" 1 "Mode4_On" 2 "Mode4_GradualOn" 3 "Mode4_GradualOff" 4 "Mode4_ForwardWipingOn" 5 "Mode4_BackwardWipingOn" 6 "Mode4_OutwardWipingOn" 7 "Mode4_InwardWipingOn" 8 "Mode4_ForwardWipingOff" 9 "Mode4_BackwardWipingOff" 10 "Mode4_OutwardWipingOff" 11 "Mode4_InwardWipingOff" 12 "Mode4_ForwardScanning" 13 "Mode4_BackwardScanning" 14 "Mode4_BreathOn" 15 "Mode4_BreathOff" 16 "Mode4_1stHalfONand2ndHalfOFF" 17 "Mode4_HalfOFFHalfON" 18 "Mode4_HalfDimmingONHalfOFF" 19 "Mode4_HalfDimmingONHalfON" 20 "Mode4_HalfOFFHalfDimmingON" 21 "Mode4_HalfONHalfDimmingON" 22 "Mode4_HalfDimmingOFFHalfOFF" 23 "Mode4_HalfDimmingOFFHalfON" 24 "Mode4_HalfOFFHalfDimmingOFF" 25 "Mode4_HalfONHalfDimmingOFF" 26 "Mode4_SingleOn1" 27 "Mode4_SingleOn2" 28 "Mode4_SingleOn3" 29 "Mode4_SingleOn4" 30 "Mode4_SingleOn5" 31 "Mode4_SingleOn6" 32 "Mode4_SingleOn7" 33 "Mode4_SingleOn8" 34 "Mode4_SingleOn9" 35 "Mode4_SingleOn10" 36 "Mode4_SingleOn11" 37 "Mode4_SingleOn12" 38 "Mode4_SingleOff1" 39 "Mode4_SingleOff2" 40 "Mode4_SingleOff3" 41 "Mode4_SingleOff4" 42 "Mode4_SingleOff5" 43 "Mode4_SingleOff6" 44 "Mode4_SingleOff7" 45 "Mode4_SingleOff8" 46 "Mode4_SingleOff9" 47 "Mode4_SingleOff10" 48 "Mode4_SingleOff11" 49 "Mode4_SingleOff12";
VAL_ 825 DwnLoadDynLtgPrmForFrntRIGrp1Mode1 0 "Mode4_Off" 1 "Mode4_On" 2 "Mode4_GradualOn" 3 "Mode4_GradualOff" 4 "Mode4_ForwardWipingOn" 5 "Mode4_BackwardWipingOn" 6 "Mode4_OutwardWipingOn" 7 "Mode4_InwardWipingOn" 8 "Mode4_ForwardWipingOff" 9 "Mode4_BackwardWipingOff" 10 "Mode4_OutwardWipingOff" 11 "Mode4_InwardWipingOff" 12 "Mode4_ForwardScanning" 13 "Mode4_BackwardScanning" 14 "Mode4_BreathOn" 15 "Mode4_BreathOff" 16 "Mode4_1stHalfONand2ndHalfOFF" 17 "Mode4_HalfOFFHalfON" 18 "Mode4_HalfDimmingONHalfOFF" 19 "Mode4_HalfDimmingONHalfON" 20 "Mode4_HalfOFFHalfDimmingON" 21 "Mode4_HalfONHalfDimmingON" 22 "Mode4_HalfDimmingOFFHalfOFF" 23 "Mode4_HalfDimmingOFFHalfON" 24 "Mode4_HalfOFFHalfDimmingOFF" 25 "Mode4_HalfONHalfDimmingOFF" 26 "Mode4_SingleOn1" 27 "Mode4_SingleOn2" 28 "Mode4_SingleOn3" 29 "Mode4_SingleOn4" 30 "Mode4_SingleOn5" 31 "Mode4_SingleOn6" 32 "Mode4_SingleOn7" 33 "Mode4_SingleOn8" 34 "Mode4_SingleOn9" 35 "Mode4_SingleOn10" 36 "Mode4_SingleOn11" 37 "Mode4_SingleOn12" 38 "Mode4_SingleOff1" 39 "Mode4_SingleOff2" 40 "Mode4_SingleOff3" 41 "Mode4_SingleOff4" 42 "Mode4_SingleOff5" 43 "Mode4_SingleOff6" 44 "Mode4_SingleOff7" 45 "Mode4_SingleOff8" 46 "Mode4_SingleOff9" 47 "Mode4_SingleOff10" 48 "Mode4_SingleOff11" 49 "Mode4_SingleOff12";
VAL_ 826 DwnLoadDynLtgPrmForFrntRIGrp2Mode1 0 "Mode4_Off" 1 "Mode4_On" 2 "Mode4_GradualOn" 3 "Mode4_GradualOff" 4 "Mode4_ForwardWipingOn" 5 "Mode4_BackwardWipingOn" 6 "Mode4_OutwardWipingOn" 7 "Mode4_InwardWipingOn" 8 "Mode4_ForwardWipingOff" 9 "Mode4_BackwardWipingOff" 10 "Mode4_OutwardWipingOff" 11 "Mode4_InwardWipingOff" 12 "Mode4_ForwardScanning" 13 "Mode4_BackwardScanning" 14 "Mode4_BreathOn" 15 "Mode4_BreathOff" 16 "Mode4_1stHalfONand2ndHalfOFF" 17 "Mode4_HalfOFFHalfON" 18 "Mode4_HalfDimmingONHalfOFF" 19 "Mode4_HalfDimmingONHalfON" 20 "Mode4_HalfOFFHalfDimmingON" 21 "Mode4_HalfONHalfDimmingON" 22 "Mode4_HalfDimmingOFFHalfOFF" 23 "Mode4_HalfDimmingOFFHalfON" 24 "Mode4_HalfOFFHalfDimmingOFF" 25 "Mode4_HalfONHalfDimmingOFF" 26 "Mode4_SingleOn1" 27 "Mode4_SingleOn2" 28 "Mode4_SingleOn3" 29 "Mode4_SingleOn4" 30 "Mode4_SingleOn5" 31 "Mode4_SingleOn6" 32 "Mode4_SingleOn7" 33 "Mode4_SingleOn8" 34 "Mode4_SingleOn9" 35 "Mode4_SingleOn10" 36 "Mode4_SingleOn11" 37 "Mode4_SingleOn12" 38 "Mode4_SingleOff1" 39 "Mode4_SingleOff2" 40 "Mode4_SingleOff3" 41 "Mode4_SingleOff4" 42 "Mode4_SingleOff5" 43 "Mode4_SingleOff6" 44 "Mode4_SingleOff7" 45 "Mode4_SingleOff8" 46 "Mode4_SingleOff9" 47 "Mode4_SingleOff10" 48 "Mode4_SingleOff11" 49 "Mode4_SingleOff12";
VAL_ 827 DwnLoadDynLtgPrmForFrntRIGrp3Mode1 0 "Mode4_Off" 1 "Mode4_On" 2 "Mode4_GradualOn" 3 "Mode4_GradualOff" 4 "Mode4_ForwardWipingOn" 5 "Mode4_BackwardWipingOn" 6 "Mode4_OutwardWipingOn" 7 "Mode4_InwardWipingOn" 8 "Mode4_ForwardWipingOff" 9 "Mode4_BackwardWipingOff" 10 "Mode4_OutwardWipingOff" 11 "Mode4_InwardWipingOff" 12 "Mode4_ForwardScanning" 13 "Mode4_BackwardScanning" 14 "Mode4_BreathOn" 15 "Mode4_BreathOff" 16 "Mode4_1stHalfONand2ndHalfOFF" 17 "Mode4_HalfOFFHalfON" 18 "Mode4_HalfDimmingONHalfOFF" 19 "Mode4_HalfDimmingONHalfON" 20 "Mode4_HalfOFFHalfDimmingON" 21 "Mode4_HalfONHalfDimmingON" 22 "Mode4_HalfDimmingOFFHalfOFF" 23 "Mode4_HalfDimmingOFFHalfON" 24 "Mode4_HalfOFFHalfDimmingOFF" 25 "Mode4_HalfONHalfDimmingOFF" 26 "Mode4_SingleOn1" 27 "Mode4_SingleOn2" 28 "Mode4_SingleOn3" 29 "Mode4_SingleOn4" 30 "Mode4_SingleOn5" 31 "Mode4_SingleOn6" 32 "Mode4_SingleOn7" 33 "Mode4_SingleOn8" 34 "Mode4_SingleOn9" 35 "Mode4_SingleOn10" 36 "Mode4_SingleOn11" 37 "Mode4_SingleOn12" 38 "Mode4_SingleOff1" 39 "Mode4_SingleOff2" 40 "Mode4_SingleOff3" 41 "Mode4_SingleOff4" 42 "Mode4_SingleOff5" 43 "Mode4_SingleOff6" 44 "Mode4_SingleOff7" 45 "Mode4_SingleOff8" 46 "Mode4_SingleOff9" 47 "Mode4_SingleOff10" 48 "Mode4_SingleOff11" 49 "Mode4_SingleOff12";
VAL_ 828 DwnLoadDynLtgPrmForFrntRIGrp4Mode1 0 "Mode4_Off" 1 "Mode4_On" 2 "Mode4_GradualOn" 3 "Mode4_GradualOff" 4 "Mode4_ForwardWipingOn" 5 "Mode4_BackwardWipingOn" 6 "Mode4_OutwardWipingOn" 7 "Mode4_InwardWipingOn" 8 "Mode4_ForwardWipingOff" 9 "Mode4_BackwardWipingOff" 10 "Mode4_OutwardWipingOff" 11 "Mode4_InwardWipingOff" 12 "Mode4_ForwardScanning" 13 "Mode4_BackwardScanning" 14 "Mode4_BreathOn" 15 "Mode4_BreathOff" 16 "Mode4_1stHalfONand2ndHalfOFF" 17 "Mode4_HalfOFFHalfON" 18 "Mode4_HalfDimmingONHalfOFF" 19 "Mode4_HalfDimmingONHalfON" 20 "Mode4_HalfOFFHalfDimmingON" 21 "Mode4_HalfONHalfDimmingON" 22 "Mode4_HalfDimmingOFFHalfOFF" 23 "Mode4_HalfDimmingOFFHalfON" 24 "Mode4_HalfOFFHalfDimmingOFF" 25 "Mode4_HalfONHalfDimmingOFF" 26 "Mode4_SingleOn1" 27 "Mode4_SingleOn2" 28 "Mode4_SingleOn3" 29 "Mode4_SingleOn4" 30 "Mode4_SingleOn5" 31 "Mode4_SingleOn6" 32 "Mode4_SingleOn7" 33 "Mode4_SingleOn8" 34 "Mode4_SingleOn9" 35 "Mode4_SingleOn10" 36 "Mode4_SingleOn11" 37 "Mode4_SingleOn12" 38 "Mode4_SingleOff1" 39 "Mode4_SingleOff2" 40 "Mode4_SingleOff3" 41 "Mode4_SingleOff4" 42 "Mode4_SingleOff5" 43 "Mode4_SingleOff6" 44 "Mode4_SingleOff7" 45 "Mode4_SingleOff8" 46 "Mode4_SingleOff9" 47 "Mode4_SingleOff10" 48 "Mode4_SingleOff11" 49 "Mode4_SingleOff12";
VAL_ 829 DwnLoadDynLtgPrmForFrntRIGrp5Mode1 0 "Mode4_Off" 1 "Mode4_On" 2 "Mode4_GradualOn" 3 "Mode4_GradualOff" 4 "Mode4_ForwardWipingOn" 5 "Mode4_BackwardWipingOn" 6 "Mode4_OutwardWipingOn" 7 "Mode4_InwardWipingOn" 8 "Mode4_ForwardWipingOff" 9 "Mode4_BackwardWipingOff" 10 "Mode4_OutwardWipingOff" 11 "Mode4_InwardWipingOff" 12 "Mode4_ForwardScanning" 13 "Mode4_BackwardScanning" 14 "Mode4_BreathOn" 15 "Mode4_BreathOff" 16 "Mode4_1stHalfONand2ndHalfOFF" 17 "Mode4_HalfOFFHalfON" 18 "Mode4_HalfDimmingONHalfOFF" 19 "Mode4_HalfDimmingONHalfON" 20 "Mode4_HalfOFFHalfDimmingON" 21 "Mode4_HalfONHalfDimmingON" 22 "Mode4_HalfDimmingOFFHalfOFF" 23 "Mode4_HalfDimmingOFFHalfON" 24 "Mode4_HalfOFFHalfDimmingOFF" 25 "Mode4_HalfONHalfDimmingOFF" 26 "Mode4_SingleOn1" 27 "Mode4_SingleOn2" 28 "Mode4_SingleOn3" 29 "Mode4_SingleOn4" 30 "Mode4_SingleOn5" 31 "Mode4_SingleOn6" 32 "Mode4_SingleOn7" 33 "Mode4_SingleOn8" 34 "Mode4_SingleOn9" 35 "Mode4_SingleOn10" 36 "Mode4_SingleOn11" 37 "Mode4_SingleOn12" 38 "Mode4_SingleOff1" 39 "Mode4_SingleOff2" 40 "Mode4_SingleOff3" 41 "Mode4_SingleOff4" 42 "Mode4_SingleOff5" 43 "Mode4_SingleOff6" 44 "Mode4_SingleOff7" 45 "Mode4_SingleOff8" 46 "Mode4_SingleOff9" 47 "Mode4_SingleOff10" 48 "Mode4_SingleOff11" 49 "Mode4_SingleOff12";
VAL_ 830 DwnLoadDynLtgPrmForFrntRIGrp6Mode1 0 "Mode4_Off" 1 "Mode4_On" 2 "Mode4_GradualOn" 3 "Mode4_GradualOff" 4 "Mode4_ForwardWipingOn" 5 "Mode4_BackwardWipingOn" 6 "Mode4_OutwardWipingOn" 7 "Mode4_InwardWipingOn" 8 "Mode4_ForwardWipingOff" 9 "Mode4_BackwardWipingOff" 10 "Mode4_OutwardWipingOff" 11 "Mode4_InwardWipingOff" 12 "Mode4_ForwardScanning" 13 "Mode4_BackwardScanning" 14 "Mode4_BreathOn" 15 "Mode4_BreathOff" 16 "Mode4_1stHalfONand2ndHalfOFF" 17 "Mode4_HalfOFFHalfON" 18 "Mode4_HalfDimmingONHalfOFF" 19 "Mode4_HalfDimmingONHalfON" 20 "Mode4_HalfOFFHalfDimmingON" 21 "Mode4_HalfONHalfDimmingON" 22 "Mode4_HalfDimmingOFFHalfOFF" 23 "Mode4_HalfDimmingOFFHalfON" 24 "Mode4_HalfOFFHalfDimmingOFF" 25 "Mode4_HalfONHalfDimmingOFF" 26 "Mode4_SingleOn1" 27 "Mode4_SingleOn2" 28 "Mode4_SingleOn3" 29 "Mode4_SingleOn4" 30 "Mode4_SingleOn5" 31 "Mode4_SingleOn6" 32 "Mode4_SingleOn7" 33 "Mode4_SingleOn8" 34 "Mode4_SingleOn9" 35 "Mode4_SingleOn10" 36 "Mode4_SingleOn11" 37 "Mode4_SingleOn12" 38 "Mode4_SingleOff1" 39 "Mode4_SingleOff2" 40 "Mode4_SingleOff3" 41 "Mode4_SingleOff4" 42 "Mode4_SingleOff5" 43 "Mode4_SingleOff6" 44 "Mode4_SingleOff7" 45 "Mode4_SingleOff8" 46 "Mode4_SingleOff9" 47 "Mode4_SingleOff10" 48 "Mode4_SingleOff11" 49 "Mode4_SingleOff12";
VAL_ 831 DwnLoadDynLtgPrmForFrntRIGrp7Mode1 0 "Mode4_Off" 1 "Mode4_On" 2 "Mode4_GradualOn" 3 "Mode4_GradualOff" 4 "Mode4_ForwardWipingOn" 5 "Mode4_BackwardWipingOn" 6 "Mode4_OutwardWipingOn" 7 "Mode4_InwardWipingOn" 8 "Mode4_ForwardWipingOff" 9 "Mode4_BackwardWipingOff" 10 "Mode4_OutwardWipingOff" 11 "Mode4_InwardWipingOff" 12 "Mode4_ForwardScanning" 13 "Mode4_BackwardScanning" 14 "Mode4_BreathOn" 15 "Mode4_BreathOff" 16 "Mode4_1stHalfONand2ndHalfOFF" 17 "Mode4_HalfOFFHalfON" 18 "Mode4_HalfDimmingONHalfOFF" 19 "Mode4_HalfDimmingONHalfON" 20 "Mode4_HalfOFFHalfDimmingON" 21 "Mode4_HalfONHalfDimmingON" 22 "Mode4_HalfDimmingOFFHalfOFF" 23 "Mode4_HalfDimmingOFFHalfON" 24 "Mode4_HalfOFFHalfDimmingOFF" 25 "Mode4_HalfONHalfDimmingOFF" 26 "Mode4_SingleOn1" 27 "Mode4_SingleOn2" 28 "Mode4_SingleOn3" 29 "Mode4_SingleOn4" 30 "Mode4_SingleOn5" 31 "Mode4_SingleOn6" 32 "Mode4_SingleOn7" 33 "Mode4_SingleOn8" 34 "Mode4_SingleOn9" 35 "Mode4_SingleOn10" 36 "Mode4_SingleOn11" 37 "Mode4_SingleOn12" 38 "Mode4_SingleOff1" 39 "Mode4_SingleOff2" 40 "Mode4_SingleOff3" 41 "Mode4_SingleOff4" 42 "Mode4_SingleOff5" 43 "Mode4_SingleOff6" 44 "Mode4_SingleOff7" 45 "Mode4_SingleOff8" 46 "Mode4_SingleOff9" 47 "Mode4_SingleOff10" 48 "Mode4_SingleOff11" 49 "Mode4_SingleOff12";
VAL_ 832 DwnLoadDynLtgPrmForFrntRIGrp8Mode1 0 "Mode4_Off" 1 "Mode4_On" 2 "Mode4_GradualOn" 3 "Mode4_GradualOff" 4 "Mode4_ForwardWipingOn" 5 "Mode4_BackwardWipingOn" 6 "Mode4_OutwardWipingOn" 7 "Mode4_InwardWipingOn" 8 "Mode4_ForwardWipingOff" 9 "Mode4_BackwardWipingOff" 10 "Mode4_OutwardWipingOff" 11 "Mode4_InwardWipingOff" 12 "Mode4_ForwardScanning" 13 "Mode4_BackwardScanning" 14 "Mode4_BreathOn" 15 "Mode4_BreathOff" 16 "Mode4_1stHalfONand2ndHalfOFF" 17 "Mode4_HalfOFFHalfON" 18 "Mode4_HalfDimmingONHalfOFF" 19 "Mode4_HalfDimmingONHalfON" 20 "Mode4_HalfOFFHalfDimmingON" 21 "Mode4_HalfONHalfDimmingON" 22 "Mode4_HalfDimmingOFFHalfOFF" 23 "Mode4_HalfDimmingOFFHalfON" 24 "Mode4_HalfOFFHalfDimmingOFF" 25 "Mode4_HalfONHalfDimmingOFF" 26 "Mode4_SingleOn1" 27 "Mode4_SingleOn2" 28 "Mode4_SingleOn3" 29 "Mode4_SingleOn4" 30 "Mode4_SingleOn5" 31 "Mode4_SingleOn6" 32 "Mode4_SingleOn7" 33 "Mode4_SingleOn8" 34 "Mode4_SingleOn9" 35 "Mode4_SingleOn10" 36 "Mode4_SingleOn11" 37 "Mode4_SingleOn12" 38 "Mode4_SingleOff1" 39 "Mode4_SingleOff2" 40 "Mode4_SingleOff3" 41 "Mode4_SingleOff4" 42 "Mode4_SingleOff5" 43 "Mode4_SingleOff6" 44 "Mode4_SingleOff7" 45 "Mode4_SingleOff8" 46 "Mode4_SingleOff9" 47 "Mode4_SingleOff10" 48 "Mode4_SingleOff11" 49 "Mode4_SingleOff12";
VAL_ 833 DwnLoadDynLtgPrmForFrntRIGrp9Mode1 0 "Mode4_Off" 1 "Mode4_On" 2 "Mode4_GradualOn" 3 "Mode4_GradualOff" 4 "Mode4_ForwardWipingOn" 5 "Mode4_BackwardWipingOn" 6 "Mode4_OutwardWipingOn" 7 "Mode4_InwardWipingOn" 8 "Mode4_ForwardWipingOff" 9 "Mode4_BackwardWipingOff" 10 "Mode4_OutwardWipingOff" 11 "Mode4_InwardWipingOff" 12 "Mode4_ForwardScanning" 13 "Mode4_BackwardScanning" 14 "Mode4_BreathOn" 15 "Mode4_BreathOff" 16 "Mode4_1stHalfONand2ndHalfOFF" 17 "Mode4_HalfOFFHalfON" 18 "Mode4_HalfDimmingONHalfOFF" 19 "Mode4_HalfDimmingONHalfON" 20 "Mode4_HalfOFFHalfDimmingON" 21 "Mode4_HalfONHalfDimmingON" 22 "Mode4_HalfDimmingOFFHalfOFF" 23 "Mode4_HalfDimmingOFFHalfON" 24 "Mode4_HalfOFFHalfDimmingOFF" 25 "Mode4_HalfONHalfDimmingOFF" 26 "Mode4_SingleOn1" 27 "Mode4_SingleOn2" 28 "Mode4_SingleOn3" 29 "Mode4_SingleOn4" 30 "Mode4_SingleOn5" 31 "Mode4_SingleOn6" 32 "Mode4_SingleOn7" 33 "Mode4_SingleOn8" 34 "Mode4_SingleOn9" 35 "Mode4_SingleOn10" 36 "Mode4_SingleOn11" 37 "Mode4_SingleOn12" 38 "Mode4_SingleOff1" 39 "Mode4_SingleOff2" 40 "Mode4_SingleOff3" 41 "Mode4_SingleOff4" 42 "Mode4_SingleOff5" 43 "Mode4_SingleOff6" 44 "Mode4_SingleOff7" 45 "Mode4_SingleOff8" 46 "Mode4_SingleOff9" 47 "Mode4_SingleOff10" 48 "Mode4_SingleOff11" 49 "Mode4_SingleOff12";
VAL_ 272 SphDvExtnLg 0 "NoResponse" 1 "Updateprocessing" 2 "Updatesucess" 3 "Updatefail_NoSDcard" 4 "Updatefail_NoFile" 5 "Updatefail_Fileerror" 6 "Updatefail_otherreason" 7 "Reserved";
VAL_ 1282 WakeUpReasonsforZCUDM 0 "WakeupReasons_0" 1 "WakeupReasons_667950" 2 "WakeupReasons_169654" 3 "WakeupReasons_667951" 4 "WakeupReasons_168965" 5 "WakeupReasons_197643" 6 "WakeupReasons_264933" 7 "WakeupReasons_45654" 8 "WakeupReasons_22058" 9 "WakeupReasons_49446" 10 "WakeupReasons_22060" 11 "WakeupReasons_269740" 12 "WakeupReasons_269735" 13 "WakeupReasons_269739" 14 "WakeupReasons_658500" 15 "WakeupReasons_21901" 16 "WakeupReasons_45793" 17 "WakeupReasons_45794" 18 "WakeupReasons_22005" 19 "WakeupReasons_22013" 20 "WakeupReasons_22100" 21 "WakeupReasons_45659" 22 "WakeupReasons_45657" 23 "WakeupReasons_140084" 24 "WakeupReasons_21973" 25 "WakeupReasons_91253" 26 "WakeupReasons_88123" 27 "WakeupReasons_88125" 28 "WakeupReasons_321583" 29 "WakeupReasons_74188" 30 "WakeupReasons_667945" 31 "WakeupReasons_169655" 32 "WakeupReasons_667948" 33 "WakeupReasons_168966" 34 "WakeupReasons_170865" 35 "WakeupReasons_197642" 36 "WakeupReasons_264876" 37 "WakeupReasons_191050" 38 "WakeupReasons_182033" 39 "WakeupReasons_200937" 40 "WakeupReasons_170807" 41 "WakeupReasons_319139" 42 "WakeupReasons_100298" 43 "WakeupReasons_100275" 44 "WakeupReasons_100300" 45 "WakeupReasons_100278" 46 "WakeupReasons_100281" 47 "WakeupReasons_265333" 48 "WakeupReasons_108776" 49 "WakeupReasons_176921" 50 "WakeupReasons_197826" 51 "WakeupReasons_185670" 52 "WakeupReasons_161066" 53 "WakeupReasons_200156" 54 "WakeupReasons_225696" 55 "WakeupReasons_21997" 56 "WakeupReasons_45656" 57 "WakeupReasons_266860" 58 "WakeupReasons_169894" 59 "WakeupReasons_320282" 60 "WakeupReasons_319422" 61 "WakeupReasons_320277" 62 "WakeupReasons_355601" 63 "WakeupReasons_360904" 64 "WakeupReasons_361505" 65 "WakeupReasons_361509" 66 "WakeupReasons_645094" 67 "WakeupReasons_68676" 68 "WakeupReasons_360008" 69 "WakeupReasons_109382" 70 "WakeupReasons_119273" 71 "WakeupReasons_224065" 72 "WakeupReasons_68644" 73 "WakeupReasons_109364" 74 "WakeupReasons_68481" 75 "WakeupReasons_224061" 76 "WakeupReasons_360006" 77 "WakeupReasons_138997" 78 "WakeupReasons_634696" 79 "WakeupReasons_645810" 80 "WakeupReasons_297868" 81 "WakeupReasons_315364" 82 "WakeupReasons_109367" 83 "WakeupReasons_320126" 84 "WakeupReasons_109387" 85 "WakeupReasons_634710" 86 "WakeupReasons_338820" 87 "WakeupReasons_67182" 88 "WakeupReasons_152237" 89 "WakeupReasons_145707" 90 "WakeupReasons_199172" 91 "WakeupReasons_144897" 92 "WakeupReasons_186489" 93 "WakeupReasons_144970" 94 "WakeupReasons_152786" 95 "WakeupReasons_264932" 96 "WakeupReasons_264934" 97 "WakeupReasons_356190" 98 "WakeupReasons_145688" 99 "WakeupReasons_95444" 100 "WakeupReasons_169945" 101 "WakeupReasons_140678" 102 "WakeupReasons_222553" 103 "WakeupReasons_224831" 104 "WakeupReasons_201815" 105 "WakeupReasons_45864" 106 "WakeupReasons_659549" 107 "WakeupReasons_45866" 108 "WakeupReasons_45867" 109 "WakeupReasons_169884" 110 "WakeupReasons_264962" 111 "WakeupReasons_201348" 112 "WakeupReasons_320287" 113 "WakeupReasons_156412" 114 "WakeupReasons_133749" 115 "WakeupReasons_355409" 116 "WakeupReasons_636692" 117 "WakeupReasons_533044" 118 "WakeupReasons_106774" 119 "WakeupReasons_145311" 120 "WakeupReasons_145319" 121 "WakeupReasons_152774" 122 "WakeupReasons_145330" 123 "WakeupReasons_145388" 124 "WakeupReasons_145399" 125 "WakeupReasons_145362" 126 "WakeupReasons_145385" 127 "WakeupReasons_145373" 128 "WakeupReasons_145288" 129 "WakeupReasons_145419" 130 "WakeupReasons_145454" 131 "WakeupReasons_145462" 132 "WakeupReasons_269156" 133 "WakeupReasons_300427" 134 "WakeupReasons_220322" 135 "WakeupReasons_224617" 136 "WakeupReasons_224634" 137 "WakeupReasons_300682" 138 "WakeupReasons_264958" 139 "WakeupReasons_160597" 140 "WakeupReasons_160602" 141 "WakeupReasons_108841" 142 "WakeupReasons_265569" 143 "WakeupReasons_526429" 144 "WakeupReasons_514545" 145 "WakeupReasons_265232" 146 "WakeupReasons_644550" 147 "WakeupReasons_317616" 148 "WakeupReasons_354791" 149 "WakeupReasons_320631" 150 "WakeupReasons_337565" 151 "WakeupReasons_532007" 152 "WakeupReasons_514503" 153 "WakeupReasons_299117" 154 "WakeupReasons_340667" 155 "WakeupReasons_321845" 156 "WakeupReasons_179103" 157 "WakeupReasons_108810" 158 "WakeupReasons_322857" 159 "WakeupReasons_658603" 160 "WakeupReasons_197648" 161 "WakeupReasons_160596" 162 "WakeupReasons_361272" 163 "WakeupReasons_361279" 164 "WakeupReasons_265305" 165 "WakeupReasons_265328" 166 "WakeupReasons_265330" 167 "WakeupReasons_298808" 168 "WakeupReasons_515804" 169 "WakeupReasons_514502" 170 "WakeupReasons_645753" 171 "WakeupReasons_646109" 172 "WakeupReasons_299547" 173 "WakeupReasons_318342" 174 "WakeupReasons_360543" 175 "WakeupReasons_356549" 176 "WakeupReasons_198484" 177 "WakeupReasons_300681" 178 "WakeupReasons_359211" 179 "WakeupReasons_534077" 180 "WakeupReasons_525705" 181 "WakeupReasons_360299" 182 "WakeupReasons_526445" 183 "WakeupReasons_534145" 184 "WakeupReasons_192030" 185 "WakeupReasons_652361" 186 "WakeupReasons_355214" 187 "WakeupReasons_321317" 188 "WakeupReasons_359187" 189 "WakeupReasons_321057" 190 "WakeupReasons_321319" 191 "WakeupReasons_321323" 192 "WakeupReasons_321077" 193 "WakeupReasons_320895" 194 "WakeupReasons_655340" 195 "WakeupReasons_636556" 196 "WakeupReasons_108834" 197 "WakeupReasons_265937" 198 "WakeupReasons_533050" 199 "WakeupReasons_526426" 200 "WakeupReasons_264712" 201 "WakeupReasons_319401" 202 "WakeupReasons_643973" 203 "WakeupReasons_223715" 204 "WakeupReasons_199159" 205 "WakeupReasons_318382" 206 "WakeupReasons_226967" 207 "WakeupReasons_531743" 208 "WakeupReasons_360542" 209 "WakeupReasons_264726" 210 "WakeupReasons_535214" 211 "WakeupReasons_335068" 212 "WakeupReasons_316796" 213 "WakeupReasons_526438" 214 "WakeupReasons_198433" 215 "WakeupReasons_225961" 216 "WakeupReasons_197665" 217 "WakeupReasons_224550" 218 "WakeupReasons_667962" 219 "WakeupReasons_667953" 220 "WakeupReasons_110885" 221 "WakeupReasons_224552" 222 "WakeupReasons_224553" 223 "WakeupReasons_652546" 224 "WakeupReasons_331194" 225 "WakeupReasons_667820" 226 "WakeupReasons_659350" 227 "WakeupReasons_101706" 228 "WakeupReasons_101725" 229 "WakeupReasons_101728" 230 "WakeupReasons_101727" 231 "WakeupReasons_166267" 232 "WakeupReasons_156440" 233 "WakeupReasons_95949" 234 "WakeupReasons_112799" 235 "WakeupReasons_146470" 236 "WakeupReasons_176748" 237 "WakeupReasons_223920" 238 "WakeupReasons_668531" 239 "WakeupReasons_670087" 240 "WakeupReasons_668529" 241 "WakeupReasons_45858" 242 "WakeupReasons_315981" 243 "WakeupReasons_533370" 244 "WakeupReasons_533371" 245 "WakeupReasons_533372" 246 "WakeupReasons_241902" 247 "WakeupReasons_359559" 248 "WakeupReasons_516327" 249 "WakeupReasons_533872" 250 "WakeupReasons_45856" 251 "WakeupReasons_45853" 252 "WakeupReasons_45854" 253 "WakeupReasons_45852" 254 "WakeupReasons_45851" 255 "WakeupReasons_45850" 256 "WakeupReasons_45849" 257 "WakeupReasons_636801" 258 "WakeupReasons_109466" 259 "WakeupReasons_109467" 260 "WakeupReasons_670345" 261 "WakeupReasons_NMPDUReceived" 262 "WakeupReasons_358832" 263 "WakeupReasons_200683" 264 "WakeupReasons_198452" 265 "WakeupReasons_185457" 266 "WakeupReasons_185490" 267 "WakeupReasons_4471" 268 "WakeupReasons_269034" 269 "WakeupReasons_215560" 270 "WakeupReasons_312881" 271 "WakeupReasons_269140" 272 "WakeupReasons_197653" 273 "WakeupReasons_337991" 274 "WakeupReasons_658188" 275 "WakeupReasons_674953" 276 "WakeupReasons_675064" 277 "WakeupReasons_674958" 278 "WakeupReasons_675494" 279 "WakeupReasons_675837" 280 "WakeupReasons_667879" 281 "WakeupReasons_667947" 282 "WakeupReasons_676265" 283 "WakeupReasons_669465" 284 "WakeupReasons_670928" 285 "WakeupReasons_669447" 286 "WakeupReasons_667922" 287 "WakeupReasons_670753" 288 "WakeupReasons_668395" 289 "WakeupReasons_668393" 290 "WakeupReasons_667850" 291 "WakeupReasons_667848" 292 "WakeupReasons_311279" 293 "WakeupReasons_182918" 294 "WakeupReasons_667988" 295 "WakeupReasons_532555" 296 "WakeupReasons_532556" 297 "WakeupReasons_113348" 298 "WakeupReasons_193474" 299 "WakeupReasons_667871" 300 "WakeupReasons_670966" 301 "WakeupReasons_667985" 302 "WakeupReasons_670354" 303 "WakeupReasons_46017" 304 "WakeupReasons_675742" 305 "WakeupReasons_106669" 306 "WakeupReasons_80609" 307 "WakeupReasons_199714" 308 "WakeupReasons_200090" 309 "WakeupReasons_139075" 310 "WakeupReasons_268983" 311 "WakeupReasons_265131" 312 "WakeupReasons_263473" 313 "WakeupReasons_45887" 314 "WakeupReasons_69678" 315 "WakeupReasons_69679" 316 "WakeupReasons_45897" 317 "WakeupReasons_45898" 318 "WakeupReasons_80608" 319 "WakeupReasons_45869" 320 "WakeupReasons_45870" 321 "WakeupReasons_45872" 322 "WakeupReasons_45875" 323 "WakeupReasons_45871" 324 "WakeupReasons_45876" 325 "WakeupReasons_667980" 326 "WakeupReasons_45877" 327 "WakeupReasons_667973" 328 "WakeupReasons_670962" 329 "WakeupReasons_45888" 330 "WakeupReasons_45890" 331 "WakeupReasons_667869" 332 "WakeupReasons_45846" 333 "WakeupReasons_45847" 334 "WakeupReasons_45848" 335 "WakeupReasons_262872" 336 "WakeupReasons_127924" 337 "WakeupReasons_127926" 338 "WakeupReasons_674223" 339 "WakeupReasons_667982" 340 "WakeupReasons_657121" 341 "WakeupReasons_265745" 342 "WakeupReasons_657120" 343 "WakeupReasons_675564" 344 "WakeupReasons_197644" 345 "WakeupReasons_264943" 346 "WakeupReasons_264697" 347 "WakeupReasons_69216" 348 "WakeupReasons_128671" 349 "WakeupReasons_356598" 350 "WakeupReasons_675745" 351 "WakeupReasons_667983" 352 "WakeupReasons_667987" 353 "WakeupReasons_75103" 354 "WakeupReasons_305818" 355 "WakeupReasons_670942" 356 "WakeupReasons_532932" 357 "WakeupReasons_532933" 358 "WakeupReasons_83199" 359 "WakeupReasons_45900" 360 "WakeupReasons_88458" 361 "WakeupReasons_329457" 362 "WakeupReasons_45902" 363 "WakeupReasons_224211" 364 "WakeupReasons_667981" 365 "WakeupReasons_667874" 366 "WakeupReasons_46020" 367 "WakeupReasons_667842" 368 "WakeupReasons_145161" 369 "WakeupReasons_233755" 370 "WakeupReasons_297056" 371 "WakeupReasons_264691" 372 "WakeupReasons_262871" 373 "WakeupReasons_264964" 374 "WakeupReasons_667872" 375 "WakeupReasons_45655" 376 "WakeupReasons_177214" 377 "WakeupReasons_671005" 378 "WakeupReasons_680712" 379 "WakeupReasons_669822" 380 "WakeupReasons_668523" 381 "WakeupReasons_680974" 382 "WakeupReasons_680975" 383 "WakeupReasons_681028" 384 "WakeupReasons_670462" 385 "WakeupReasons_681134" 386 "WakeupReasons_681031" 387 "WakeupReasons_681711" 388 "WakeupReasons_682034" 389 "WakeupReasons_674839" 390 "WakeupReasons_681915" 391 "WakeupReasons_682032" 392 "WakeupReasons_682037" 393 "WakeupReasons_682688" 394 "WakeupReasons_681789" 395 "WakeupReasons_682023" 396 "WakeupReasons_681023" 397 "WakeupReasons_676285" 398 "WakeupReasons_682077" 399 "WakeupReasons_682076" 400 "WakeupReasons_682078" 401 "WakeupReasons_682153" 402 "WakeupReasons_682155" 403 "WakeupReasons_682152" 404 "WakeupReasons_682154" 405 "WakeupReasons_682074" 406 "WakeupReasons_680763" 407 "WakeupReasons_683934" 408 "WakeupReasons_265678" 409 "WakeupReasons_170285" 410 "WakeupReasons_200637" 411 "WakeupReasons_346654" 412 "WakeupReasons_91254" 413 "WakeupReasons_692021" 414 "WakeupReasons_690385" 415 "WakeupReasons_170290" 416 "WakeupReasons_357498" 417 "WakeupReasons_360491" 418 "WakeupReasons_265699" 419 "WakeupReasons_265698" 420 "WakeupReasons_641482" 421 "WakeupReasons_641483" 422 "WakeupReasons_168968" 423 "WakeupReasons_354674" 424 "WakeupReasons_168967" 425 "WakeupReasons_354672" 426 "WakeupReasons_112027" 427 "WakeupReasons_112035" 428 "WakeupReasons_692020" 429 "WakeupReasons_226565" 430 "WakeupReasons_675594" 431 "WakeupReasons_226571" 432 "WakeupReasons_690593" 433 "WakeupReasons_692022" 434 "WakeupReasons_354809" 435 "WakeupReasons_690939" 436 "WakeupReasons_677781" 437 "WakeupReasons_110173" 438 "WakeupReasons_112031" 439 "WakeupReasons_45896" 440 "WakeupReasons_226569" 441 "WakeupReasons_110181" 442 "WakeupReasons_654489" 443 "WakeupReasons_226570" 444 "WakeupReasons_351189" 445 "WakeupReasons_644275" 446 "WakeupReasons_45895" 447 "WakeupReasons_680765" 448 "WakeupReasons_354831" 449 "WakeupReasons_692439" 450 "WakeupReasons_265694" 451 "WakeupReasons_273516" 452 "WakeupReasons_299120" 453 "WakeupReasons_299531" 454 "WakeupReasons_299532" 455 "WakeupReasons_300690" 456 "WakeupReasons_112024" 457 "WakeupReasons_514651" 458 "WakeupReasons_514652" 459 "WakeupReasons_667188" 460 "WakeupReasons_533849" 461 "WakeupReasons_533850" 462 "WakeupReasons_692019" 463 "WakeupReasons_512384" 464 "WakeupReasons_680764" 465 "WakeupReasons_686281" 466 "WakeupReasons_667949" 467 "WakeupReasons_693005" 468 "WakeupReasons_693024" 469 "WakeupReasons_693914" 470 "WakeupReasons_692547" 471 "WakeupReasons_691991" 472 "WakeupReasons_698488" 473 "WakeupReasons_637992" 474 "WakeupReasons_702197" 475 "WakeupReasons_700425" 476 "WakeupReasons_700485" 477 "WakeupReasons_691993" 478 "WakeupReasons_698660" 479 "WakeupReasons_698288" 480 "WakeupReasons_681813" 481 "WakeupReasons_687404" 482 "WakeupReasons_700467" 483 "WakeupReasons_533750" 484 "WakeupReasons_698409" 485 "WakeupReasons_700686" 486 "WakeupReasons_700687" 487 "WakeupReasons_296931" 488 "WakeupReasons_697145" 489 "WakeupReasons_702174" 490 "WakeupReasons_194966" 491 "WakeupReasons_217907" 492 "WakeupReasons_700484" 493 "WakeupReasons_701508" 494 "WakeupReasons_701509" 495 "WakeupReasons_700215" 496 "WakeupReasons_700603" 497 "WakeupReasons_702204" 498 "WakeupReasons_700483" 499 "WakeupReasons_691994" 500 "WakeupReasons_696612" 501 "WakeupReasons_702088" 502 "WakeupReasons_696850" 503 "WakeupReasons_698129" 504 "WakeupReasons_691992" 505 "WakeupReasons_700554" 506 "WakeupReasons_683263" 507 "WakeupReasons_336435" 508 "WakeupReasons_644379" 509 "WakeupReasons_700684" 510 "WakeupReasons_697967" 511 "WakeupReasons_699922" 512 "WakeupReasons_698385" 513 "WakeupReasons_700692" 514 "WakeupReasons_696971" 515 "WakeupReasons_700782" 516 "WakeupReasons_700486" 517 "WakeupReasons_699919" 518 "WakeupReasons_699921" 519 "WakeupReasons_700130" 520 "WakeupReasons_698130" 521 "WakeupReasons_698581" 522 "WakeupReasons_533751" 523 "WakeupReasons_701270" 524 "WakeupReasons_702240" 525 "WakeupReasons_699114" 526 "WakeupReasons_701872" 527 "WakeupReasons_702448" 528 "WakeupReasons_702439" 529 "WakeupReasons_702402" 530 "WakeupReasons_700565" 531 "WakeupReasons_702452" 532 "WakeupReasons_698631" 533 "WakeupReasons_700530" 534 "WakeupReason_713752" 535 "WakeupReason_702478" 536 "WakeupReason_714675" 537 "WakeupReason_713786" 538 "WakeupReason_716243" 539 "WakeupReason_710922" 540 "WakeupReason_714030" 541 "WakeupReason_715842" 542 "WakeupReason_714678" 543 "WakeupReason_714679" 544 "WakeupReason_710807" 545 "WakeupReason_713568" 546 "WakeupReason_706194" 547 "WakeupReason_713799" 548 "WakeupReason_714172" 549 "WakeupReason_714265" 550 "WakeupReason_715529" 551 "WakeupReason_708964" 552 "WakeupReason_710893" 553 "WakeupReason_709196" 554 "WakeupReason_714806" 555 "WakeupReason_714799" 556 "WakeupReason_714697" 557 "WakeupReason_717832" 558 "WakeupReason_838116" 559 "WakeupReason_839473" 560 "WakeupReason_839705" 561 "WakeupReason_837833" 562 "WakeupReason_703140" 563 "WakeupReason_837962" 564 "WakeupReason_702903" 565 "WakeupReason_837760" 566 "WakeupReason_839458" 576 "WakeupReason_840035" 577 "WakeupReason_714677" 578 "WakeupReason_839181" 579 "WakeupReason_839787" 580 "WakeupReason_841275" 581 "WakeupReason_320145" 582 "WakeupReason_322113" 583 "WakeupReason_298032" 584 "WakeupReason_675452" 585 "WakeupReason_675489" 586 "WakeupReason_846372" 587 "WakeupReason_842273" 588 "WakeupReason_845930" 589 "WakeupReason_846002" 590 "WakeupReason_361441" 591 "WakeupReason_361474" 592 "WakeupReason_362462" 593 "WakeupReason_645735" 594 "WakeupReason_667533" 595 "WakeupReason_702420" 596 "WakeupReason_851482" 597 "WakeupReason_851743" 598 "WakeupReason_852010" 599 "WakeupReason_852050" 600 "WakeupReason_852180" 601 "WakeupReason_852184" 602 "WakeupReason_852194" 603 "WakeupReason_852195" 604 "WakeupReason_852200" 605 "WakeupReason_852215" 606 "WakeupReason_852218" 607 "WakeupReason_852219" 608 "WakeupReason_852248" 609 "WakeupReason_852273" 610 "WakeupReason_852298" 611 "WakeupReason_852385" 612 "WakeupReason_852388" 613 "WakeupReason_852537" 614 "WakeupReason_852646" 615 "WakeupReason_852944" 616 "WakeupReason_852947";
SIG_GROUP_ 810 DwnLoadDynLtgPrmForFrntLeGrp10 1 : DwnLoadDynLtgPrmForFrntLeGrp10ContinueTime DwnLoadDynLtgPrmForFrntLeGrp10HighBrightness DwnLoadDynLtgPrmForFrntLeGrp10LowBrightness DwnLoadDynLtgPrmForFrntLeGrp10Mode1 DwnLoadDynLtgPrmForFrntLeGrp10OffsetTime DwnLoadDynLtgPrmForFrntLeGrp10Timestamp;
SIG_GROUP_ 811 DwnLoadDynLtgPrmForFrntLeGrp11 1 : DwnLoadDynLtgPrmForFrntLeGrp11ContinueTime DwnLoadDynLtgPrmForFrntLeGrp11HighBrightness DwnLoadDynLtgPrmForFrntLeGrp11LowBrightness DwnLoadDynLtgPrmForFrntLeGrp11Mode1 DwnLoadDynLtgPrmForFrntLeGrp11OffsetTime DwnLoadDynLtgPrmForFrntLeGrp11Timestamp;
SIG_GROUP_ 812 DwnLoadDynLtgPrmForFrntLeGrp12 1 : DwnLoadDynLtgPrmForFrntLeGrp12ContinueTime DwnLoadDynLtgPrmForFrntLeGrp12HighBrightness DwnLoadDynLtgPrmForFrntLeGrp12LowBrightness DwnLoadDynLtgPrmForFrntLeGrp12Mode1 DwnLoadDynLtgPrmForFrntLeGrp12OffsetTime DwnLoadDynLtgPrmForFrntLeGrp12Timestamp;
SIG_GROUP_ 813 DwnLoadDynLtgPrmForFrntLeGrp13 1 : DwnLoadDynLtgPrmForFrntLeGrp13ContinueTime DwnLoadDynLtgPrmForFrntLeGrp13HighBrightness DwnLoadDynLtgPrmForFrntLeGrp13LowBrightness DwnLoadDynLtgPrmForFrntLeGrp13Mode1 DwnLoadDynLtgPrmForFrntLeGrp13OffsetTime DwnLoadDynLtgPrmForFrntLeGrp13Timestamp;
SIG_GROUP_ 814 DwnLoadDynLtgPrmForFrntLeGrp14 1 : DwnLoadDynLtgPrmForFrntLeGrp14ContinueTime DwnLoadDynLtgPrmForFrntLeGrp14HighBrightness DwnLoadDynLtgPrmForFrntLeGrp14LowBrightness DwnLoadDynLtgPrmForFrntLeGrp14Mode1 DwnLoadDynLtgPrmForFrntLeGrp14OffsetTime DwnLoadDynLtgPrmForFrntLeGrp14Timestamp;
SIG_GROUP_ 815 DwnLoadDynLtgPrmForFrntLeGrp15 1 : DwnLoadDynLtgPrmForFrntLeGrp15ContinueTime DwnLoadDynLtgPrmForFrntLeGrp15HighBrightness DwnLoadDynLtgPrmForFrntLeGrp15LowBrightness DwnLoadDynLtgPrmForFrntLeGrp15Mode1 DwnLoadDynLtgPrmForFrntLeGrp15OffsetTime DwnLoadDynLtgPrmForFrntLeGrp15Timestamp;
SIG_GROUP_ 816 DwnLoadDynLtgPrmForFrntLeGrp16 1 : DwnLoadDynLtgPrmForFrntLeGrp16ContinueTime DwnLoadDynLtgPrmForFrntLeGrp16HighBrightness DwnLoadDynLtgPrmForFrntLeGrp16LowBrightness DwnLoadDynLtgPrmForFrntLeGrp16Mode1 DwnLoadDynLtgPrmForFrntLeGrp16OffsetTime DwnLoadDynLtgPrmForFrntLeGrp16Timestamp;
SIG_GROUP_ 817 DwnLoadDynLtgPrmForFrntLeGrp17 1 : DwnLoadDynLtgPrmForFrntLeGrp17ContinueTime DwnLoadDynLtgPrmForFrntLeGrp17HighBrightness DwnLoadDynLtgPrmForFrntLeGrp17LowBrightness DwnLoadDynLtgPrmForFrntLeGrp17Mode1 DwnLoadDynLtgPrmForFrntLeGrp17OffsetTime DwnLoadDynLtgPrmForFrntLeGrp17Timestamp;
SIG_GROUP_ 818 DwnLoadDynLtgPrmForFrntLeGrp18 1 : DwnLoadDynLtgPrmForFrntLeGrp18ContinueTime DwnLoadDynLtgPrmForFrntLeGrp18HighBrightness DwnLoadDynLtgPrmForFrntLeGrp18LowBrightness DwnLoadDynLtgPrmForFrntLeGrp18Mode1 DwnLoadDynLtgPrmForFrntLeGrp18OffsetTime DwnLoadDynLtgPrmForFrntLeGrp18Timestamp;
SIG_GROUP_ 819 DwnLoadDynLtgPrmForFrntLeGrp19 1 : DwnLoadDynLtgPrmForFrntLeGrp19ContinueTime DwnLoadDynLtgPrmForFrntLeGrp19HighBrightness DwnLoadDynLtgPrmForFrntLeGrp19LowBrightness DwnLoadDynLtgPrmForFrntLeGrp19Mode1 DwnLoadDynLtgPrmForFrntLeGrp19OffsetTime DwnLoadDynLtgPrmForFrntLeGrp19Timestamp;
SIG_GROUP_ 802 DwnLoadDynLtgPrmForFrntLeGrp2 1 : DwnLoadDynLtgPrmForFrntLeGrp2ContinueTime DwnLoadDynLtgPrmForFrntLeGrp2HighBrightness DwnLoadDynLtgPrmForFrntLeGrp2LowBrightness DwnLoadDynLtgPrmForFrntLeGrp2Mode1 DwnLoadDynLtgPrmForFrntLeGrp2OffsetTime DwnLoadDynLtgPrmForFrntLeGrp2Timestamp;
SIG_GROUP_ 820 DwnLoadDynLtgPrmForFrntLeGrp20 1 : DwnLoadDynLtgPrmForFrntLeGrp20ContinueTime DwnLoadDynLtgPrmForFrntLeGrp20HighBrightness DwnLoadDynLtgPrmForFrntLeGrp20LowBrightness DwnLoadDynLtgPrmForFrntLeGrp20Mode1 DwnLoadDynLtgPrmForFrntLeGrp20OffsetTime DwnLoadDynLtgPrmForFrntLeGrp20Timestamp;
SIG_GROUP_ 821 DwnLoadDynLtgPrmForFrntLeGrp21 1 : DwnLoadDynLtgPrmForFrntLeGrp21ContinueTime DwnLoadDynLtgPrmForFrntLeGrp21HighBrightness DwnLoadDynLtgPrmForFrntLeGrp21LowBrightness DwnLoadDynLtgPrmForFrntLeGrp21Mode1 DwnLoadDynLtgPrmForFrntLeGrp21OffsetTime DwnLoadDynLtgPrmForFrntLeGrp21Timestamp;
SIG_GROUP_ 822 DwnLoadDynLtgPrmForFrntLeGrp22 1 : DwnLoadDynLtgPrmForFrntLeGrp22ContinueTime DwnLoadDynLtgPrmForFrntLeGrp22HighBrightness DwnLoadDynLtgPrmForFrntLeGrp22LowBrightness DwnLoadDynLtgPrmForFrntLeGrp22Mode1 DwnLoadDynLtgPrmForFrntLeGrp22OffsetTime DwnLoadDynLtgPrmForFrntLeGrp22Timestamp;
SIG_GROUP_ 823 DwnLoadDynLtgPrmForFrntLeGrp23 1 : DwnLoadDynLtgPrmForFrntLeGrp23ContinueTime DwnLoadDynLtgPrmForFrntLeGrp23HighBrightness DwnLoadDynLtgPrmForFrntLeGrp23LowBrightness DwnLoadDynLtgPrmForFrntLeGrp23Mode1 DwnLoadDynLtgPrmForFrntLeGrp23OffsetTime DwnLoadDynLtgPrmForFrntLeGrp23Timestamp;
SIG_GROUP_ 824 DwnLoadDynLtgPrmForFrntLeGrp24 1 : DwnLoadDynLtgPrmForFrntLeGrp24ContinueTime DwnLoadDynLtgPrmForFrntLeGrp24HighBrightness DwnLoadDynLtgPrmForFrntLeGrp24LowBrightness DwnLoadDynLtgPrmForFrntLeGrp24Mode1 DwnLoadDynLtgPrmForFrntLeGrp24OffsetTime DwnLoadDynLtgPrmForFrntLeGrp24Timestamp;
SIG_GROUP_ 803 DwnLoadDynLtgPrmForFrntLeGrp3 1 : DwnLoadDynLtgPrmForFrntLeGrp3ContinueTime DwnLoadDynLtgPrmForFrntLeGrp3HighBrightness DwnLoadDynLtgPrmForFrntLeGrp3LowBrightness DwnLoadDynLtgPrmForFrntLeGrp3Mode1 DwnLoadDynLtgPrmForFrntLeGrp3OffsetTime DwnLoadDynLtgPrmForFrntLeGrp3Timestamp;
SIG_GROUP_ 804 DwnLoadDynLtgPrmForFrntLeGrp4 1 : DwnLoadDynLtgPrmForFrntLeGrp4ContinueTime DwnLoadDynLtgPrmForFrntLeGrp4HighBrightness DwnLoadDynLtgPrmForFrntLeGrp4LowBrightness DwnLoadDynLtgPrmForFrntLeGrp4Mode1 DwnLoadDynLtgPrmForFrntLeGrp4OffsetTime DwnLoadDynLtgPrmForFrntLeGrp4Timestamp;
SIG_GROUP_ 805 DwnLoadDynLtgPrmForFrntLeGrp5 1 : DwnLoadDynLtgPrmForFrntLeGrp5ContinueTime DwnLoadDynLtgPrmForFrntLeGrp5HighBrightness DwnLoadDynLtgPrmForFrntLeGrp5LowBrightness DwnLoadDynLtgPrmForFrntLeGrp5Mode1 DwnLoadDynLtgPrmForFrntLeGrp5OffsetTime DwnLoadDynLtgPrmForFrntLeGrp5Timestamp;
SIG_GROUP_ 806 DwnLoadDynLtgPrmForFrntLeGrp6 1 : DwnLoadDynLtgPrmForFrntLeGrp6ContinueTime DwnLoadDynLtgPrmForFrntLeGrp6HighBrightness DwnLoadDynLtgPrmForFrntLeGrp6LowBrightness DwnLoadDynLtgPrmForFrntLeGrp6Mode1 DwnLoadDynLtgPrmForFrntLeGrp6OffsetTime DwnLoadDynLtgPrmForFrntLeGrp6Timestamp;
SIG_GROUP_ 807 DwnLoadDynLtgPrmForFrntLeGrp7 1 : DwnLoadDynLtgPrmForFrntLeGrp7ContinueTime DwnLoadDynLtgPrmForFrntLeGrp7HighBrightness DwnLoadDynLtgPrmForFrntLeGrp7LowBrightness DwnLoadDynLtgPrmForFrntLeGrp7Mode1 DwnLoadDynLtgPrmForFrntLeGrp7OffsetTime DwnLoadDynLtgPrmForFrntLeGrp7Timestamp;
SIG_GROUP_ 808 DwnLoadDynLtgPrmForFrntLeGrp8 1 : DwnLoadDynLtgPrmForFrntLeGrp8ContinueTime DwnLoadDynLtgPrmForFrntLeGrp8HighBrightness DwnLoadDynLtgPrmForFrntLeGrp8LowBrightness DwnLoadDynLtgPrmForFrntLeGrp8Mode1 DwnLoadDynLtgPrmForFrntLeGrp8OffsetTime DwnLoadDynLtgPrmForFrntLeGrp8Timestamp;
SIG_GROUP_ 809 DwnLoadDynLtgPrmForFrntLeGrp9 1 : DwnLoadDynLtgPrmForFrntLeGrp9ContinueTime DwnLoadDynLtgPrmForFrntLeGrp9HighBrightness DwnLoadDynLtgPrmForFrntLeGrp9LowBrightness DwnLoadDynLtgPrmForFrntLeGrp9Mode1 DwnLoadDynLtgPrmForFrntLeGrp9OffsetTime DwnLoadDynLtgPrmForFrntLeGrp9Timestamp;
SIG_GROUP_ 825 DwnLoadDynLtgPrmForFrntRIGrp1 1 : DwnLoadDynLtgPrmForFrntRIGrp1ContinueTime DwnLoadDynLtgPrmForFrntRIGrp1HighBrightness DwnLoadDynLtgPrmForFrntRIGrp1LowBrightness DwnLoadDynLtgPrmForFrntRIGrp1Mode1 DwnLoadDynLtgPrmForFrntRIGrp1OffsetTime DwnLoadDynLtgPrmForFrntRIGrp1Timestamp;
SIG_GROUP_ 826 DwnLoadDynLtgPrmForFrntRIGrp2 1 : DwnLoadDynLtgPrmForFrntRIGrp2ContinueTime DwnLoadDynLtgPrmForFrntRIGrp2HighBrightness DwnLoadDynLtgPrmForFrntRIGrp2LowBrightness DwnLoadDynLtgPrmForFrntRIGrp2Mode1 DwnLoadDynLtgPrmForFrntRIGrp2OffsetTime DwnLoadDynLtgPrmForFrntRIGrp2Timestamp;
SIG_GROUP_ 827 DwnLoadDynLtgPrmForFrntRIGrp3 1 : DwnLoadDynLtgPrmForFrntRIGrp3ContinueTime DwnLoadDynLtgPrmForFrntRIGrp3HighBrightness DwnLoadDynLtgPrmForFrntRIGrp3LowBrightness DwnLoadDynLtgPrmForFrntRIGrp3Mode1 DwnLoadDynLtgPrmForFrntRIGrp3OffsetTime DwnLoadDynLtgPrmForFrntRIGrp3Timestamp;
SIG_GROUP_ 828 DwnLoadDynLtgPrmForFrntRIGrp4 1 : DwnLoadDynLtgPrmForFrntRIGrp4ContinueTime DwnLoadDynLtgPrmForFrntRIGrp4HighBrightness DwnLoadDynLtgPrmForFrntRIGrp4LowBrightness DwnLoadDynLtgPrmForFrntRIGrp4Mode1 DwnLoadDynLtgPrmForFrntRIGrp4OffsetTime DwnLoadDynLtgPrmForFrntRIGrp4Timestamp;
SIG_GROUP_ 829 DwnLoadDynLtgPrmForFrntRIGrp5 1 : DwnLoadDynLtgPrmForFrntRIGrp5ContinueTime DwnLoadDynLtgPrmForFrntRIGrp5HighBrightness DwnLoadDynLtgPrmForFrntRIGrp5LowBrightness DwnLoadDynLtgPrmForFrntRIGrp5Mode1 DwnLoadDynLtgPrmForFrntRIGrp5OffsetTime DwnLoadDynLtgPrmForFrntRIGrp5Timestamp;
SIG_GROUP_ 830 DwnLoadDynLtgPrmForFrntRIGrp6 1 : DwnLoadDynLtgPrmForFrntRIGrp6ContinueTime DwnLoadDynLtgPrmForFrntRIGrp6HighBrightness DwnLoadDynLtgPrmForFrntRIGrp6LowBrightness DwnLoadDynLtgPrmForFrntRIGrp6Mode1 DwnLoadDynLtgPrmForFrntRIGrp6OffsetTime DwnLoadDynLtgPrmForFrntRIGrp6Timestamp;
SIG_GROUP_ 831 DwnLoadDynLtgPrmForFrntRIGrp7 1 : DwnLoadDynLtgPrmForFrntRIGrp7ContinueTime DwnLoadDynLtgPrmForFrntRIGrp7HighBrightness DwnLoadDynLtgPrmForFrntRIGrp7LowBrightness DwnLoadDynLtgPrmForFrntRIGrp7Mode1 DwnLoadDynLtgPrmForFrntRIGrp7OffsetTime DwnLoadDynLtgPrmForFrntRIGrp7Timestamp;
SIG_GROUP_ 832 DwnLoadDynLtgPrmForFrntRIGrp8 1 : DwnLoadDynLtgPrmForFrntRIGrp8ContinueTime DwnLoadDynLtgPrmForFrntRIGrp8HighBrightness DwnLoadDynLtgPrmForFrntRIGrp8LowBrightness DwnLoadDynLtgPrmForFrntRIGrp8Mode1 DwnLoadDynLtgPrmForFrntRIGrp8OffsetTime DwnLoadDynLtgPrmForFrntRIGrp8Timestamp;
SIG_GROUP_ 833 DwnLoadDynLtgPrmForFrntRIGrp9 1 : DwnLoadDynLtgPrmForFrntRIGrp9ContinueTime DwnLoadDynLtgPrmForFrntRIGrp9HighBrightness DwnLoadDynLtgPrmForFrntRIGrp9LowBrightness DwnLoadDynLtgPrmForFrntRIGrp9Mode1 DwnLoadDynLtgPrmForFrntRIGrp9OffsetTime DwnLoadDynLtgPrmForFrntRIGrp9Timestamp;
SIG_GROUP_ 790 VehCfgPrmExt2 1 : VehCfgPrmExt2BlkIDBytePosn1 VehCfgPrmExt2CCPBytePosn2 VehCfgPrmExt2CCPBytePosn3 VehCfgPrmExt2CCPBytePosn4 VehCfgPrmExt2CCPBytePosn5 VehCfgPrmExt2CCPBytePosn6 VehCfgPrmExt2CCPBytePosn7 VehCfgPrmExt2CCPBytePosn8;
